VERSION "dbc-export 1 2026.26.6.5"

NS_ :

BS_:

BU_: ADSP APB APP APS APSB BB BMS CC CMP CMPD CP DAS DI DIF DIR DPB EPAS3P EPAS3S EPASTP EPASTS EPBL EPBR ESP EVSE FC GTW HCML HCMR HVP IBST ICR IDB LS OCS1P ODIN PARK PCS PCS2 PLG PM PMF PMR PNCD PTC RADC RCM RCM2 RCM3 RCU SCCM SCM SCS SDCR TAS TCU TCU2 TPMS TRCM UDS UI UIS UMC USM V2G VC VCBATT VCBATT0 VCBATT1 VCBATT2 VCCC VCFRONT VCFRONT1 VCFRONT2 VCLEFT VCRIGHT VCSEAT2L VCSEAT2R VCSEC VEH

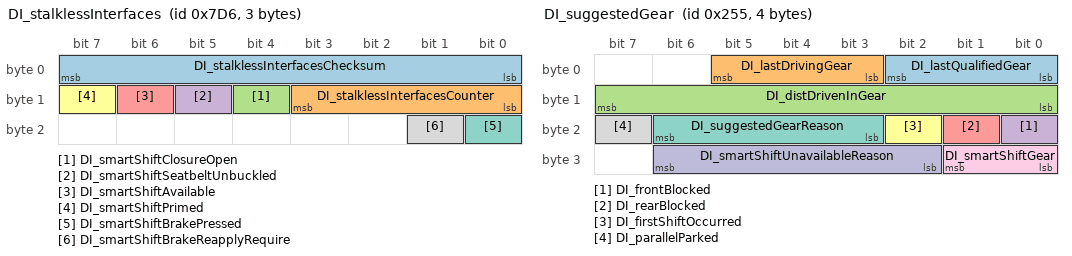
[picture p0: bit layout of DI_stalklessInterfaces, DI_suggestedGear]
BO_ 2006 DI_stalklessInterfaces: 3 DI
 SG_ DI_stalklessInterfacesChecksum : 0|8@1+ (1,0) [0|255] "" Vector__XXX
 SG_ DI_stalklessInterfacesCounter : 8|4@1+ (1,0) [0|15] "" Vector__XXX
 SG_ DI_smartShiftClosureOpen : 12|1@1+ (1,0) [0|1] "" Vector__XXX
 SG_ DI_smartShiftSeatbeltUnbuckled : 13|1@1+ (1,0) [0|1] "" Vector__XXX
 SG_ DI_smartShiftAvailable : 14|1@1+ (1,0) [0|1] "" Vector__XXX
 SG_ DI_smartShiftPrimed : 15|1@1+ (1,0) [0|1] "" Vector__XXX
 SG_ DI_smartShiftBrakePressed : 16|1@1+ (1,0) [0|1] "" Vector__XXX
 SG_ DI_smartShiftBrakeReapplyRequire : 17|1@1+ (1,0) [0|1] "" Vector__XXX

BO_ 597 DI_suggestedGear: 4 DI
 SG_ DI_lastQualifiedGear : 0|3@1+ (1,0) [0|6] "" Vector__XXX
 SG_ DI_lastDrivingGear : 3|3@1+ (1,0) [0|6] "" Vector__XXX
 SG_ DI_distDrivenInGear : 8|8@1+ (0.0235294122249,0) [0|6] "m" Vector__XXX
 SG_ DI_frontBlocked : 16|1@1+ (1,0) [0|1] "" Vector__XXX
 SG_ DI_rearBlocked : 17|1@1+ (1,0) [0|1] "" Vector__XXX
 SG_ DI_firstShiftOccurred : 18|1@1+ (1,0) [0|1] "" Vector__XXX
 SG_ DI_suggestedGearReason : 19|4@1+ (1,0) [0|15] "" Vector__XXX
 SG_ DI_parallelParked : 23|1@1+ (1,0) [0|1] "" Vector__XXX
 SG_ DI_smartShiftGear : 24|2@1+ (1,0) [0|3] "" Vector__XXX
 SG_ DI_smartShiftUnavailableReason : 26|5@1+ (1,0) [1|31] "" Vector__XXX

BO_ 296 DI_systemLimits: 6 DI
 SG_ DI_limitRegenPower : 0|1@1+ (1,0) [0|1] "" Vector__XXX
 SG_ DI_limitIBat : 1|1@1+ (1,0) [0|1] "" Vector__XXX
 SG_ DI_limitVBatLow : 2|1@1+ (1,0) [0|1] "" Vector__XXX
 SG_ DI_limitVBatHigh : 3|1@1+ (1,0) [0|1] "" Vector__XXX
 SG_ DI_limitObstacleDetection : 4|1@1+ (1,0) [0|1] "" Vector__XXX
 SG_ DI_limitSystemLimp : 5|1@1+ (1,0) [0|1] "" Vector__XXX
 SG_ DI_limitSystemGPO : 6|1@1+ (1,0) [0|1] "" Vector__XXX
 SG_ DI_limitShift : 7|1@1+ (1,0) [0|1] "" Vector__XXX
 SG_ DI_limitDriveTorque : 8|1@1+ (1,0) [0|1] "" Vector__XXX
 SG_ DI_limitRegenTorque : 9|1@1+ (1,0) [0|1] "" Vector__XXX
 SG_ DI_limitVehicleSpeed : 10|1@1+ (1,0) [0|1] "" Vector__XXX
 SG_ DI_limitBmsMiaFreeze : 11|1@1+ (1,0) [0|1] "" Vector__XXX
 SG_ DI_limitSystemSpinDownLearning : 12|1@1+ (1,0) [0|1] "" Vector__XXX
 SG_ DI_limitCdp : 13|1@1+ (1,0) [0|1] "" Vector__XXX
 SG_ DI_vehicleSpeedLimitType : 14|2@1+ (1,0) [0|3] "" Vector__XXX
 SG_ DI_vehicleSpeedLimit : 16|9@1+ (1,0) [0|510] "kph" Vector__XXX
 SG_ DI_vehicleSpeedLimitReason : 25|5@1+ (1,0) [0|31] "" Vector__XXX
 SG_ DI_proximity : 30|1@1+ (1,0) [0|1] "" Vector__XXX
 SG_ DI_limitClosureNotClosed : 31|1@1+ (1,0) [0|1] "" Vector__XXX
 SG_ DI_undersideAbuse : 32|1@1+ (1,0) [0|1] "" Vector__XXX
 SG_ DI_immobilizerAuthLevel : 33|2@1+ (1,0) [0|3] "" Vector__XXX
 SG_ DI_manualRecoveryDistanceRemaini : 40|7@1+ (5,0) [0|500] "m" Vector__XXX
 SG_ DI_restrictedDrivingMode : 47|1@1+ (1,0) [0|1] "" Vector__XXX

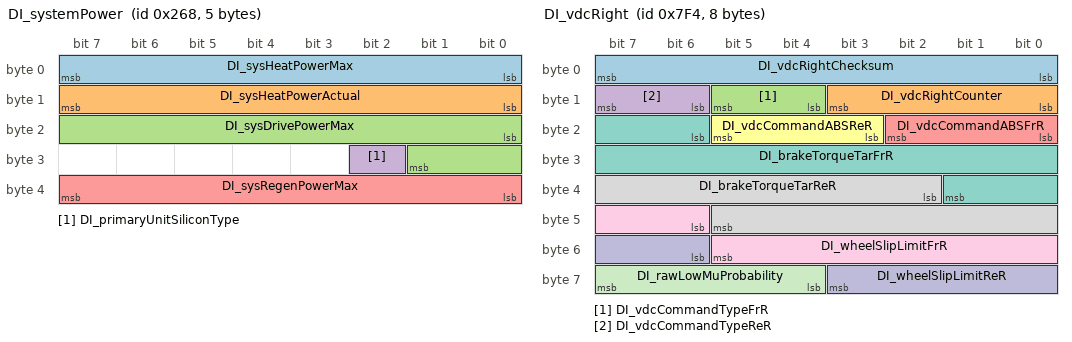
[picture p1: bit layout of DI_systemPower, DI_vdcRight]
BO_ 616 DI_systemPower: 5 DI
 SG_ DI_sysHeatPowerMax : 0|8@1+ (0.08,0) [0|20] "kW" Vector__XXX
 SG_ DI_sysHeatPowerActual : 8|8@1+ (0.08,0) [0|20] "kW" Vector__XXX
 SG_ DI_sysDrivePowerMax : 16|10@1+ (1,0) [0|1023] "kW" Vector__XXX
 SG_ DI_primaryUnitSiliconType : 26|1@1+ (1,0) [0|1] "" Vector__XXX
 SG_ DI_sysRegenPowerMax : 32|8@1+ (1,-100) [-100|0] "kW" Vector__XXX

BO_ 280 DI_systemStatus: 8 DI
 SG_ DI_systemStatusChecksum : 0|8@1+ (1,0) [0|255] "" Vector__XXX
 SG_ DI_systemStatusCounter : 8|4@1+ (1,0) [0|15] "" Vector__XXX
 SG_ DI_secondaryGearControlStatus : 12|1@1+ (1,0) [0|1] "" Vector__XXX
 SG_ DI_immobilizerState : 13|3@1+ (1,0) [1|7] "" Vector__XXX
 SG_ DI_systemState : 16|3@1+ (1,0) [0|7] "" Vector__XXX
 SG_ DI_brakePedalState : 19|2@1+ (1,0) [0|3] "" Vector__XXX
 SG_ DI_gear : 21|3@1+ (1,0) [0|6] "" Vector__XXX
 SG_ DI_driveBlocked : 24|3@1+ (1,0) [0|7] "" Vector__XXX
 SG_ DI_hvilSystemStatus : 27|2@1+ (1,0) [0|2] "" Vector__XXX
 SG_ DI_driveModeState : 29|1@1+ (1,0) [0|1] "" Vector__XXX
 SG_ DI_shiftRequestType : 30|2@1+ (1,0) [0|3] "" Vector__XXX
 SG_ DI_accelPedalPos : 32|8@1+ (0.4,0) [0|100] "%" Vector__XXX
 SG_ DI_tractionControlMode : 40|3@1+ (1,0) [0|7] "" Vector__XXX
 SG_ DI_dynoModeAvailable : 43|1@1+ (1,0) [0|1] "" Vector__XXX
 SG_ DI_epbRequest : 44|2@1+ (1,0) [0|3] "" Vector__XXX
 SG_ DI_brakeSource : 46|1@1+ (1,0) [0|1] "" Vector__XXX
 SG_ DI_keepDrivePowerStateRequest : 47|1@1+ (1,0) [0|1] "" Vector__XXX
 SG_ DI_trackModeState : 48|2@1+ (1,0) [0|3] "" Vector__XXX
 SG_ DI_autonomyControlActive : 50|1@1+ (1,0) [0|1] "" Vector__XXX
 SG_ DI_regenLight : 51|1@1+ (1,0) [0|1] "" Vector__XXX
 SG_ DI_vehicleAcceleration : 52|12@1- (0.01,0) [-20.47|20.47] "m/s^2" Vector__XXX

BO_ 2036 DI_vdcRight: 8 DI
 SG_ DI_vdcRightChecksum : 0|8@1+ (1,0) [0|255] "" Vector__XXX
 SG_ DI_vdcRightCounter : 8|4@1+ (1,0) [0|15] "" Vector__XXX
 SG_ DI_vdcCommandTypeFrR : 12|2@1+ (1,0) [0|3] "" Vector__XXX
 SG_ DI_vdcCommandTypeReR : 14|2@1+ (1,0) [0|3] "" Vector__XXX
 SG_ DI_vdcCommandABSFrR : 16|3@1+ (1,0) [0|7] "" Vector__XXX
 SG_ DI_vdcCommandABSReR : 19|3@1+ (1,0) [0|7] "" Vector__XXX
 SG_ DI_brakeTorqueTarFrR : 22|12@1+ (3,-3) [-3|12282] "Nm" Vector__XXX
 SG_ DI_brakeTorqueTarReR : 34|12@1+ (3,-3) [-3|12282] "Nm" Vector__XXX
 SG_ DI_wheelSlipLimitFrR : 46|8@1+ (0.004,-0.004) [-0.004|1] "1" Vector__XXX
 SG_ DI_wheelSlipLimitReR : 54|6@1+ (0.004,-0.004) [-0.004|0.248] "1" Vector__XXX
 SG_ DI_rawLowMuProbability : 60|4@1+ (0.06666667,0) [0|1] "-" Vector__XXX

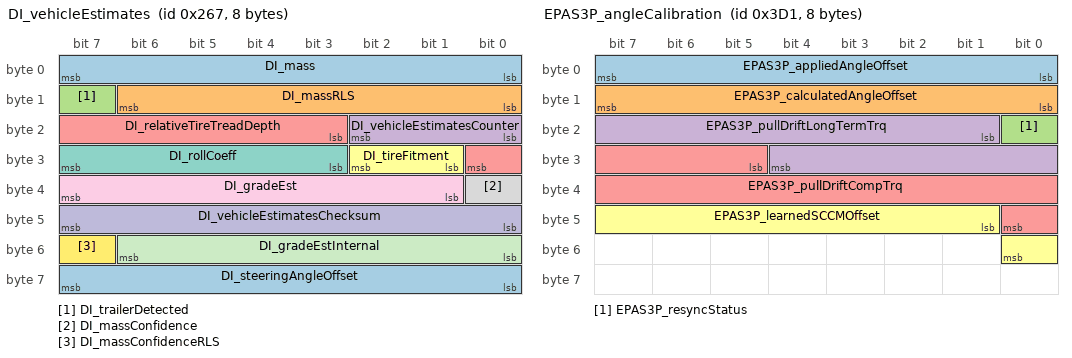
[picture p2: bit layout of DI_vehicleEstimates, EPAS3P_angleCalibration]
BO_ 615 DI_vehicleEstimates: 8 DI
 SG_ DI_mass : 0|8@1+ (25,1500) [1500|7850] "kg" Vector__XXX
 SG_ DI_massRLS : 8|7@1+ (45,1500) [1500|7170] "kg" Vector__XXX
 SG_ DI_trailerDetected : 15|1@1+ (1,0) [0|1] "" Vector__XXX
 SG_ DI_vehicleEstimatesCounter : 16|3@1+ (1,0) [0|7] "" Vector__XXX
 SG_ DI_relativeTireTreadDepth : 19|6@1- (0.4,0) [-12.4|12.4] "mm" Vector__XXX
 SG_ DI_tireFitment : 25|2@1+ (1,0) [0|2] "" Vector__XXX
 SG_ DI_rollCoeff : 27|5@1+ (0.001,0) [0|0.03] "g" Vector__XXX
 SG_ DI_massConfidence : 32|1@1+ (1,0) [0|1] "" Vector__XXX
 SG_ DI_gradeEst : 33|7@1- (1,0) [-40|40] "%" Vector__XXX
 SG_ DI_vehicleEstimatesChecksum : 40|8@1+ (1,0) [0|255] "" Vector__XXX
 SG_ DI_gradeEstInternal : 48|7@1- (1,0) [-40|40] "%" Vector__XXX
 SG_ DI_massConfidenceRLS : 55|1@1+ (1,0) [0|1] "" Vector__XXX
 SG_ DI_steeringAngleOffset : 56|8@1- (0.2,0) [-25.6|25.4] "Deg" Vector__XXX

BO_ 1237 DPB_alertLog: 8 DPB
 SG_ DPB_alertID : 0|9@1+ (1,0) [0|511] "" Vector__XXX
 SG_ DPB_alertState : 15|1@1+ (1,0) [0|1] "" Vector__XXX

BO_ 999 DPB_alertMatrix: 8 DPB
 SG_ DPB_matrixIndex M : 0|4@1+ (1,0) [0|15] "" Vector__XXX
 SG_ DPB_a001_pPlungerSensorOffsetHig m0 : 4|1@1+ (1,0) [0|1] "" Vector__XXX
 SG_ DPB_a002_pMC2SensorOffsetHigh m0 : 5|1@1+ (1,0) [0|1] "" Vector__XXX
 SG_ DPB_a003_AswEEPROMReadFailure m0 : 6|1@1+ (1,0) [0|1] "" Vector__XXX
 SG_ DPB_a004_assertionFault m0 : 7|1@1+ (1,0) [0|1] "" Vector__XXX
 SG_ DPB_a005_hardPedalChar m0 : 8|1@1+ (1,0) [0|1] "" Vector__XXX
 SG_ DPB_a006_hardPedalCharGoodCheck m0 : 9|1@1+ (1,0) [0|1] "" Vector__XXX
 SG_ DPB_a007_PMCLeakageDetected m0 : 10|1@1+ (1,0) [0|1] "" Vector__XXX
 SG_ DPB_a008_LiPSPts1Offset m0 : 11|1@1+ (1,0) [0|1] "" Vector__XXX
 SG_ DPB_a009_LiPSPts2Offset m0 : 12|1@1+ (1,0) [0|1] "" Vector__XXX
 SG_ DPB_a010_LiPSPtsConsistency m0 : 13|1@1+ (1,0) [0|1] "" Vector__XXX
 SG_ DPB_a011_PtsNonZeroStage1 m0 : 14|1@1+ (1,0) [0|1] "" Vector__XXX
 SG_ DPB_a012_PtsNonZeroStage2 m0 : 15|1@1+ (1,0) [0|1] "" Vector__XXX
 SG_ DPB_a013_softPedalChar m0 : 16|1@1+ (1,0) [0|1] "" Vector__XXX
 SG_ DPB_a014_CANControllerHWFault m0 : 17|1@1+ (1,0) [0|1] "" Vector__XXX
 SG_ DPB_a015_CAN1BusOff m0 : 18|1@1+ (1,0) [0|1] "" Vector__XXX
 SG_ DPB_a016_CAN2BusOff m0 : 19|1@1+ (1,0) [0|1] "" Vector__XXX
 SG_ DPB_a017_largeLeakageDetected m0 : 20|1@1+ (1,0) [0|1] "" Vector__XXX
 SG_ DPB_a018_largeLeakageDetectedGoo m0 : 21|1@1+ (1,0) [0|1] "" Vector__XXX
 SG_ DPB_a019_DETReportError m0 : 22|1@1+ (1,0) [0|1] "" Vector__XXX
 SG_ DPB_a020_ecuHuMismatch m0 : 23|1@1+ (1,0) [0|1] "" Vector__XXX
 SG_ DPB_a021_brakeSystemOverheatLvl1 m0 : 24|1@1+ (1,0) [0|1] "" Vector__XXX
 SG_ DPB_a022_brakeSystemOverheatLvl2 m0 : 25|1@1+ (1,0) [0|1] "" Vector__XXX
 SG_ DPB_a023_initialPlungerCheckFail m0 : 26|1@1+ (1,0) [0|1] "" Vector__XXX
 SG_ DPB_a024_ESPLDMFailure m0 : 27|1@1+ (1,0) [0|1] "" Vector__XXX
 SG_ DPB_a025_backupCircuitLeakage m0 : 28|1@1+ (1,0) [0|1] "" Vector__XXX
 SG_ DPB_a026_LiPSIDTimeout m0 : 29|1@1+ (1,0) [0|1] "" Vector__XXX
 SG_ DPB_a027_motorTempHighLevel1 m0 : 30|1@1+ (1,0) [0|1] "" Vector__XXX
 SG_ DPB_a028_motorTempHighLevel2 m0 : 31|1@1+ (1,0) [0|1] "" Vector__XXX
 SG_ DPB_a029_motorTestFault m0 : 32|1@1+ (1,0) [0|1] "" Vector__XXX
 SG_ DPB_a030_notShutDownRight m0 : 33|1@1+ (1,0) [0|1] "" Vector__XXX
 SG_ DPB_a031_HWParamReadFailed m0 : 34|1@1+ (1,0) [0|1] "" Vector__XXX
 SG_ DPB_a032_HWParamWriteFailed m0 : 35|1@1+ (1,0) [0|1] "" Vector__XXX
 SG_ DPB_a033_motorDynamicLimited m0 : 36|1@1+ (1,0) [0|1] "" Vector__XXX
 SG_ DPB_a034_lipsMemoryEmpty m0 : 37|1@1+ (1,0) [0|1] "" Vector__XXX
 SG_ DPB_a035_PDURouterinitialization m0 : 38|1@1+ (1,0) [0|1] "" Vector__XXX
 SG_ DPB_a036_lossOfPDUInstanceDetect m0 : 39|1@1+ (1,0) [0|1] "" Vector__XXX
 SG_ DPB_a037_plungerCircuitPressHigh m0 : 40|1@1+ (1,0) [0|1] "" Vector__XXX
 SG_ DPB_a038_plungerCircuitPressHigh m0 : 41|1@1+ (1,0) [0|1] "" Vector__XXX
 SG_ DPB_a039_plungerCircuitPressLow m0 : 42|1@1+ (1,0) [0|1] "" Vector__XXX
 SG_ DPB_a040_plungerCircuitPressLowG m0 : 43|1@1+ (1,0) [0|1] "" Vector__XXX
 SG_ DPB_a041_PSCGearRatioReadFault m0 : 44|1@1+ (1,0) [0|1] "" Vector__XXX
 SG_ DPB_a042_motorLoadPressImplausib m0 : 45|1@1+ (1,0) [0|1] "" Vector__XXX
 SG_ DPB_a043_PSCMotorSizeReadFault m0 : 46|1@1+ (1,0) [0|1] "" Vector__XXX
 SG_ DPB_a044_supplyOvervoltageLvl1 m0 : 47|1@1+ (1,0) [0|1] "" Vector__XXX
 SG_ DPB_a045_supplyOvervoltageLvl2 m0 : 48|1@1+ (1,0) [0|1] "" Vector__XXX
 SG_ DPB_a046_supplyOvervoltageLvl3 m0 : 49|1@1+ (1,0) [0|1] "" Vector__XXX
 SG_ DPB_a047_pPlungerPlausCheckFailu m0 : 50|1@1+ (1,0) [0|1] "" Vector__XXX
 SG_ DPB_a048_supplyUndervoltageLvl1 m0 : 51|1@1+ (1,0) [0|1] "" Vector__XXX
 SG_ DPB_a049_supplyUndervoltageLvl2 m0 : 52|1@1+ (1,0) [0|1] "" Vector__XXX
 SG_ DPB_a050_supplyUndervoltageLvl3 m0 : 53|1@1+ (1,0) [0|1] "" Vector__XXX
 SG_ DPB_a051_PSCVoltageImplausible m0 : 54|1@1+ (1,0) [0|1] "" Vector__XXX
 SG_ DPB_a052_PSIDTimeOut m0 : 55|1@1+ (1,0) [0|1] "" Vector__XXX
 SG_ DPB_a053_hydraulicAssemblyModeAc m0 : 56|1@1+ (1,0) [0|1] "" Vector__XXX
 SG_ DPB_a054_unsupportedHW m0 : 57|1@1+ (1,0) [0|1] "" Vector__XXX
 SG_ DPB_a055_unsupportedSeriesHWDete m0 : 58|1@1+ (1,0) [0|1] "" Vector__XXX
 SG_ DPB_a056_AdcPeripheralFault m0 : 59|1@1+ (1,0) [0|1] "" Vector__XXX
 SG_ DPB_a057_AdcPinTest m0 : 60|1@1+ (1,0) [0|1] "" Vector__XXX
 SG_ DPB_a058_AdcSelftestC5P m0 : 61|1@1+ (1,0) [0|1] "" Vector__XXX
 SG_ DPB_a059_factoryModeActive m0 : 62|1@1+ (1,0) [0|1] "" Vector__XXX
 SG_ DPB_a060_motorBridgeDriverFault m0 : 63|1@1+ (1,0) [0|1] "" Vector__XXX
 SG_ DPB_a061_bridgeSwitchInitError m1 : 4|1@1+ (1,0) [0|1] "" Vector__XXX
 SG_ DPB_a062_loadDumpOnFSLTest m1 : 5|1@1+ (1,0) [0|1] "" Vector__XXX
 SG_ DPB_a063_motorConfigMismatch m1 : 6|1@1+ (1,0) [0|1] "" Vector__XXX
 SG_ DPB_a064_current1OffsetHigh m1 : 7|1@1+ (1,0) [0|1] "" Vector__XXX
 SG_ DPB_a065_current1OffsetLow m1 : 8|1@1+ (1,0) [0|1] "" Vector__XXX
 SG_ DPB_a066_current2OffsetHigh m1 : 9|1@1+ (1,0) [0|1] "" Vector__XXX
 SG_ DPB_a067_current2OffsetLow m1 : 10|1@1+ (1,0) [0|1] "" Vector__XXX
 SG_ DPB_a068_BLMMuxerTimeoutError m1 : 11|1@1+ (1,0) [0|1] "" Vector__XXX
 SG_ DPB_a069_OBDCurrent1OORHigh m1 : 12|1@1+ (1,0) [0|1] "" Vector__XXX
 SG_ DPB_a070_OBDCurrent1OORLow m1 : 13|1@1+ (1,0) [0|1] "" Vector__XXX
 SG_ DPB_a071_OBDCurrent2OORHigh m1 : 14|1@1+ (1,0) [0|1] "" Vector__XXX
 SG_ DPB_a072_OBDCurrent2OORLow m1 : 15|1@1+ (1,0) [0|1] "" Vector__XXX
 SG_ DPB_a073_rotorCosOutOfRangeHigh m1 : 16|1@1+ (1,0) [0|1] "" Vector__XXX
 SG_ DPB_a074_rotorCosOutOfRangeLow m1 : 17|1@1+ (1,0) [0|1] "" Vector__XXX
 SG_ DPB_a075_rotorSinOutOfRangeHigh m1 : 18|1@1+ (1,0) [0|1] "" Vector__XXX
 SG_ DPB_a076_rotorSinOutOfRangeLow m1 : 19|1@1+ (1,0) [0|1] "" Vector__XXX
 SG_ DPB_a077_tempSens1ShortToSupply m1 : 20|1@1+ (1,0) [0|1] "" Vector__XXX
 SG_ DPB_a078_tempSens1ShortToGround m1 : 21|1@1+ (1,0) [0|1] "" Vector__XXX
 SG_ DPB_a079_tempSens2ShortToSupply m1 : 22|1@1+ (1,0) [0|1] "" Vector__XXX
 SG_ DPB_a080_tempSens2ShortToGround m1 : 23|1@1+ (1,0) [0|1] "" Vector__XXX
 SG_ DPB_a081_tempSensImplausVoltage m1 : 24|1@1+ (1,0) [0|1] "" Vector__XXX
 SG_ DPB_a082_chargePumpFault m1 : 25|1@1+ (1,0) [0|1] "" Vector__XXX
 SG_ DPB_a083_chargePumpUndervoltage m1 : 26|1@1+ (1,0) [0|1] "" Vector__XXX
 SG_ DPB_a084_RBCPUException m1 : 27|1@1+ (1,0) [0|1] "" Vector__XXX
 SG_ DPB_a085_infoFailureWrongCUBASHa m1 : 28|1@1+ (1,0) [0|1] "" Vector__XXX
 SG_ DPB_a086_diagHydProtectionPressF m1 : 29|1@1+ (1,0) [0|1] "" Vector__XXX
 SG_ DPB_a087_diagHydProtectionVlvFau m1 : 30|1@1+ (1,0) [0|1] "" Vector__XXX
 SG_ DPB_a088_DMATransferError m1 : 31|1@1+ (1,0) [0|1] "" Vector__XXX
 SG_ DPB_a089_ecuBandgap m1 : 32|1@1+ (1,0) [0|1] "" Vector__XXX
 SG_ DPB_a090_flashFault m1 : 33|1@1+ (1,0) [0|1] "" Vector__XXX
 SG_ DPB_a091_MRGPathTestFault m1 : 34|1@1+ (1,0) [0|1] "" Vector__XXX
 SG_ DPB_a092_decoupleBitTestFault m1 : 35|1@1+ (1,0) [0|1] "" Vector__XXX
 SG_ DPB_a093_ecuBistFaultCtrFault m1 : 36|1@1+ (1,0) [0|1] "" Vector__XXX
 SG_ DPB_a094_ecuClockTestFault m1 : 37|1@1+ (1,0) [0|1] "" Vector__XXX
 SG_ DPB_a095_ecuEnableElHighFault m1 : 38|1@1+ (1,0) [0|1] "" Vector__XXX
 SG_ DPB_a096_ecuEnableElLowFault m1 : 39|1@1+ (1,0) [0|1] "" Vector__XXX
 SG_ DPB_a097_ecuEnableHyHighFault m1 : 40|1@1+ (1,0) [0|1] "" Vector__XXX
 SG_ DPB_a098_ecuEnableHyLowFault m1 : 41|1@1+ (1,0) [0|1] "" Vector__XXX
 SG_ DPB_a099_ecuEnContinuousError m1 : 42|1@1+ (1,0) [0|1] "" Vector__XXX
 SG_ DPB_a100_ecuErrpinCounterFault m1 : 43|1@1+ (1,0) [0|1] "" Vector__XXX
 SG_ DPB_a101_ecuFastWdTestFault m1 : 44|1@1+ (1,0) [0|1] "" Vector__XXX
 SG_ DPB_a102_ecuVrOnWhileWdTimeout m1 : 45|1@1+ (1,0) [0|1] "" Vector__XXX
 SG_ DPB_a103_ecuVrViaSpiFails m1 : 46|1@1+ (1,0) [0|1] "" Vector__XXX
 SG_ DPB_a104_ecuWdStartuptestFault m1 : 47|1@1+ (1,0) [0|1] "" Vector__XXX
 SG_ DPB_a105_ecuWdSContinuousError m1 : 48|1@1+ (1,0) [0|1] "" Vector__XXX
 SG_ DPB_a106_ecuBistCmdTestFault m1 : 49|1@1+ (1,0) [0|1] "" Vector__XXX
 SG_ DPB_a107_vrOnFails m1 : 50|1@1+ (1,0) [0|1] "" Vector__XXX
 SG_ DPB_a108_GTMRefFrequencyError m1 : 51|1@1+ (1,0) [0|1] "" Vector__XXX
 SG_ DPB_a109_GTMTbuMonError m1 : 52|1@1+ (1,0) [0|1] "" Vector__XXX
 SG_ DPB_a110_HWBISTError m1 : 53|1@1+ (1,0) [0|1] "" Vector__XXX
 SG_ DPB_a111_hydraulicHardUndervolta m1 : 54|1@1+ (1,0) [0|1] "" Vector__XXX
 SG_ DPB_a112_hydraulicUndervoltage m1 : 55|1@1+ (1,0) [0|1] "" Vector__XXX
 SG_ DPB_a113_LiPS1SentLineHigh m1 : 56|1@1+ (1,0) [0|1] "" Vector__XXX
 SG_ DPB_a114_LiPS1SentLineLow m1 : 57|1@1+ (1,0) [0|1] "" Vector__XXX
 SG_ DPB_a115_LiPS1SentSensor m1 : 58|1@1+ (1,0) [0|1] "" Vector__XXX
 SG_ DPB_a116_LiPS1SentTransmission m1 : 59|1@1+ (1,0) [0|1] "" Vector__XXX
 SG_ DPB_a117_LiPS2PwmLineHigh m1 : 60|1@1+ (1,0) [0|1] "" Vector__XXX
 SG_ DPB_a118_LiPS2PwmLineLow m1 : 61|1@1+ (1,0) [0|1] "" Vector__XXX
 SG_ DPB_a119_LiPS2PwmTransmission m1 : 62|1@1+ (1,0) [0|1] "" Vector__XXX
 SG_ DPB_a120_LiPSOutOfRangeHigh m1 : 63|1@1+ (1,0) [0|1] "" Vector__XXX
 SG_ DPB_a121_LiPSOutOfRangeLow m2 : 4|1@1+ (1,0) [0|1] "" Vector__XXX
 SG_ DPB_a122_micAsicClkInError m2 : 5|1@1+ (1,0) [0|1] "" Vector__XXX
 SG_ DPB_a123_micAsicInitTestError m2 : 6|1@1+ (1,0) [0|1] "" Vector__XXX
 SG_ DPB_a124_asicOscillatorError m2 : 7|1@1+ (1,0) [0|1] "" Vector__XXX
 SG_ DPB_a125_B6AsicFault m2 : 8|1@1+ (1,0) [0|1] "" Vector__XXX
 SG_ DPB_a126_MICB6TransferError m2 : 9|1@1+ (1,0) [0|1] "" Vector__XXX
 SG_ DPB_a127_hydraulicAsicShortCircu m2 : 10|1@1+ (1,0) [0|1] "" Vector__XXX
 SG_ DPB_a128_micSpiTransferError m2 : 11|1@1+ (1,0) [0|1] "" Vector__XXX
 SG_ DPB_a129_AsicTrimmingNotComplete m2 : 12|1@1+ (1,0) [0|1] "" Vector__XXX
 SG_ DPB_a130_AsicMalfunctionDetected m2 : 13|1@1+ (1,0) [0|1] "" Vector__XXX
 SG_ DPB_a131_ASICOvercurrentOnGPIO25 m2 : 14|1@1+ (1,0) [0|1] "" Vector__XXX
 SG_ DPB_a132_ASICOvercurrentOnGPIO25 m2 : 15|1@1+ (1,0) [0|1] "" Vector__XXX
 SG_ DPB_a133_ASICOvercurrentOnGPIO50 m2 : 16|1@1+ (1,0) [0|1] "" Vector__XXX
 SG_ DPB_a134_ASICOvercurrentOnGPIO50 m2 : 17|1@1+ (1,0) [0|1] "" Vector__XXX
 SG_ DPB_a135_ASICOvercurrentOnGPIO50 m2 : 18|1@1+ (1,0) [0|1] "" Vector__XXX
 SG_ DPB_a136_ASICOvercurrentOnGPIO50 m2 : 19|1@1+ (1,0) [0|1] "" Vector__XXX
 SG_ DPB_a137_ASICOvercurrentOnWRHS m2 : 20|1@1+ (1,0) [0|1] "" Vector__XXX
 SG_ DPB_a138_DIchassisControlCounter m2 : 21|1@1+ (1,0) [0|1] "" Vector__XXX
 SG_ DPB_a139_DIchassisControlChecksu m2 : 22|1@1+ (1,0) [0|1] "" Vector__XXX
 SG_ DPB_a140_DIchassisControlDLC m2 : 23|1@1+ (1,0) [0|1] "" Vector__XXX
 SG_ DPB_a141_DIchassisControlTimeout m2 : 24|1@1+ (1,0) [0|1] "" Vector__XXX
 SG_ DPB_a142_DIsystemStatusCounter m2 : 25|1@1+ (1,0) [0|1] "" Vector__XXX
 SG_ DPB_a143_DIsystemStatusChecksum m2 : 26|1@1+ (1,0) [0|1] "" Vector__XXX
 SG_ DPB_a144_DIsystemStatusDLC m2 : 27|1@1+ (1,0) [0|1] "" Vector__XXX
 SG_ DPB_a145_DIsystemStatusTimeout m2 : 28|1@1+ (1,0) [0|1] "" Vector__XXX
 SG_ DPB_a146_DIFtorqueCounter m2 : 29|1@1+ (1,0) [0|1] "" Vector__XXX
 SG_ DPB_a147_DIFtorqueChecksum m2 : 30|1@1+ (1,0) [0|1] "" Vector__XXX
 SG_ DPB_a148_DIFtorqueDLC m2 : 31|1@1+ (1,0) [0|1] "" Vector__XXX
 SG_ DPB_a149_DIFtorqueTimeout m2 : 32|1@1+ (1,0) [0|1] "" Vector__XXX
 SG_ DPB_a150_DIRtorqueCounter m2 : 33|1@1+ (1,0) [0|1] "" Vector__XXX
 SG_ DPB_a151_DIRtorqueChecksum m2 : 34|1@1+ (1,0) [0|1] "" Vector__XXX
 SG_ DPB_a152_DIRtorqueDLC m2 : 35|1@1+ (1,0) [0|1] "" Vector__XXX
 SG_ DPB_a153_DIRtorqueTimeout m2 : 36|1@1+ (1,0) [0|1] "" Vector__XXX
 SG_ DPB_a154_EPBLstatusCounter m2 : 37|1@1+ (1,0) [0|1] "" Vector__XXX
 SG_ DPB_a155_EPBLstatusChecksum m2 : 38|1@1+ (1,0) [0|1] "" Vector__XXX
 SG_ DPB_a156_EPBLstatusDLC m2 : 39|1@1+ (1,0) [0|1] "" Vector__XXX
 SG_ DPB_a157_EPBLstatusTimeout m2 : 40|1@1+ (1,0) [0|1] "" Vector__XXX
 SG_ DPB_a158_EPBRstatusCounter m2 : 41|1@1+ (1,0) [0|1] "" Vector__XXX
 SG_ DPB_a159_EPBRstatusChecksum m2 : 42|1@1+ (1,0) [0|1] "" Vector__XXX
 SG_ DPB_a160_EPBRstatusDLC m2 : 43|1@1+ (1,0) [0|1] "" Vector__XXX
 SG_ DPB_a161_EPBRstatusTimeout m2 : 44|1@1+ (1,0) [0|1] "" Vector__XXX
 SG_ DPB_a162_ESP_modulator1Counter m2 : 45|1@1+ (1,0) [0|1] "" Vector__XXX
 SG_ DPB_a163_ESP_modulator1Checksum m2 : 46|1@1+ (1,0) [0|1] "" Vector__XXX
 SG_ DPB_a164_ESP_modulator1DLC m2 : 47|1@1+ (1,0) [0|1] "" Vector__XXX
 SG_ DPB_a165_ESP_modulator1Timeout m2 : 48|1@1+ (1,0) [0|1] "" Vector__XXX
 SG_ DPB_a166_ESP_chassis3Counter m2 : 49|1@1+ (1,0) [0|1] "" Vector__XXX
 SG_ DPB_a167_ESP_chassis3Checksum m2 : 50|1@1+ (1,0) [0|1] "" Vector__XXX
 SG_ DPB_a168_ESP_chassis3DLC m2 : 51|1@1+ (1,0) [0|1] "" Vector__XXX
 SG_ DPB_a169_ESP_chassis3Timeout m2 : 52|1@1+ (1,0) [0|1] "" Vector__XXX
 SG_ DPB_a170_ESP_modulator2Counter m2 : 53|1@1+ (1,0) [0|1] "" Vector__XXX
 SG_ DPB_a171_ESP_modulator2Checksum m2 : 54|1@1+ (1,0) [0|1] "" Vector__XXX
 SG_ DPB_a172_ESP_modulator2DLC m2 : 55|1@1+ (1,0) [0|1] "" Vector__XXX
 SG_ DPB_a173_ESP_modulator2Timeout m2 : 56|1@1+ (1,0) [0|1] "" Vector__XXX
 SG_ DPB_a174_ESP_modulator3Counter m2 : 57|1@1+ (1,0) [0|1] "" Vector__XXX
 SG_ DPB_a175_ESP_modulator3Checksum m2 : 58|1@1+ (1,0) [0|1] "" Vector__XXX
 SG_ DPB_a176_ESP_modulator3DLC m2 : 59|1@1+ (1,0) [0|1] "" Vector__XXX
 SG_ DPB_a177_ESP_modulator3Timeout m2 : 60|1@1+ (1,0) [0|1] "" Vector__XXX
 SG_ DPB_a178_PMstate2Counter m2 : 61|1@1+ (1,0) [0|1] "" Vector__XXX
 SG_ DPB_a179_PMstate2Checksum m2 : 62|1@1+ (1,0) [0|1] "" Vector__XXX
 SG_ DPB_a180_PMstate2DLC m2 : 63|1@1+ (1,0) [0|1] "" Vector__XXX
 SG_ DPB_a181_PMstate2Timeout m3 : 4|1@1+ (1,0) [0|1] "" Vector__XXX
 SG_ DPB_a182_RCMInertial2Counter m3 : 5|1@1+ (1,0) [0|1] "" Vector__XXX
 SG_ DPB_a183_RCMInertial2Checksum m3 : 6|1@1+ (1,0) [0|1] "" Vector__XXX
 SG_ DPB_a184_RCMInertial2DLC m3 : 7|1@1+ (1,0) [0|1] "" Vector__XXX
 SG_ DPB_a185_RCMInertial2Timeout m3 : 8|1@1+ (1,0) [0|1] "" Vector__XXX
 SG_ DPB_a186_LVPowerStateTimeout m3 : 9|1@1+ (1,0) [0|1] "" Vector__XXX
 SG_ DPB_a187_LVPowerStateChecksum m3 : 10|1@1+ (1,0) [0|1] "" Vector__XXX
 SG_ DPB_a188_LVPowerStateDLC m3 : 11|1@1+ (1,0) [0|1] "" Vector__XXX
 SG_ DPB_a189_LVPowerStateCounter m3 : 12|1@1+ (1,0) [0|1] "" Vector__XXX
 SG_ DPB_a190_VCLEFTepbmStatusCounter m3 : 13|1@1+ (1,0) [0|1] "" Vector__XXX
 SG_ DPB_a191_VCLEFTepbmStatusChecksu m3 : 14|1@1+ (1,0) [0|1] "" Vector__XXX
 SG_ DPB_a192_VCLEFTepbmStatusDLC m3 : 15|1@1+ (1,0) [0|1] "" Vector__XXX
 SG_ DPB_a193_VCLEFTepbmStatusTimeout m3 : 16|1@1+ (1,0) [0|1] "" Vector__XXX
 SG_ DPB_a194_VCRIGHTepbmStatusCounte m3 : 17|1@1+ (1,0) [0|1] "" Vector__XXX
 SG_ DPB_a195_VCRIGHTepbmStatusChecks m3 : 18|1@1+ (1,0) [0|1] "" Vector__XXX
 SG_ DPB_a196_VCRIGHTepbmStatusDLC m3 : 19|1@1+ (1,0) [0|1] "" Vector__XXX
 SG_ DPB_a197_VCRIGHTepbmStatusTimeou m3 : 20|1@1+ (1,0) [0|1] "" Vector__XXX
 SG_ DPB_a198_CANOvervoltage m3 : 21|1@1+ (1,0) [0|1] "" Vector__XXX
 SG_ DPB_a199_pMC1QFaulty m3 : 22|1@1+ (1,0) [0|1] "" Vector__XXX
 SG_ DPB_a200_ESPRunoutSupportNotAvai m3 : 23|1@1+ (1,0) [0|1] "" Vector__XXX
 SG_ DPB_a201_vehicleSpeedQFaulty m3 : 24|1@1+ (1,0) [0|1] "" Vector__XXX
 SG_ DPB_a202_vehicleStandstillQFault m3 : 25|1@1+ (1,0) [0|1] "" Vector__XXX
 SG_ DPB_a203_ABSNotAvailable m3 : 26|1@1+ (1,0) [0|1] "" Vector__XXX
 SG_ DPB_a204_CANUndervoltage m3 : 27|1@1+ (1,0) [0|1] "" Vector__XXX
 SG_ DPB_a205_NvMWriteCycleExceed m3 : 28|1@1+ (1,0) [0|1] "" Vector__XXX
 SG_ DPB_a206_OSTaskSchemeError m3 : 29|1@1+ (1,0) [0|1] "" Vector__XXX
 SG_ DPB_a207_hydraulicOvervoltage m3 : 30|1@1+ (1,0) [0|1] "" Vector__XXX
 SG_ DPB_a208_pressureSensor1Short m3 : 31|1@1+ (1,0) [0|1] "" Vector__XXX
 SG_ DPB_a209_pressureSensor1High m3 : 32|1@1+ (1,0) [0|1] "" Vector__XXX
 SG_ DPB_a210_pressureSensor1Low m3 : 33|1@1+ (1,0) [0|1] "" Vector__XXX
 SG_ DPB_a211_pressureSensor1Fault m3 : 34|1@1+ (1,0) [0|1] "" Vector__XXX
 SG_ DPB_a212_pressureSensor1Temp m3 : 35|1@1+ (1,0) [0|1] "" Vector__XXX
 SG_ DPB_a213_pressureSensor1Fault m3 : 36|1@1+ (1,0) [0|1] "" Vector__XXX
 SG_ DPB_a214_pressureSensor2Short m3 : 37|1@1+ (1,0) [0|1] "" Vector__XXX
 SG_ DPB_a215_pressureSensor2High m3 : 38|1@1+ (1,0) [0|1] "" Vector__XXX
 SG_ DPB_a216_pressureSensor2Low m3 : 39|1@1+ (1,0) [0|1] "" Vector__XXX
 SG_ DPB_a217_pressureSensor2Fault m3 : 40|1@1+ (1,0) [0|1] "" Vector__XXX
 SG_ DPB_a218_pressureSensor2Temp m3 : 41|1@1+ (1,0) [0|1] "" Vector__XXX
 SG_ DPB_a219_pressureSensor2Fault m3 : 42|1@1+ (1,0) [0|1] "" Vector__XXX
 SG_ DPB_a220_excessiveBoostWakeupsDe m3 : 43|1@1+ (1,0) [0|1] "" Vector__XXX
 SG_ DPB_a221_notShutdownRight m3 : 44|1@1+ (1,0) [0|1] "" Vector__XXX
 SG_ DPB_a222_excessiveEcuResetsDetec m3 : 45|1@1+ (1,0) [0|1] "" Vector__XXX
 SG_ DPB_a223_RAMFault m3 : 46|1@1+ (1,0) [0|1] "" Vector__XXX
 SG_ DPB_a224_brakeBoostLost m3 : 47|1@1+ (1,0) [0|1] "" Vector__XXX
 SG_ DPB_a225_U5VOutOfRange m3 : 48|1@1+ (1,0) [0|1] "" Vector__XXX
 SG_ DPB_a226_U5VTestFault m3 : 49|1@1+ (1,0) [0|1] "" Vector__XXX
 SG_ DPB_a227_brakeFluidLoss m3 : 50|1@1+ (1,0) [0|1] "" Vector__XXX
 SG_ DPB_a228_supplyASICInitFault m3 : 51|1@1+ (1,0) [0|1] "" Vector__XXX
 SG_ DPB_a229_IREFOutOfRange m3 : 52|1@1+ (1,0) [0|1] "" Vector__XXX
 SG_ DPB_a230_OSErrorHook m3 : 53|1@1+ (1,0) [0|1] "" Vector__XXX
 SG_ DPB_a231_stackOverUnderFlow m3 : 54|1@1+ (1,0) [0|1] "" Vector__XXX
 SG_ DPB_a232_systemErrorHook m3 : 55|1@1+ (1,0) [0|1] "" Vector__XXX
 SG_ DPB_a233_systemTaskJitter m3 : 56|1@1+ (1,0) [0|1] "" Vector__XXX
 SG_ DPB_a234_systemTaskOverRun m3 : 57|1@1+ (1,0) [0|1] "" Vector__XXX
 SG_ DPB_a235_UB6PlausiMonFault m3 : 58|1@1+ (1,0) [0|1] "" Vector__XXX
 SG_ DPB_a236_UB6SupplyPathFault m3 : 59|1@1+ (1,0) [0|1] "" Vector__XXX
 SG_ DPB_a237_uCVoltageDividerDrift m3 : 60|1@1+ (1,0) [0|1] "" Vector__XXX
 SG_ DPB_a238_microRegisterFault m3 : 61|1@1+ (1,0) [0|1] "" Vector__XXX
 SG_ DPB_a239_microSafetyFault m3 : 62|1@1+ (1,0) [0|1] "" Vector__XXX
 SG_ DPB_a240_microSafetyLogicFault m3 : 63|1@1+ (1,0) [0|1] "" Vector__XXX
 SG_ DPB_a241_uCSafetyNotification m4 : 4|1@1+ (1,0) [0|1] "" Vector__XXX
 SG_ DPB_a242_uCSafetyNotificationGRA m4 : 5|1@1+ (1,0) [0|1] "" Vector__XXX
 SG_ DPB_a243_microSupplyError m4 : 6|1@1+ (1,0) [0|1] "" Vector__XXX
 SG_ DPB_a244_valvesGenericFault m4 : 7|1@1+ (1,0) [0|1] "" Vector__XXX
 SG_ DPB_a245_valveMV0Fault m4 : 8|1@1+ (1,0) [0|1] "" Vector__XXX
 SG_ DPB_a246_valveMV5Fault m4 : 9|1@1+ (1,0) [0|1] "" Vector__XXX
 SG_ DPB_a247_valveMV6Fault m4 : 10|1@1+ (1,0) [0|1] "" Vector__XXX
 SG_ DPB_a248_valveMV61Fault m4 : 11|1@1+ (1,0) [0|1] "" Vector__XXX
 SG_ DPB_a249_valveMV62Fault m4 : 12|1@1+ (1,0) [0|1] "" Vector__XXX
 SG_ DPB_a250_valveMV7Fault m4 : 13|1@1+ (1,0) [0|1] "" Vector__XXX
 SG_ DPB_a251_valveMV8Fault m4 : 14|1@1+ (1,0) [0|1] "" Vector__XXX
 SG_ DPB_a252_valveMV81Fault m4 : 15|1@1+ (1,0) [0|1] "" Vector__XXX
 SG_ DPB_a253_valveMV82Fault m4 : 16|1@1+ (1,0) [0|1] "" Vector__XXX
 SG_ DPB_a254_valveMV9Fault m4 : 17|1@1+ (1,0) [0|1] "" Vector__XXX
 SG_ DPB_a255_valveRelayShort m4 : 18|1@1+ (1,0) [0|1] "" Vector__XXX
 SG_ DPB_a256_valveRelayActuationFaul m4 : 19|1@1+ (1,0) [0|1] "" Vector__XXX
 SG_ DPB_a257_valveRelayOnContinuous m4 : 20|1@1+ (1,0) [0|1] "" Vector__XXX
 SG_ DPB_a258_valveRelayOffContinuous m4 : 21|1@1+ (1,0) [0|1] "" Vector__XXX
 SG_ DPB_a259_valveRelayTestUndervolt m4 : 22|1@1+ (1,0) [0|1] "" Vector__XXX
 SG_ DPB_a260_valveRelaySafetySwitchF m4 : 23|1@1+ (1,0) [0|1] "" Vector__XXX
 SG_ DPB_a261_WdhAsicWdCmdMissing m4 : 24|1@1+ (1,0) [0|1] "" Vector__XXX
 SG_ DPB_a262_WdhAsicWdErrorCntLimit m4 : 25|1@1+ (1,0) [0|1] "" Vector__XXX
 SG_ DPB_a263_WdhAsicWdErrorCntStuck m4 : 26|1@1+ (1,0) [0|1] "" Vector__XXX
 SG_ DPB_a264_WdhSwBistConCnt m4 : 27|1@1+ (1,0) [0|1] "" Vector__XXX
 SG_ DPB_a265_WdhTaskMonConCnt m4 : 28|1@1+ (1,0) [0|1] "" Vector__XXX
 SG_ DPB_a266_RPSNvMReadFault m4 : 29|1@1+ (1,0) [0|1] "" Vector__XXX
 SG_ DPB_a267_RpsAngleImplausible m4 : 30|1@1+ (1,0) [0|1] "" Vector__XXX
 SG_ DPB_a268_RPSVectorOscillating m4 : 31|1@1+ (1,0) [0|1] "" Vector__XXX
 SG_ DPB_a269_RPSVectorRangeHigh m4 : 32|1@1+ (1,0) [0|1] "" Vector__XXX
 SG_ DPB_a270_RPSVectorRangeLow m4 : 33|1@1+ (1,0) [0|1] "" Vector__XXX
 SG_ DPB_a271_RPSWrongCalibData m4 : 34|1@1+ (1,0) [0|1] "" Vector__XXX
 SG_ DPB_a272_runtimeAssertionFault m4 : 35|1@1+ (1,0) [0|1] "" Vector__XXX
 SG_ DPB_a273_SMMOneRequestsInit m4 : 36|1@1+ (1,0) [0|1] "" Vector__XXX
 SG_ DPB_a274_AswSystemTimeOut m4 : 37|1@1+ (1,0) [0|1] "" Vector__XXX
 SG_ DPB_a275_Ps1Ps2PlausibilityFault m4 : 38|1@1+ (1,0) [0|1] "" Vector__XXX
 SG_ DPB_a276_VCFRONTsensorsCounter m4 : 39|1@1+ (1,0) [0|1] "" Vector__XXX
 SG_ DPB_a277_VCFRONTsensorsChecksum m4 : 40|1@1+ (1,0) [0|1] "" Vector__XXX
 SG_ DPB_a278_VCFRONTsensorsDLC m4 : 41|1@1+ (1,0) [0|1] "" Vector__XXX
 SG_ DPB_a279_VCFRONTsensorsTimeout m4 : 42|1@1+ (1,0) [0|1] "" Vector__XXX
 SG_ DPB_a280_LowBrakeFluid m4 : 43|1@1+ (1,0) [0|1] "" Vector__XXX
 SG_ DPB_a281_brakeFluidOORHigh m4 : 44|1@1+ (1,0) [0|1] "" Vector__XXX
 SG_ DPB_a282_DIbrakeCommandCounter m4 : 45|1@1+ (1,0) [0|1] "" Vector__XXX
 SG_ DPB_a283_DIbrakeCommandChecksum m4 : 46|1@1+ (1,0) [0|1] "" Vector__XXX
 SG_ DPB_a284_DIbrakeCommandDLC m4 : 47|1@1+ (1,0) [0|1] "" Vector__XXX
 SG_ DPB_a285_DIbrakeCommandTimeout m4 : 48|1@1+ (1,0) [0|1] "" Vector__XXX
 SG_ DPB_a286_ebrCmdStateInvalid m4 : 49|1@1+ (1,0) [0|1] "" Vector__XXX
 SG_ DPB_a287_brakeCmdStateInvalid m4 : 50|1@1+ (1,0) [0|1] "" Vector__XXX
 SG_ DPB_a288_PlantDegradedSW m4 : 51|1@1+ (1,0) [0|1] "" Vector__XXX
 SG_ DPB_a289_evacFillNotComplete m4 : 52|1@1+ (1,0) [0|1] "" Vector__XXX
 SG_ DPB_a290_securityInfo m4 : 53|1@1+ (1,0) [0|1] "" Vector__XXX
 SG_ DPB_a291_extDBRRequestTooLow m4 : 54|1@1+ (1,0) [0|1] "" Vector__XXX
 SG_ DPB_a292_CBDS_fillBufferThreshol m4 : 55|1@1+ (1,0) [0|1] "" Vector__XXX
 SG_ DPB_a293_CBDS_fmeInternalEvent m4 : 56|1@1+ (1,0) [0|1] "" Vector__XXX
 SG_ DPB_a294_hbaNormalModeActive m4 : 57|1@1+ (1,0) [0|1] "" Vector__XXX
 SG_ DPB_a295_hbaTrackModeActive m4 : 58|1@1+ (1,0) [0|1] "" Vector__XXX
 SG_ DPB_a296_StatInvalid_DI_FullSNA m4 : 59|1@1+ (1,0) [0|1] "" Vector__XXX
 SG_ DPB_a297_undefinedAlertDetected m4 : 60|1@1+ (1,0) [0|1] "" Vector__XXX
 SG_ DPB_a298_runningPlungerCircuitTe m4 : 61|1@1+ (1,0) [0|1] "" Vector__XXX
 SG_ DPB_a299_PM_locStateCounter m4 : 62|1@1+ (1,0) [0|1] "" Vector__XXX
 SG_ DPB_a300_PM_locStateChecksum m4 : 63|1@1+ (1,0) [0|1] "" Vector__XXX
 SG_ DPB_a301_PM_locStateDLC m5 : 4|1@1+ (1,0) [0|1] "" Vector__XXX
 SG_ DPB_a302_PM_locStateTimeout m5 : 5|1@1+ (1,0) [0|1] "" Vector__XXX
 SG_ DPB_a303_actuatingDIFullTorqueCm m5 : 6|1@1+ (1,0) [0|1] "" Vector__XXX
 SG_ DPB_a304_actuatingDITorqueCmd m5 : 7|1@1+ (1,0) [0|1] "" Vector__XXX
 SG_ DPB_a305_DIbrakeTorqueCommandAnd m5 : 8|1@1+ (1,0) [0|1] "" Vector__XXX
 SG_ DPB_a306_actuatorFallbackBasicMa m5 : 9|1@1+ (1,0) [0|1] "" Vector__XXX
 SG_ DPB_a307_actuatorDegradedMap m5 : 10|1@1+ (1,0) [0|1] "" Vector__XXX
 SG_ DPB_a308_backupMode m5 : 11|1@1+ (1,0) [0|1] "" Vector__XXX
 SG_ DPB_a309_DIFAxleTorqueInvalid m5 : 12|1@1+ (1,0) [0|1] "" Vector__XXX
 SG_ DPB_a310_DIRAxleTorqueInvalid m5 : 13|1@1+ (1,0) [0|1] "" Vector__XXX
 SG_ DPB_a311_postrunDurationTooLong m5 : 14|1@1+ (1,0) [0|1] "" Vector__XXX
 SG_ DPB_a312_continuouslyActivatedVa m5 : 15|1@1+ (1,0) [0|1] "" Vector__XXX
 SG_ DPB_a313_qualifiedBrakeEventDete m5 : 16|1@1+ (1,0) [0|1] "" Vector__XXX
 SG_ DPB_a314_runningCyclicVolumeChec m5 : 17|1@1+ (1,0) [0|1] "" Vector__XXX
 SG_ DPB_a315_runningLeakageAndAirMon m5 : 18|1@1+ (1,0) [0|1] "" Vector__XXX
 SG_ DPB_a316_lowBrakeFluidDetectedOn m5 : 19|1@1+ (1,0) [0|1] "" Vector__XXX
 SG_ DPB_a317_DASredundantBrakingCont m5 : 20|1@1+ (1,0) [0|1] "" Vector__XXX
 SG_ DPB_a318_DASredundantBrakingCont m5 : 21|1@1+ (1,0) [0|1] "" Vector__XXX
 SG_ DPB_a319_DASredundantBrakingCont m5 : 22|1@1+ (1,0) [0|1] "" Vector__XXX
 SG_ DPB_a320_DASredundantBrakingCont m5 : 23|1@1+ (1,0) [0|1] "" Vector__XXX
 SG_ DPB_a321_DASredundantBrakingCont m5 : 24|1@1+ (1,0) [0|1] "" Vector__XXX
 SG_ DPB_a322_DASredundantBrakingCont m5 : 25|1@1+ (1,0) [0|1] "" Vector__XXX
 SG_ DPB_a323_DASredundantBrakingCont m5 : 26|1@1+ (1,0) [0|1] "" Vector__XXX
 SG_ DPB_a324_DASredundantBrakingCont m5 : 27|1@1+ (1,0) [0|1] "" Vector__XXX
 SG_ DPB_a325_DIlocStatus2Checksum m5 : 28|1@1+ (1,0) [0|1] "" Vector__XXX
 SG_ DPB_a326_DIlocStatus2Counter m5 : 29|1@1+ (1,0) [0|1] "" Vector__XXX
 SG_ DPB_a327_DIlocStatus2DLC m5 : 30|1@1+ (1,0) [0|1] "" Vector__XXX
 SG_ DPB_a328_DIlocStatus2Timeout m5 : 31|1@1+ (1,0) [0|1] "" Vector__XXX
 SG_ DPB_a329_standaloneEBRActive m5 : 32|1@1+ (1,0) [0|1] "" Vector__XXX
 SG_ DPB_a330_EMCMain11Checksum m5 : 33|1@1+ (1,0) [0|1] "" Vector__XXX
 SG_ DPB_a331_EMCMain11Counter m5 : 34|1@1+ (1,0) [0|1] "" Vector__XXX
 SG_ DPB_a332_EMCMain11DLC m5 : 35|1@1+ (1,0) [0|1] "" Vector__XXX
 SG_ DPB_a333_EMCMain11Timeout m5 : 36|1@1+ (1,0) [0|1] "" Vector__XXX
 SG_ DPB_a334_EMCMain21Checksum m5 : 37|1@1+ (1,0) [0|1] "" Vector__XXX
 SG_ DPB_a335_EMCMain21Counter m5 : 38|1@1+ (1,0) [0|1] "" Vector__XXX
 SG_ DPB_a336_EMCMain21DLC m5 : 39|1@1+ (1,0) [0|1] "" Vector__XXX
 SG_ DPB_a337_EMCMain21Timeout m5 : 40|1@1+ (1,0) [0|1] "" Vector__XXX

BO_ 1426 EPAS3P_alertLog: 8 EPAS3P
 SG_ EPAS3P_alertID M : 0|8@1+ (1,0) [0|255] "" Vector__XXX
 SG_ EPAS3P_alertState : 15|1@1+ (1,0) [0|1] "" Vector__XXX
 SG_ EPAS3P_a147_transitionReason m147 : 16|2@1+ (1,0) [0|3] "" Vector__XXX
 SG_ EPAS3P_a149_pcbTemp m149 : 16|8@1- (1,60) [-68|187] "degC" Vector__XXX
 SG_ EPAS3P_a150_pcbTemp m150 : 16|8@1- (1,60) [-68|187] "degC" Vector__XXX
 SG_ EPAS3P_a150_phaUMainPathCalcDiff m150 : 24|15@1+ (1,0) [0|32767] "Counts" Vector__XXX
 SG_ EPAS3P_a150_phaVMainPathCalcDiff m150 : 39|15@1+ (1,0) [0|32767] "Counts" Vector__XXX
 SG_ EPAS3P_a150_otherECUAssistStatus m150 : 54|1@1+ (1,0) [0|1] "" Vector__XXX
 SG_ EPAS3P_a155_vehicleSpeed m155 : 16|10@1+ (0.5,0) [0|511.5] "kph" Vector__XXX
 SG_ EPAS3P_a156_vehicleSpeed m156 : 16|10@1+ (0.5,0) [0|511.5] "kph" Vector__XXX
 SG_ EPAS3P_a160_currentSensorStatus m160 : 16|2@1+ (1,0) [0|3] "" Vector__XXX
 SG_ EPAS3P_a160_gateDriverStatus m160 : 18|2@1+ (1,0) [0|3] "" Vector__XXX
 SG_ EPAS3P_a160_highSideDisconnectFe m160 : 20|2@1+ (1,0) [0|3] "" Vector__XXX
 SG_ EPAS3P_a160_phaseDisconnectFetSt m160 : 22|2@1+ (1,0) [0|3] "" Vector__XXX
 SG_ EPAS3P_a160_inverterFetStatus m160 : 24|2@1+ (1,0) [0|3] "" Vector__XXX
 SG_ EPAS3P_a160_hsdFetFailShortTest m160 : 26|2@1+ (1,0) [0|3] "" Vector__XXX
 SG_ EPAS3P_a160_phaDisconnFailOpenTe m160 : 28|2@1+ (1,0) [0|3] "" Vector__XXX
 SG_ EPAS3P_a160_phaDisconnFailShortT m160 : 30|2@1+ (1,0) [0|3] "" Vector__XXX
 SG_ EPAS3P_a160_invFetInitTest m160 : 32|2@1+ (1,0) [0|3] "" Vector__XXX
 SG_ EPAS3P_a160_gateDrvrInitTest m160 : 34|2@1+ (1,0) [0|3] "" Vector__XXX
 SG_ EPAS3P_a160_latentFaultTestTimeo m160 : 36|1@1+ (1,0) [0|1] "" Vector__XXX
 SG_ EPAS3P_a161_pcoMinPhaseBCurrent m161 : 16|12@1- (0.1025,0) [-209.92|209.8175] "Amps" Vector__XXX
 SG_ EPAS3P_a161_pcoMaxPhaseBCurrent m161 : 28|12@1- (0.1025,0) [-209.92|209.8175] "Amps" Vector__XXX
 SG_ EPAS3P_a161_pcoMinPhaseACurrent m161 : 40|12@1- (0.1025,0) [-209.92|209.8175] "Amps" Vector__XXX
 SG_ EPAS3P_a161_pcoMaxPhaseACurrent m161 : 52|12@1- (0.1025,0) [-209.92|209.8175] "Amps" Vector__XXX
 SG_ EPAS3P_a162_vBridgeClosed m162 : 16|16@1+ (0.00537,0) [0|351.92295] "Volts" Vector__XXX
 SG_ EPAS3P_a162_vBridgeOpen m162 : 32|16@1+ (0.00537,0) [0|351.92295] "Volts" Vector__XXX
 SG_ EPAS3P_a163_gateDrvrStatusReg m163 : 16|11@1+ (1,0) [0|2047] "Counts" Vector__XXX
 SG_ EPAS3P_a163_gateDrvrDiag2Reg m163 : 27|9@1+ (1,0) [0|511] "Counts" Vector__XXX
 SG_ EPAS3P_a163_gateDrvrDiag1Reg m163 : 36|9@1+ (1,0) [0|511] "Counts" Vector__XXX
 SG_ EPAS3P_a163_gateDrvrDiag0Reg m163 : 45|9@1+ (1,0) [0|511] "Counts" Vector__XXX
 SG_ EPAS3P_a163_diagStatus m163 : 54|1@1+ (1,0) [0|1] "" Vector__XXX
 SG_ EPAS3P_a163_powerStatus m163 : 55|1@1+ (1,0) [0|1] "" Vector__XXX
 SG_ EPAS3P_a164_dcsRegister0x19 m164 : 16|16@1+ (1,0) [0|65535] "Counts" Vector__XXX
 SG_ EPAS3P_a164_currentSensorRailed m164 : 32|1@1+ (1,0) [0|1] "" Vector__XXX

BO_ 2035 EPAS3P_alertMatrix: 8 EPAS3P
 SG_ EPAS3P_matrixIndex M : 0|4@1+ (1,0) [0|15] "" Vector__XXX
 SG_ EPAS3P_a001_sent1Mia m0 : 4|1@1+ (1,0) [0|1] "" Vector__XXX
 SG_ EPAS3P_a002_sent1Error m0 : 5|1@1+ (1,0) [0|1] "" Vector__XXX
 SG_ EPAS3P_a003_trqSens1Supply m0 : 6|1@1+ (1,0) [0|1] "" Vector__XXX
 SG_ EPAS3P_a004_trqSens1Eeprom m0 : 7|1@1+ (1,0) [0|1] "" Vector__XXX
 SG_ EPAS3P_a005_sent2Mia m0 : 8|1@1+ (1,0) [0|1] "" Vector__XXX
 SG_ EPAS3P_a006_sent2Error m0 : 9|1@1+ (1,0) [0|1] "" Vector__XXX
 SG_ EPAS3P_a007_trqSens2Supply m0 : 10|1@1+ (1,0) [0|1] "" Vector__XXX
 SG_ EPAS3P_a008_trqSens2Eeprom m0 : 11|1@1+ (1,0) [0|1] "" Vector__XXX
 SG_ EPAS3P_a009_sentDiff m0 : 12|1@1+ (1,0) [0|1] "" Vector__XXX
 SG_ EPAS3P_a010_trqSensCalError m0 : 13|1@1+ (1,0) [0|1] "" Vector__XXX
 SG_ EPAS3P_a011_currentSensError m0 : 14|1@1+ (1,0) [0|1] "" Vector__XXX
 SG_ EPAS3P_a012_currentSensCalError m0 : 15|1@1+ (1,0) [0|1] "" Vector__XXX
 SG_ EPAS3P_a013_gateDriveError m0 : 16|1@1+ (1,0) [0|1] "" Vector__XXX
 SG_ EPAS3P_a014_gateDriveTxError m0 : 17|1@1+ (1,0) [0|1] "" Vector__XXX
 SG_ EPAS3P_a015_gateDriveEeprom m0 : 18|1@1+ (1,0) [0|1] "" Vector__XXX
 SG_ EPAS3P_a016_phaseUhighUv m0 : 19|1@1+ (1,0) [0|1] "" Vector__XXX
 SG_ EPAS3P_a017_phaseUlowUv m0 : 20|1@1+ (1,0) [0|1] "" Vector__XXX
 SG_ EPAS3P_a018_phaseVhighUv m0 : 21|1@1+ (1,0) [0|1] "" Vector__XXX
 SG_ EPAS3P_a019_phaseVlowUv m0 : 22|1@1+ (1,0) [0|1] "" Vector__XXX
 SG_ EPAS3P_a020_phaseWhighUv m0 : 23|1@1+ (1,0) [0|1] "" Vector__XXX
 SG_ EPAS3P_a021_phaseWlowUv m0 : 24|1@1+ (1,0) [0|1] "" Vector__XXX
 SG_ EPAS3P_a022_phaseUhighOv m0 : 25|1@1+ (1,0) [0|1] "" Vector__XXX
 SG_ EPAS3P_a023_phaseUlowOv m0 : 26|1@1+ (1,0) [0|1] "" Vector__XXX
 SG_ EPAS3P_a024_phaseVhighOv m0 : 27|1@1+ (1,0) [0|1] "" Vector__XXX
 SG_ EPAS3P_a025_phaseVlowOv m0 : 28|1@1+ (1,0) [0|1] "" Vector__XXX
 SG_ EPAS3P_a026_phaseWhighOv m0 : 29|1@1+ (1,0) [0|1] "" Vector__XXX
 SG_ EPAS3P_a027_phaseWlowOv m0 : 30|1@1+ (1,0) [0|1] "" Vector__XXX
 SG_ EPAS3P_a028_phaseUbootUv m0 : 31|1@1+ (1,0) [0|1] "" Vector__XXX
 SG_ EPAS3P_a029_phaseVbootUv m0 : 32|1@1+ (1,0) [0|1] "" Vector__XXX
 SG_ EPAS3P_a030_phaseWbootUv m0 : 33|1@1+ (1,0) [0|1] "" Vector__XXX
 SG_ EPAS3P_a031_abnormalShutdown m0 : 34|1@1+ (1,0) [0|1] "" Vector__XXX
 SG_ EPAS3P_a032_vRegOutputUv m0 : 35|1@1+ (1,0) [0|1] "" Vector__XXX
 SG_ EPAS3P_a033_vRegOutputOv m0 : 36|1@1+ (1,0) [0|1] "" Vector__XXX
 SG_ EPAS3P_a034_vRegError m0 : 37|1@1+ (1,0) [0|1] "" Vector__XXX
 SG_ EPAS3P_a035_vbbSupplyUv m0 : 38|1@1+ (1,0) [0|1] "" Vector__XXX
 SG_ EPAS3P_a036_vbbSupplyOv m0 : 39|1@1+ (1,0) [0|1] "" Vector__XXX
 SG_ EPAS3P_a037_motPos1ParityError m0 : 40|1@1+ (1,0) [0|1] "" Vector__XXX
 SG_ EPAS3P_a038_motPos1Uv m0 : 41|1@1+ (1,0) [0|1] "" Vector__XXX
 SG_ EPAS3P_a039_motPos1MagnetMia m0 : 42|1@1+ (1,0) [0|1] "" Vector__XXX
 SG_ EPAS3P_a040_motPos1LogicError m0 : 43|1@1+ (1,0) [0|1] "" Vector__XXX
 SG_ EPAS3P_a041_motPos1tempError m0 : 44|1@1+ (1,0) [0|1] "" Vector__XXX
 SG_ EPAS3P_a042_motPos2ParityError m0 : 45|1@1+ (1,0) [0|1] "" Vector__XXX
 SG_ EPAS3P_a043_motPos2Uv m0 : 46|1@1+ (1,0) [0|1] "" Vector__XXX
 SG_ EPAS3P_a044_motPos2MagnetMia m0 : 47|1@1+ (1,0) [0|1] "" Vector__XXX
 SG_ EPAS3P_a045_motPos2LogicError m0 : 48|1@1+ (1,0) [0|1] "" Vector__XXX
 SG_ EPAS3P_a046_motPos2tempError m0 : 49|1@1+ (1,0) [0|1] "" Vector__XXX
 SG_ EPAS3P_a047_motPosCorrError m0 : 50|1@1+ (1,0) [0|1] "" Vector__XXX
 SG_ EPAS3P_a048_motPosCalError m0 : 51|1@1+ (1,0) [0|1] "" Vector__XXX
 SG_ EPAS3P_a049_piCtrlError m0 : 52|1@1+ (1,0) [0|1] "" Vector__XXX
 SG_ EPAS3P_a050_mcuSmuError m0 : 53|1@1+ (1,0) [0|1] "" Vector__XXX
 SG_ EPAS3P_a051_mcuSupError m0 : 54|1@1+ (1,0) [0|1] "" Vector__XXX
 SG_ EPAS3P_a052_intWatchdogError m0 : 55|1@1+ (1,0) [0|1] "" Vector__XXX
 SG_ EPAS3P_a053_extWatchdogError m0 : 56|1@1+ (1,0) [0|1] "" Vector__XXX
 SG_ EPAS3P_a054_memoryProtectError m0 : 57|1@1+ (1,0) [0|1] "" Vector__XXX
 SG_ EPAS3P_a055_floatPointError m0 : 58|1@1+ (1,0) [0|1] "" Vector__XXX
 SG_ EPAS3P_a056_battUv m0 : 59|1@1+ (1,0) [0|1] "" Vector__XXX
 SG_ EPAS3P_a057_battUvReduced m0 : 60|1@1+ (1,0) [0|1] "" Vector__XXX
 SG_ EPAS3P_a058_battOv m0 : 61|1@1+ (1,0) [0|1] "" Vector__XXX
 SG_ EPAS3P_a059_battOvReduced m0 : 62|1@1+ (1,0) [0|1] "" Vector__XXX
 SG_ EPAS3P_a060_battBridgeDiff m0 : 63|1@1+ (1,0) [0|1] "" Vector__XXX
 SG_ EPAS3P_a061_bridgeUv m1 : 4|1@1+ (1,0) [0|1] "" Vector__XXX
 SG_ EPAS3P_a062_assistCorrError m1 : 5|1@1+ (1,0) [0|1] "" Vector__XXX
 SG_ EPAS3P_a063_dampCorrError m1 : 6|1@1+ (1,0) [0|1] "" Vector__XXX
 SG_ EPAS3P_a064_phaseCompCorrError m1 : 7|1@1+ (1,0) [0|1] "" Vector__XXX
 SG_ EPAS3P_a065_trqTarCorrError m1 : 8|1@1+ (1,0) [0|1] "" Vector__XXX
 SG_ EPAS3P_a066_returnCorrError m1 : 9|1@1+ (1,0) [0|1] "" Vector__XXX
 SG_ EPAS3P_a067_yawDampCorrError m1 : 10|1@1+ (1,0) [0|1] "" Vector__XXX
 SG_ EPAS3P_a068_hystCorrError m1 : 11|1@1+ (1,0) [0|1] "" Vector__XXX
 SG_ EPAS3P_a069_eacCorrError m1 : 12|1@1+ (1,0) [0|1] "" Vector__XXX
 SG_ EPAS3P_a070_hodCorrError m1 : 13|1@1+ (1,0) [0|1] "" Vector__XXX
 SG_ EPAS3P_a071_vehSpdCorrError m1 : 14|1@1+ (1,0) [0|1] "" Vector__XXX
 SG_ EPAS3P_a072_motFeedFwdError m1 : 15|1@1+ (1,0) [0|1] "" Vector__XXX
 SG_ EPAS3P_a073_motParEstError m1 : 16|1@1+ (1,0) [0|1] "" Vector__XXX
 SG_ EPAS3P_a074_overHeatProtect m1 : 17|1@1+ (1,0) [0|1] "" Vector__XXX
 SG_ EPAS3P_a075_fspPwrCut m1 : 18|1@1+ (1,0) [0|1] "" Vector__XXX
 SG_ EPAS3P_a076_tempSensOutofRange m1 : 19|1@1+ (1,0) [0|1] "" Vector__XXX
 SG_ EPAS3P_a077_highSideFetError m1 : 20|1@1+ (1,0) [0|1] "" Vector__XXX
 SG_ EPAS3P_a078_phaseDisconnectError m1 : 21|1@1+ (1,0) [0|1] "" Vector__XXX
 SG_ EPAS3P_a079_backupCurrentPlaus m1 : 22|1@1+ (1,0) [0|1] "" Vector__XXX
 SG_ EPAS3P_a080_ecuInitArbError m1 : 23|1@1+ (1,0) [0|1] "" Vector__XXX
 SG_ EPAS3P_a081_coggCompError m1 : 24|1@1+ (1,0) [0|1] "" Vector__XXX
 SG_ EPAS3P_a082_polarityCalError m1 : 25|1@1+ (1,0) [0|1] "" Vector__XXX
 SG_ EPAS3P_a083_crcMismatch m1 : 26|1@1+ (1,0) [0|1] "" Vector__XXX
 SG_ EPAS3P_a084_eacCancelled m1 : 27|1@1+ (1,0) [0|1] "" Vector__XXX
 SG_ EPAS3P_a085_canBusOff m1 : 28|1@1+ (1,0) [0|1] "" Vector__XXX
 SG_ EPAS3P_a086_dasMia m1 : 29|1@1+ (1,0) [0|1] "" Vector__XXX
 SG_ EPAS3P_a087_dasCntError m1 : 30|1@1+ (1,0) [0|1] "" Vector__XXX
 SG_ EPAS3P_a088_dasCsError m1 : 31|1@1+ (1,0) [0|1] "" Vector__XXX
 SG_ EPAS3P_a089_espWsMia m1 : 32|1@1+ (1,0) [0|1] "" Vector__XXX
 SG_ EPAS3P_a090_espWsCntError m1 : 33|1@1+ (1,0) [0|1] "" Vector__XXX
 SG_ EPAS3P_a091_espWsCsError m1 : 34|1@1+ (1,0) [0|1] "" Vector__XXX
 SG_ EPAS3P_a092_espWrMia m1 : 35|1@1+ (1,0) [0|1] "" Vector__XXX
 SG_ EPAS3P_a093_espWrCntError m1 : 36|1@1+ (1,0) [0|1] "" Vector__XXX
 SG_ EPAS3P_a094_espWrCsError m1 : 37|1@1+ (1,0) [0|1] "" Vector__XXX
 SG_ EPAS3P_a095_espWsStatus m1 : 38|1@1+ (1,0) [0|1] "" Vector__XXX
 SG_ EPAS3P_a096_rcmMia m1 : 39|1@1+ (1,0) [0|1] "" Vector__XXX
 SG_ EPAS3P_a097_rcmCntError m1 : 40|1@1+ (1,0) [0|1] "" Vector__XXX
 SG_ EPAS3P_a098_rcmCsError m1 : 41|1@1+ (1,0) [0|1] "" Vector__XXX
 SG_ EPAS3P_a099_yawRateStatus m1 : 42|1@1+ (1,0) [0|1] "" Vector__XXX
 SG_ EPAS3P_a100_diMia m1 : 43|1@1+ (1,0) [0|1] "" Vector__XXX
 SG_ EPAS3P_a101_diCntError m1 : 44|1@1+ (1,0) [0|1] "" Vector__XXX
 SG_ EPAS3P_a102_diCsError m1 : 45|1@1+ (1,0) [0|1] "" Vector__XXX
 SG_ EPAS3P_a103_vcFrontMia m1 : 46|1@1+ (1,0) [0|1] "" Vector__XXX
 SG_ EPAS3P_a104_vcFrontCntError m1 : 47|1@1+ (1,0) [0|1] "" Vector__XXX
 SG_ EPAS3P_a105_vcFrontCsError m1 : 48|1@1+ (1,0) [0|1] "" Vector__XXX
 SG_ EPAS3P_a106_vcFrontTempMia m1 : 49|1@1+ (1,0) [0|1] "" Vector__XXX
 SG_ EPAS3P_a107_uiTuneReqMia m1 : 50|1@1+ (1,0) [0|1] "" Vector__XXX
 SG_ EPAS3P_a108_uiTuneReqCntError m1 : 51|1@1+ (1,0) [0|1] "" Vector__XXX
 SG_ EPAS3P_a109_uiTuneReqCsError m1 : 52|1@1+ (1,0) [0|1] "" Vector__XXX
 SG_ EPAS3P_a110_sasMia m1 : 53|1@1+ (1,0) [0|1] "" Vector__XXX
 SG_ EPAS3P_a111_sasCntError m1 : 54|1@1+ (1,0) [0|1] "" Vector__XXX
 SG_ EPAS3P_a112_sasCsError m1 : 55|1@1+ (1,0) [0|1] "" Vector__XXX
 SG_ EPAS3P_a113_sasStatusError m1 : 56|1@1+ (1,0) [0|1] "" Vector__XXX
 SG_ EPAS3P_a114_gtwConfigMia m1 : 57|1@1+ (1,0) [0|1] "" Vector__XXX
 SG_ EPAS3P_a115_ecuStatMia m1 : 58|1@1+ (1,0) [0|1] "" Vector__XXX
 SG_ EPAS3P_a116_ecuStatCntError m1 : 59|1@1+ (1,0) [0|1] "" Vector__XXX
 SG_ EPAS3P_a117_ecuStatCrcError m1 : 60|1@1+ (1,0) [0|1] "" Vector__XXX
 SG_ EPAS3P_a118_privateBusOff m1 : 61|1@1+ (1,0) [0|1] "" Vector__XXX
 SG_ EPAS3P_a119_pvtEcuStatMia m1 : 62|1@1+ (1,0) [0|1] "" Vector__XXX
 SG_ EPAS3P_a120_pvtEcuStatCntError m1 : 63|1@1+ (1,0) [0|1] "" Vector__XXX
 SG_ EPAS3P_a121_pvtEcuStatCrcError m2 : 4|1@1+ (1,0) [0|1] "" Vector__XXX
 SG_ EPAS3P_a122_olpActive m2 : 5|1@1+ (1,0) [0|1] "" Vector__XXX
 SG_ EPAS3P_a123_combEcu2StatFail m2 : 6|1@1+ (1,0) [0|1] "" Vector__XXX
 SG_ EPAS3P_a124_tempSensStuckInRange m2 : 7|1@1+ (1,0) [0|1] "" Vector__XXX
 SG_ EPAS3P_a125_trqSensTrimOutRange m2 : 8|1@1+ (1,0) [0|1] "" Vector__XXX
 SG_ EPAS3P_a126_apsMia m2 : 9|1@1+ (1,0) [0|1] "" Vector__XXX
 SG_ EPAS3P_a127_apsCntError m2 : 10|1@1+ (1,0) [0|1] "" Vector__XXX
 SG_ EPAS3P_a128_apsCsError m2 : 11|1@1+ (1,0) [0|1] "" Vector__XXX
 SG_ EPAS3P_a129_combEcu1StatFail m2 : 12|1@1+ (1,0) [0|1] "" Vector__XXX
 SG_ EPAS3P_a130_sasOffsetNotCal m2 : 13|1@1+ (1,0) [0|1] "" Vector__XXX
 SG_ EPAS3P_a131_phaseFeedbackError m2 : 14|1@1+ (1,0) [0|1] "" Vector__XXX
 SG_ EPAS3P_a132_motFeedFwdCounter25 m2 : 15|1@1+ (1,0) [0|1] "" Vector__XXX
 SG_ EPAS3P_a133_motFeedFwdCounter50 m2 : 16|1@1+ (1,0) [0|1] "" Vector__XXX
 SG_ EPAS3P_a134_motFeedFwdCounter85 m2 : 17|1@1+ (1,0) [0|1] "" Vector__XXX
 SG_ EPAS3P_a135_piCtrlCounter25 m2 : 18|1@1+ (1,0) [0|1] "" Vector__XXX
 SG_ EPAS3P_a136_piCtrlCounter50 m2 : 19|1@1+ (1,0) [0|1] "" Vector__XXX
 SG_ EPAS3P_a137_piCtrlCounter85 m2 : 20|1@1+ (1,0) [0|1] "" Vector__XXX
 SG_ EPAS3P_a144_diSpdMia m2 : 21|1@1+ (1,0) [0|1] "" Vector__XXX
 SG_ EPAS3P_a145_diSpdCntError m2 : 22|1@1+ (1,0) [0|1] "" Vector__XXX
 SG_ EPAS3P_a146_diSpdCsError m2 : 23|1@1+ (1,0) [0|1] "" Vector__XXX
 SG_ EPAS3P_a147_backupVehSpeed m2 : 24|1@1+ (1,0) [0|1] "" Vector__XXX
 SG_ EPAS3P_a148_vMaxAssist m2 : 25|1@1+ (1,0) [0|1] "" Vector__XXX
 SG_ EPAS3P_a149_currentSensPathSwitc m2 : 26|1@1+ (1,0) [0|1] "" Vector__XXX
 SG_ EPAS3P_a150_currentSensOffsetDet m2 : 27|1@1+ (1,0) [0|1] "" Vector__XXX
 SG_ EPAS3P_a151_dcsCboot m2 : 28|1@1+ (1,0) [0|1] "" Vector__XXX
 SG_ EPAS3P_a152_dcsDiagReg m2 : 29|1@1+ (1,0) [0|1] "" Vector__XXX
 SG_ EPAS3P_a153_dcsInitOffset m2 : 30|1@1+ (1,0) [0|1] "" Vector__XXX
 SG_ EPAS3P_a154_assistTorqueDisabled m2 : 31|1@1+ (1,0) [0|1] "" Vector__XXX
 SG_ EPAS3P_a155_backupEacActive m2 : 32|1@1+ (1,0) [0|1] "" Vector__XXX
 SG_ EPAS3P_a156_angleSensorDivergenc m2 : 33|1@1+ (1,0) [0|1] "" Vector__XXX
 SG_ EPAS3P_a157_pmState2Mia m2 : 34|1@1+ (1,0) [0|1] "" Vector__XXX
 SG_ EPAS3P_a158_pmState2CntError m2 : 35|1@1+ (1,0) [0|1] "" Vector__XXX
 SG_ EPAS3P_a159_pmState2CsError m2 : 36|1@1+ (1,0) [0|1] "" Vector__XXX
 SG_ EPAS3P_a160_latentFaultTestResul m2 : 37|1@1+ (1,0) [0|1] "" Vector__XXX
 SG_ EPAS3P_a161_initTestPhaDisconnIn m2 : 38|1@1+ (1,0) [0|1] "" Vector__XXX
 SG_ EPAS3P_a162_initTestHSDFetInfo m2 : 39|1@1+ (1,0) [0|1] "" Vector__XXX
 SG_ EPAS3P_a163_initTestGateDrvrInfo m2 : 40|1@1+ (1,0) [0|1] "" Vector__XXX
 SG_ EPAS3P_a164_initTestDCSInfo m2 : 41|1@1+ (1,0) [0|1] "" Vector__XXX
 SG_ EPAS3P_a165_epbStatusMia m2 : 42|1@1+ (1,0) [0|1] "" Vector__XXX
 SG_ EPAS3P_a166_epbStatusCntError m2 : 43|1@1+ (1,0) [0|1] "" Vector__XXX
 SG_ EPAS3P_a167_epbStatusCsError m2 : 44|1@1+ (1,0) [0|1] "" Vector__XXX
 SG_ EPAS3P_a168_torsionBarTorqueQfDe m2 : 45|1@1+ (1,0) [0|1] "" Vector__XXX
 SG_ EPAS3P_a169_difMia m2 : 46|1@1+ (1,0) [0|1] "" Vector__XXX
 SG_ EPAS3P_a170_difCntError m2 : 47|1@1+ (1,0) [0|1] "" Vector__XXX
 SG_ EPAS3P_a171_difCsError m2 : 48|1@1+ (1,0) [0|1] "" Vector__XXX

BO_ 977 EPAS3P_angleCalibration: 8 EPAS3P
 SG_ EPAS3P_appliedAngleOffset : 0|8@1+ (0.1,-12.8) [-12.8|12.7] "deg" Vector__XXX
 SG_ EPAS3P_calculatedAngleOffset : 8|8@1+ (0.1,-12.8) [-12.8|12.7] "deg" Vector__XXX
 SG_ EPAS3P_resyncStatus : 16|1@1+ (1,0) [0|1] "" Vector__XXX
 SG_ EPAS3P_pullDriftLongTermTrq : 17|12@1+ (0.01,-10) [-10|10] "Nm" Vector__XXX
 SG_ EPAS3P_pullDriftCompTrq : 29|12@1+ (0.01,-10) [-10|10] "Nm" Vector__XXX
 SG_ EPAS3P_learnedSCCMOffset : 41|8@1+ (0.1,-12.8) [-12.8|12.7] "deg" Vector__XXX

BO_ 817 EPAS3P_info: 8 EPAS3P
 SG_ EPAS3P_infoIndex M : 0|8@1+ (1,0) [0|255] "" Vector__XXX
 SG_ EPAS3P_infoBuildType m10 : 8|8@1+ (1,0) [0|255] "" Vector__XXX
 SG_ EPAS3P_infoComponentID m10 : 48|16@1+ (1,0) [0|65535] "" Vector__XXX
 SG_ EPAS3P_infoPcbaID m11 : 16|8@1+ (1,0) [0|255] "" Vector__XXX
 SG_ EPAS3P_infoAssemblyID m11 : 24|8@1+ (1,0) [0|255] "" Vector__XXX
 SG_ EPAS3P_infoUsageID m11 : 32|16@1+ (1,0) [0|65535] "" Vector__XXX
 SG_ EPAS3P_infoApplicationCRC m13 : 32|32@1+ (1,0) [0|4294967295] "" Vector__XXX
 SG_ EPAS3P_infoBootUdsProtoVersion m20 : 8|8@1+ (1,0) [0|255] "" Vector__XXX
 SG_ EPAS3P_infoBootloaderCRC m20 : 32|32@1+ (1,0) [0|4294967295] "" Vector__XXX
 SG_ EPAS3P_infoSubcomponent2 m23 : 32|32@1+ (1,0) [0|4294967295] "" Vector__XXX

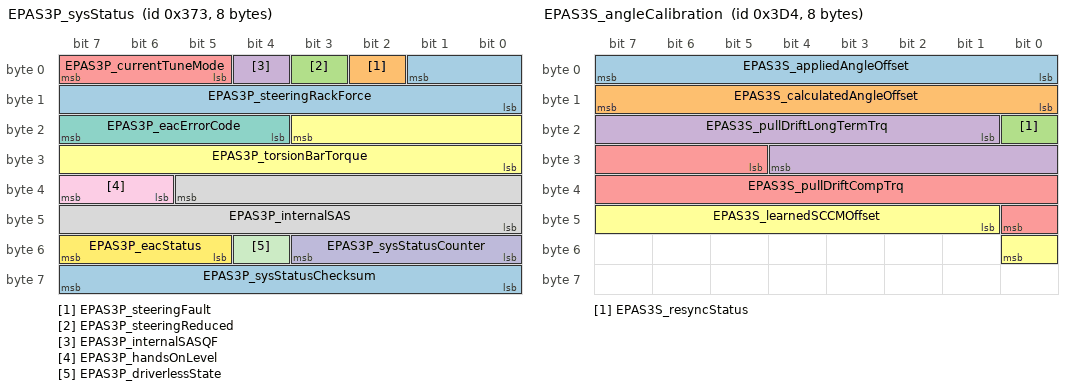
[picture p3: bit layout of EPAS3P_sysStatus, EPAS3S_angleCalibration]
BO_ 883 EPAS3P_sysStatus: 8 EPAS3P
 SG_ EPAS3P_steeringRackForce : 1|10@0+ (50,-25575) [-25575|25525] "N" Vector__XXX
 SG_ EPAS3P_steeringFault : 2|1@1+ (1,0) [0|1] "" Vector__XXX
 SG_ EPAS3P_steeringReduced : 3|1@1+ (1,0) [0|1] "" Vector__XXX
 SG_ EPAS3P_internalSASQF : 4|1@1+ (1,0) [0|1] "" Vector__XXX
 SG_ EPAS3P_currentTuneMode : 5|3@1+ (1,0) [0|7] "" Vector__XXX
 SG_ EPAS3P_torsionBarTorque : 19|12@0+ (0.01,-20.5) [-20.5|20.44] "Nm" Vector__XXX
 SG_ EPAS3P_eacErrorCode : 20|4@1+ (1,0) [0|14] "" Vector__XXX
 SG_ EPAS3P_internalSAS : 37|14@0+ (0.1,-819.2) [-819.2|819] "deg" Vector__XXX
 SG_ EPAS3P_handsOnLevel : 38|2@1+ (1,0) [0|3] "" Vector__XXX
 SG_ EPAS3P_sysStatusCounter : 48|4@1+ (1,0) [0|15] "" Vector__XXX
 SG_ EPAS3P_driverlessState : 52|1@1+ (1,0) [0|1] "" Vector__XXX
 SG_ EPAS3P_eacStatus : 53|3@1+ (1,0) [0|7] "" Vector__XXX
 SG_ EPAS3P_sysStatusChecksum : 56|8@1+ (1,0) [0|255] "" Vector__XXX

BO_ 1592 EPAS3P_udsResponseCH: 8 EPAS3P
 SG_ EPAS3P_udsResponseDataCH : 7|64@0+ (1,0) [0|1.84467440737e+19] "" Vector__XXX

BO_ 1425 EPAS3S_alertLog: 8 EPAS3S
 SG_ EPAS3S_alertID M : 0|8@1+ (1,0) [0|255] "" Vector__XXX
 SG_ EPAS3S_alertState : 15|1@1+ (1,0) [0|1] "" Vector__XXX
 SG_ EPAS3S_a147_transitionReason m147 : 16|2@1+ (1,0) [0|3] "" Vector__XXX
 SG_ EPAS3S_a149_pcbTemp m149 : 16|8@1- (1,60) [-68|187] "degC" Vector__XXX
 SG_ EPAS3S_a150_pcbTemp m150 : 16|8@1- (1,60) [-68|187] "degC" Vector__XXX
 SG_ EPAS3S_a150_phaUMainPathCalcDiff m150 : 24|15@1+ (1,0) [0|32767] "Counts" Vector__XXX
 SG_ EPAS3S_a150_phaVMainPathCalcDiff m150 : 39|15@1+ (1,0) [0|32767] "Counts" Vector__XXX
 SG_ EPAS3S_a150_otherECUAssistStatus m150 : 54|1@1+ (1,0) [0|1] "" Vector__XXX
 SG_ EPAS3S_a155_vehicleSpeed m155 : 16|10@1+ (0.5,0) [0|511.5] "kph" Vector__XXX
 SG_ EPAS3S_a156_vehicleSpeed m156 : 16|10@1+ (0.5,0) [0|511.5] "kph" Vector__XXX
 SG_ EPAS3S_a160_currentSensorStatus m160 : 16|2@1+ (1,0) [0|3] "" Vector__XXX
 SG_ EPAS3S_a160_gateDriverStatus m160 : 18|2@1+ (1,0) [0|3] "" Vector__XXX
 SG_ EPAS3S_a160_highSideDisconnectFe m160 : 20|2@1+ (1,0) [0|3] "" Vector__XXX
 SG_ EPAS3S_a160_phaseDisconnectFetSt m160 : 22|2@1+ (1,0) [0|3] "" Vector__XXX
 SG_ EPAS3S_a160_inverterFetStatus m160 : 24|2@1+ (1,0) [0|3] "" Vector__XXX
 SG_ EPAS3S_a160_hsdFetFailShortTest m160 : 26|2@1+ (1,0) [0|3] "" Vector__XXX
 SG_ EPAS3S_a160_phaDisconnFailOpenTe m160 : 28|2@1+ (1,0) [0|3] "" Vector__XXX
 SG_ EPAS3S_a160_phaDisconnFailShortT m160 : 30|2@1+ (1,0) [0|3] "" Vector__XXX
 SG_ EPAS3S_a160_invFetInitTest m160 : 32|2@1+ (1,0) [0|3] "" Vector__XXX
 SG_ EPAS3S_a160_gateDrvrInitTest m160 : 34|2@1+ (1,0) [0|3] "" Vector__XXX
 SG_ EPAS3S_a160_latentFaultTestTimeo m160 : 36|1@1+ (1,0) [0|1] "" Vector__XXX
 SG_ EPAS3S_a161_pcoMinPhaseBCurrent m161 : 16|12@1- (0.1025,0) [-209.92|209.8175] "Amps" Vector__XXX
 SG_ EPAS3S_a161_pcoMaxPhaseBCurrent m161 : 28|12@1- (0.1025,0) [-209.92|209.8175] "Amps" Vector__XXX
 SG_ EPAS3S_a161_pcoMinPhaseACurrent m161 : 40|12@1- (0.1025,0) [-209.92|209.8175] "Amps" Vector__XXX
 SG_ EPAS3S_a161_pcoMaxPhaseACurrent m161 : 52|12@1- (0.1025,0) [-209.92|209.8175] "Amps" Vector__XXX
 SG_ EPAS3S_a162_vBridgeClosed m162 : 16|16@1+ (0.00537,0) [0|351.92295] "Volts" Vector__XXX
 SG_ EPAS3S_a162_vBridgeOpen m162 : 32|16@1+ (0.00537,0) [0|351.92295] "Volts" Vector__XXX
 SG_ EPAS3S_a163_gateDrvrStatusReg m163 : 16|11@1+ (1,0) [0|2047] "Counts" Vector__XXX
 SG_ EPAS3S_a163_gateDrvrDiag2Reg m163 : 27|9@1+ (1,0) [0|511] "Counts" Vector__XXX
 SG_ EPAS3S_a163_gateDrvrDiag1Reg m163 : 36|9@1+ (1,0) [0|511] "Counts" Vector__XXX
 SG_ EPAS3S_a163_gateDrvrDiag0Reg m163 : 45|9@1+ (1,0) [0|511] "Counts" Vector__XXX
 SG_ EPAS3S_a163_diagStatus m163 : 54|1@1+ (1,0) [0|1] "" Vector__XXX
 SG_ EPAS3S_a163_powerStatus m163 : 55|1@1+ (1,0) [0|1] "" Vector__XXX
 SG_ EPAS3S_a164_dcsRegister0x19 m164 : 16|16@1+ (1,0) [0|65535] "Counts" Vector__XXX
 SG_ EPAS3S_a164_currentSensorRailed m164 : 32|1@1+ (1,0) [0|1] "" Vector__XXX

BO_ 913 EPAS3S_alertMatrix: 8 EPAS3S
 SG_ EPAS3S_matrixIndex M : 0|4@1+ (1,0) [0|15] "" Vector__XXX
 SG_ EPAS3S_a001_sent1Mia m0 : 4|1@1+ (1,0) [0|1] "" Vector__XXX
 SG_ EPAS3S_a002_sent1Error m0 : 5|1@1+ (1,0) [0|1] "" Vector__XXX
 SG_ EPAS3S_a003_trqSens1Supply m0 : 6|1@1+ (1,0) [0|1] "" Vector__XXX
 SG_ EPAS3S_a004_trqSens1Eeprom m0 : 7|1@1+ (1,0) [0|1] "" Vector__XXX
 SG_ EPAS3S_a005_sent2Mia m0 : 8|1@1+ (1,0) [0|1] "" Vector__XXX
 SG_ EPAS3S_a006_sent2Error m0 : 9|1@1+ (1,0) [0|1] "" Vector__XXX
 SG_ EPAS3S_a007_trqSens2Supply m0 : 10|1@1+ (1,0) [0|1] "" Vector__XXX
 SG_ EPAS3S_a008_trqSens2Eeprom m0 : 11|1@1+ (1,0) [0|1] "" Vector__XXX
 SG_ EPAS3S_a009_sentDiff m0 : 12|1@1+ (1,0) [0|1] "" Vector__XXX
 SG_ EPAS3S_a010_trqSensCalError m0 : 13|1@1+ (1,0) [0|1] "" Vector__XXX
 SG_ EPAS3S_a011_currentSensError m0 : 14|1@1+ (1,0) [0|1] "" Vector__XXX
 SG_ EPAS3S_a012_currentSensCalError m0 : 15|1@1+ (1,0) [0|1] "" Vector__XXX
 SG_ EPAS3S_a013_gateDriveError m0 : 16|1@1+ (1,0) [0|1] "" Vector__XXX
 SG_ EPAS3S_a014_gateDriveTxError m0 : 17|1@1+ (1,0) [0|1] "" Vector__XXX
 SG_ EPAS3S_a015_gateDriveEeprom m0 : 18|1@1+ (1,0) [0|1] "" Vector__XXX
 SG_ EPAS3S_a016_phaseUhighUv m0 : 19|1@1+ (1,0) [0|1] "" Vector__XXX
 SG_ EPAS3S_a017_phaseUlowUv m0 : 20|1@1+ (1,0) [0|1] "" Vector__XXX
 SG_ EPAS3S_a018_phaseVhighUv m0 : 21|1@1+ (1,0) [0|1] "" Vector__XXX
 SG_ EPAS3S_a019_phaseVlowUv m0 : 22|1@1+ (1,0) [0|1] "" Vector__XXX
 SG_ EPAS3S_a020_phaseWhighUv m0 : 23|1@1+ (1,0) [0|1] "" Vector__XXX
 SG_ EPAS3S_a021_phaseWlowUv m0 : 24|1@1+ (1,0) [0|1] "" Vector__XXX
 SG_ EPAS3S_a022_phaseUhighOv m0 : 25|1@1+ (1,0) [0|1] "" Vector__XXX
 SG_ EPAS3S_a023_phaseUlowOv m0 : 26|1@1+ (1,0) [0|1] "" Vector__XXX
 SG_ EPAS3S_a024_phaseVhighOv m0 : 27|1@1+ (1,0) [0|1] "" Vector__XXX
 SG_ EPAS3S_a025_phaseVlowOv m0 : 28|1@1+ (1,0) [0|1] "" Vector__XXX
 SG_ EPAS3S_a026_phaseWhighOv m0 : 29|1@1+ (1,0) [0|1] "" Vector__XXX
 SG_ EPAS3S_a027_phaseWlowOv m0 : 30|1@1+ (1,0) [0|1] "" Vector__XXX
 SG_ EPAS3S_a028_phaseUbootUv m0 : 31|1@1+ (1,0) [0|1] "" Vector__XXX
 SG_ EPAS3S_a029_phaseVbootUv m0 : 32|1@1+ (1,0) [0|1] "" Vector__XXX
 SG_ EPAS3S_a030_phaseWbootUv m0 : 33|1@1+ (1,0) [0|1] "" Vector__XXX
 SG_ EPAS3S_a031_abnormalShutdown m0 : 34|1@1+ (1,0) [0|1] "" Vector__XXX
 SG_ EPAS3S_a032_vRegOutputUv m0 : 35|1@1+ (1,0) [0|1] "" Vector__XXX
 SG_ EPAS3S_a033_vRegOutputOv m0 : 36|1@1+ (1,0) [0|1] "" Vector__XXX
 SG_ EPAS3S_a034_vRegError m0 : 37|1@1+ (1,0) [0|1] "" Vector__XXX
 SG_ EPAS3S_a035_vbbSupplyUv m0 : 38|1@1+ (1,0) [0|1] "" Vector__XXX
 SG_ EPAS3S_a036_vbbSupplyOv m0 : 39|1@1+ (1,0) [0|1] "" Vector__XXX
 SG_ EPAS3S_a037_motPos1ParityError m0 : 40|1@1+ (1,0) [0|1] "" Vector__XXX
 SG_ EPAS3S_a038_motPos1Uv m0 : 41|1@1+ (1,0) [0|1] "" Vector__XXX
 SG_ EPAS3S_a039_motPos1MagnetMia m0 : 42|1@1+ (1,0) [0|1] "" Vector__XXX
 SG_ EPAS3S_a040_motPos1LogicError m0 : 43|1@1+ (1,0) [0|1] "" Vector__XXX
 SG_ EPAS3S_a041_motPos1tempError m0 : 44|1@1+ (1,0) [0|1] "" Vector__XXX
 SG_ EPAS3S_a042_motPos2ParityError m0 : 45|1@1+ (1,0) [0|1] "" Vector__XXX
 SG_ EPAS3S_a043_motPos2Uv m0 : 46|1@1+ (1,0) [0|1] "" Vector__XXX
 SG_ EPAS3S_a044_motPos2MagnetMia m0 : 47|1@1+ (1,0) [0|1] "" Vector__XXX
 SG_ EPAS3S_a045_motPos2LogicError m0 : 48|1@1+ (1,0) [0|1] "" Vector__XXX
 SG_ EPAS3S_a046_motPos2tempError m0 : 49|1@1+ (1,0) [0|1] "" Vector__XXX
 SG_ EPAS3S_a047_motPosCorrError m0 : 50|1@1+ (1,0) [0|1] "" Vector__XXX
 SG_ EPAS3S_a048_motPosCalError m0 : 51|1@1+ (1,0) [0|1] "" Vector__XXX
 SG_ EPAS3S_a049_piCtrlError m0 : 52|1@1+ (1,0) [0|1] "" Vector__XXX
 SG_ EPAS3S_a050_mcuSmuError m0 : 53|1@1+ (1,0) [0|1] "" Vector__XXX
 SG_ EPAS3S_a051_mcuSupError m0 : 54|1@1+ (1,0) [0|1] "" Vector__XXX
 SG_ EPAS3S_a052_intWatchdogError m0 : 55|1@1+ (1,0) [0|1] "" Vector__XXX
 SG_ EPAS3S_a053_extWatchdogError m0 : 56|1@1+ (1,0) [0|1] "" Vector__XXX
 SG_ EPAS3S_a054_memoryProtectError m0 : 57|1@1+ (1,0) [0|1] "" Vector__XXX
 SG_ EPAS3S_a055_floatPointError m0 : 58|1@1+ (1,0) [0|1] "" Vector__XXX
 SG_ EPAS3S_a056_battUv m0 : 59|1@1+ (1,0) [0|1] "" Vector__XXX
 SG_ EPAS3S_a057_battUvReduced m0 : 60|1@1+ (1,0) [0|1] "" Vector__XXX
 SG_ EPAS3S_a058_battOv m0 : 61|1@1+ (1,0) [0|1] "" Vector__XXX
 SG_ EPAS3S_a059_battOvReduced m0 : 62|1@1+ (1,0) [0|1] "" Vector__XXX
 SG_ EPAS3S_a060_battBridgeDiff m0 : 63|1@1+ (1,0) [0|1] "" Vector__XXX
 SG_ EPAS3S_a061_bridgeUv m1 : 4|1@1+ (1,0) [0|1] "" Vector__XXX
 SG_ EPAS3S_a062_assistCorrError m1 : 5|1@1+ (1,0) [0|1] "" Vector__XXX
 SG_ EPAS3S_a063_dampCorrError m1 : 6|1@1+ (1,0) [0|1] "" Vector__XXX
 SG_ EPAS3S_a064_phaseCompCorrError m1 : 7|1@1+ (1,0) [0|1] "" Vector__XXX
 SG_ EPAS3S_a065_trqTarCorrError m1 : 8|1@1+ (1,0) [0|1] "" Vector__XXX
 SG_ EPAS3S_a066_returnCorrError m1 : 9|1@1+ (1,0) [0|1] "" Vector__XXX
 SG_ EPAS3S_a067_yawDampCorrError m1 : 10|1@1+ (1,0) [0|1] "" Vector__XXX
 SG_ EPAS3S_a068_hystCorrError m1 : 11|1@1+ (1,0) [0|1] "" Vector__XXX
 SG_ EPAS3S_a069_eacCorrError m1 : 12|1@1+ (1,0) [0|1] "" Vector__XXX
 SG_ EPAS3S_a070_hodCorrError m1 : 13|1@1+ (1,0) [0|1] "" Vector__XXX
 SG_ EPAS3S_a071_vehSpdCorrError m1 : 14|1@1+ (1,0) [0|1] "" Vector__XXX
 SG_ EPAS3S_a072_motFeedFwdError m1 : 15|1@1+ (1,0) [0|1] "" Vector__XXX
 SG_ EPAS3S_a073_motParEstError m1 : 16|1@1+ (1,0) [0|1] "" Vector__XXX
 SG_ EPAS3S_a074_overHeatProtect m1 : 17|1@1+ (1,0) [0|1] "" Vector__XXX
 SG_ EPAS3S_a075_fspPwrCut m1 : 18|1@1+ (1,0) [0|1] "" Vector__XXX
 SG_ EPAS3S_a076_tempSensOutofRange m1 : 19|1@1+ (1,0) [0|1] "" Vector__XXX
 SG_ EPAS3S_a077_highSideFetError m1 : 20|1@1+ (1,0) [0|1] "" Vector__XXX
 SG_ EPAS3S_a078_phaseDisconnectError m1 : 21|1@1+ (1,0) [0|1] "" Vector__XXX
 SG_ EPAS3S_a079_backupCurrentPlaus m1 : 22|1@1+ (1,0) [0|1] "" Vector__XXX
 SG_ EPAS3S_a080_ecuInitArbError m1 : 23|1@1+ (1,0) [0|1] "" Vector__XXX
 SG_ EPAS3S_a081_coggCompError m1 : 24|1@1+ (1,0) [0|1] "" Vector__XXX
 SG_ EPAS3S_a082_polarityCalError m1 : 25|1@1+ (1,0) [0|1] "" Vector__XXX
 SG_ EPAS3S_a083_crcMismatch m1 : 26|1@1+ (1,0) [0|1] "" Vector__XXX
 SG_ EPAS3S_a084_eacCancelled m1 : 27|1@1+ (1,0) [0|1] "" Vector__XXX
 SG_ EPAS3S_a085_canBusOff m1 : 28|1@1+ (1,0) [0|1] "" Vector__XXX
 SG_ EPAS3S_a086_dasMia m1 : 29|1@1+ (1,0) [0|1] "" Vector__XXX
 SG_ EPAS3S_a087_dasCntError m1 : 30|1@1+ (1,0) [0|1] "" Vector__XXX
 SG_ EPAS3S_a088_dasCsError m1 : 31|1@1+ (1,0) [0|1] "" Vector__XXX
 SG_ EPAS3S_a089_espWsMia m1 : 32|1@1+ (1,0) [0|1] "" Vector__XXX
 SG_ EPAS3S_a090_espWsCntError m1 : 33|1@1+ (1,0) [0|1] "" Vector__XXX
 SG_ EPAS3S_a091_espWsCsError m1 : 34|1@1+ (1,0) [0|1] "" Vector__XXX
 SG_ EPAS3S_a092_espWrMia m1 : 35|1@1+ (1,0) [0|1] "" Vector__XXX
 SG_ EPAS3S_a093_espWrCntError m1 : 36|1@1+ (1,0) [0|1] "" Vector__XXX
 SG_ EPAS3S_a094_espWrCsError m1 : 37|1@1+ (1,0) [0|1] "" Vector__XXX
 SG_ EPAS3S_a095_espWsStatus m1 : 38|1@1+ (1,0) [0|1] "" Vector__XXX
 SG_ EPAS3S_a096_rcmMia m1 : 39|1@1+ (1,0) [0|1] "" Vector__XXX
 SG_ EPAS3S_a097_rcmCntError m1 : 40|1@1+ (1,0) [0|1] "" Vector__XXX
 SG_ EPAS3S_a098_rcmCsError m1 : 41|1@1+ (1,0) [0|1] "" Vector__XXX
 SG_ EPAS3S_a099_yawRateStatus m1 : 42|1@1+ (1,0) [0|1] "" Vector__XXX
 SG_ EPAS3S_a100_diMia m1 : 43|1@1+ (1,0) [0|1] "" Vector__XXX
 SG_ EPAS3S_a101_diCntError m1 : 44|1@1+ (1,0) [0|1] "" Vector__XXX
 SG_ EPAS3S_a102_diCsError m1 : 45|1@1+ (1,0) [0|1] "" Vector__XXX
 SG_ EPAS3S_a103_vcFrontMia m1 : 46|1@1+ (1,0) [0|1] "" Vector__XXX
 SG_ EPAS3S_a104_vcFrontCntError m1 : 47|1@1+ (1,0) [0|1] "" Vector__XXX
 SG_ EPAS3S_a105_vcFrontCsError m1 : 48|1@1+ (1,0) [0|1] "" Vector__XXX
 SG_ EPAS3S_a106_vcFrontTempMia m1 : 49|1@1+ (1,0) [0|1] "" Vector__XXX
 SG_ EPAS3S_a107_uiTuneReqMia m1 : 50|1@1+ (1,0) [0|1] "" Vector__XXX
 SG_ EPAS3S_a108_uiTuneReqCntError m1 : 51|1@1+ (1,0) [0|1] "" Vector__XXX
 SG_ EPAS3S_a109_uiTuneReqCsError m1 : 52|1@1+ (1,0) [0|1] "" Vector__XXX
 SG_ EPAS3S_a110_sasMia m1 : 53|1@1+ (1,0) [0|1] "" Vector__XXX
 SG_ EPAS3S_a111_sasCntError m1 : 54|1@1+ (1,0) [0|1] "" Vector__XXX
 SG_ EPAS3S_a112_sasCsError m1 : 55|1@1+ (1,0) [0|1] "" Vector__XXX
 SG_ EPAS3S_a113_sasStatusError m1 : 56|1@1+ (1,0) [0|1] "" Vector__XXX
 SG_ EPAS3S_a114_gtwConfigMia m1 : 57|1@1+ (1,0) [0|1] "" Vector__XXX
 SG_ EPAS3S_a115_ecuStatMia m1 : 58|1@1+ (1,0) [0|1] "" Vector__XXX
 SG_ EPAS3S_a116_ecuStatCntError m1 : 59|1@1+ (1,0) [0|1] "" Vector__XXX
 SG_ EPAS3S_a117_ecuStatCrcError m1 : 60|1@1+ (1,0) [0|1] "" Vector__XXX
 SG_ EPAS3S_a118_privateBusOff m1 : 61|1@1+ (1,0) [0|1] "" Vector__XXX
 SG_ EPAS3S_a119_pvtEcuStatMia m1 : 62|1@1+ (1,0) [0|1] "" Vector__XXX
 SG_ EPAS3S_a120_pvtEcuStatCntError m1 : 63|1@1+ (1,0) [0|1] "" Vector__XXX
 SG_ EPAS3S_a121_pvtEcuStatCrcError m2 : 4|1@1+ (1,0) [0|1] "" Vector__XXX
 SG_ EPAS3S_a122_olpActive m2 : 5|1@1+ (1,0) [0|1] "" Vector__XXX
 SG_ EPAS3S_a123_combEcu2StatFail m2 : 6|1@1+ (1,0) [0|1] "" Vector__XXX
 SG_ EPAS3S_a124_tempSensStuckInRange m2 : 7|1@1+ (1,0) [0|1] "" Vector__XXX
 SG_ EPAS3S_a125_trqSensTrimOutRange m2 : 8|1@1+ (1,0) [0|1] "" Vector__XXX
 SG_ EPAS3S_a126_apsMia m2 : 9|1@1+ (1,0) [0|1] "" Vector__XXX
 SG_ EPAS3S_a127_apsCntError m2 : 10|1@1+ (1,0) [0|1] "" Vector__XXX
 SG_ EPAS3S_a128_apsCsError m2 : 11|1@1+ (1,0) [0|1] "" Vector__XXX
 SG_ EPAS3S_a129_combEcu1StatFail m2 : 12|1@1+ (1,0) [0|1] "" Vector__XXX
 SG_ EPAS3S_a130_sasOffsetNotCal m2 : 13|1@1+ (1,0) [0|1] "" Vector__XXX
 SG_ EPAS3S_a131_phaseFeedbackError m2 : 14|1@1+ (1,0) [0|1] "" Vector__XXX
 SG_ EPAS3S_a132_motFeedFwdCounter25 m2 : 15|1@1+ (1,0) [0|1] "" Vector__XXX
 SG_ EPAS3S_a133_motFeedFwdCounter50 m2 : 16|1@1+ (1,0) [0|1] "" Vector__XXX
 SG_ EPAS3S_a134_motFeedFwdCounter85 m2 : 17|1@1+ (1,0) [0|1] "" Vector__XXX
 SG_ EPAS3S_a135_piCtrlCounter25 m2 : 18|1@1+ (1,0) [0|1] "" Vector__XXX
 SG_ EPAS3S_a136_piCtrlCounter50 m2 : 19|1@1+ (1,0) [0|1] "" Vector__XXX
 SG_ EPAS3S_a137_piCtrlCounter85 m2 : 20|1@1+ (1,0) [0|1] "" Vector__XXX
 SG_ EPAS3S_a144_diSpdMia m2 : 21|1@1+ (1,0) [0|1] "" Vector__XXX
 SG_ EPAS3S_a145_diSpdCntError m2 : 22|1@1+ (1,0) [0|1] "" Vector__XXX
 SG_ EPAS3S_a146_diSpdCsError m2 : 23|1@1+ (1,0) [0|1] "" Vector__XXX
 SG_ EPAS3S_a147_backupVehSpeed m2 : 24|1@1+ (1,0) [0|1] "" Vector__XXX
 SG_ EPAS3S_a148_vMaxAssist m2 : 25|1@1+ (1,0) [0|1] "" Vector__XXX
 SG_ EPAS3S_a149_currentSensPathSwitc m2 : 26|1@1+ (1,0) [0|1] "" Vector__XXX
 SG_ EPAS3S_a150_currentSensOffsetDet m2 : 27|1@1+ (1,0) [0|1] "" Vector__XXX
 SG_ EPAS3S_a151_dcsCboot m2 : 28|1@1+ (1,0) [0|1] "" Vector__XXX
 SG_ EPAS3S_a152_dcsDiagReg m2 : 29|1@1+ (1,0) [0|1] "" Vector__XXX
 SG_ EPAS3S_a153_dcsInitOffset m2 : 30|1@1+ (1,0) [0|1] "" Vector__XXX
 SG_ EPAS3S_a154_assistTorqueDisabled m2 : 31|1@1+ (1,0) [0|1] "" Vector__XXX
 SG_ EPAS3S_a155_backupEacActive m2 : 32|1@1+ (1,0) [0|1] "" Vector__XXX
 SG_ EPAS3S_a156_angleSensorDivergenc m2 : 33|1@1+ (1,0) [0|1] "" Vector__XXX
 SG_ EPAS3S_a157_pmState2Mia m2 : 34|1@1+ (1,0) [0|1] "" Vector__XXX
 SG_ EPAS3S_a158_pmState2CntError m2 : 35|1@1+ (1,0) [0|1] "" Vector__XXX
 SG_ EPAS3S_a159_pmState2CsError m2 : 36|1@1+ (1,0) [0|1] "" Vector__XXX
 SG_ EPAS3S_a160_latentFaultTestResul m2 : 37|1@1+ (1,0) [0|1] "" Vector__XXX
 SG_ EPAS3S_a161_initTestPhaDisconnIn m2 : 38|1@1+ (1,0) [0|1] "" Vector__XXX
 SG_ EPAS3S_a162_initTestHSDFetInfo m2 : 39|1@1+ (1,0) [0|1] "" Vector__XXX
 SG_ EPAS3S_a163_initTestGateDrvrInfo m2 : 40|1@1+ (1,0) [0|1] "" Vector__XXX
 SG_ EPAS3S_a164_initTestDCSInfo m2 : 41|1@1+ (1,0) [0|1] "" Vector__XXX
 SG_ EPAS3S_a165_epbStatusMia m2 : 42|1@1+ (1,0) [0|1] "" Vector__XXX
 SG_ EPAS3S_a166_epbStatusCntError m2 : 43|1@1+ (1,0) [0|1] "" Vector__XXX
 SG_ EPAS3S_a167_epbStatusCsError m2 : 44|1@1+ (1,0) [0|1] "" Vector__XXX
 SG_ EPAS3S_a168_torsionBarTorqueQfDe m2 : 45|1@1+ (1,0) [0|1] "" Vector__XXX

BO_ 980 EPAS3S_angleCalibration: 8 EPAS3S
 SG_ EPAS3S_appliedAngleOffset : 0|8@1+ (0.1,-12.8) [-12.8|12.7] "deg" Vector__XXX
 SG_ EPAS3S_calculatedAngleOffset : 8|8@1+ (0.1,-12.8) [-12.8|12.7] "deg" Vector__XXX
 SG_ EPAS3S_resyncStatus : 16|1@1+ (1,0) [0|1] "" Vector__XXX
 SG_ EPAS3S_pullDriftLongTermTrq : 17|12@1+ (0.01,-10) [-10|10] "Nm" Vector__XXX
 SG_ EPAS3S_pullDriftCompTrq : 29|12@1+ (0.01,-10) [-10|10] "Nm" Vector__XXX
 SG_ EPAS3S_learnedSCCMOffset : 41|8@1+ (0.1,-12.8) [-12.8|12.7] "deg" Vector__XXX

BO_TX_BU_ 2006 : DI;
BO_TX_BU_ 597 : DI;
BO_TX_BU_ 296 : DI;
BO_TX_BU_ 616 : DI;
BO_TX_BU_ 280 : DI;
BO_TX_BU_ 2036 : DI;
BO_TX_BU_ 615 : DI;
BO_TX_BU_ 1237 : DPB;
BO_TX_BU_ 999 : DPB;
BO_TX_BU_ 1426 : EPAS3P;
BO_TX_BU_ 2035 : EPAS3P;
BO_TX_BU_ 977 : EPAS3P;
BO_TX_BU_ 817 : EPAS3P;
BO_TX_BU_ 883 : EPAS3P;
BO_TX_BU_ 1592 : EPAS3P;
BO_TX_BU_ 1425 : EPAS3S;
BO_TX_BU_ 913 : EPAS3S;
BO_TX_BU_ 980 : EPAS3S;
CM_ BO_ 2006 "Drive inverter message: stalkless interfaces";
CM_ SG_ 2006 DI_stalklessInterfacesChecksum "Drive inverter: stalkless interfaces checksum";
CM_ SG_ 2006 DI_stalklessInterfacesCounter "Drive inverter: stalkless interfaces counter";
CM_ SG_ 2006 DI_smartShiftClosureOpen "Drive inverter: smart shift closure open";
CM_ SG_ 2006 DI_smartShiftSeatbeltUnbuckled "Drive inverter: smart shift seatbelt unbuckled";
CM_ SG_ 2006 DI_smartShiftAvailable "Drive inverter: smart shift available";
CM_ SG_ 2006 DI_smartShiftPrimed "Drive inverter: smart shift primed";
CM_ SG_ 2006 DI_smartShiftBrakePressed "Drive inverter: smart shift brake pressed";
CM_ SG_ 2006 DI_smartShiftBrakeReapplyRequire "Drive inverter: smart shift brake reapply required";
CM_ BO_ 597 "Drive inverter message: suggested gear";
CM_ SG_ 597 DI_lastQualifiedGear "Drive inverter: last qualified gear; raw 7 = signal not available (SNA)";
CM_ SG_ 597 DI_lastDrivingGear "Drive inverter: last driving gear; raw 7 = signal not available (SNA)";
CM_ SG_ 597 DI_distDrivenInGear "Drive inverter: dist driven in gear";
CM_ SG_ 597 DI_frontBlocked "Drive inverter: front blocked";
CM_ SG_ 597 DI_rearBlocked "Drive inverter: rear blocked";
CM_ SG_ 597 DI_firstShiftOccurred "Drive inverter: first shift occurred";
CM_ SG_ 597 DI_suggestedGearReason "Reason for the suggested gear";
CM_ SG_ 597 DI_parallelParked "Drive inverter: parallel parked";
CM_ SG_ 597 DI_smartShiftGear "Gear vehicle will shift into if smart shift occurs";
CM_ SG_ 597 DI_smartShiftUnavailableReason "Reports the reason why Smart Shift is unavailable; raw 0 = signal not available (SNA)";
CM_ BO_ 296 "Drive inverter message: system limits";
CM_ SG_ 296 DI_limitRegenPower "TRUE when torque is limited due to regen power limit.";
CM_ SG_ 296 DI_limitIBat "TRUE when torque is limited due to battery current.";
CM_ SG_ 296 DI_limitVBatLow "Drive inverter: limit v bat low";
CM_ SG_ 296 DI_limitVBatHigh "Drive inverter: limit v bat high";
CM_ SG_ 296 DI_limitObstacleDetection "TRUE when torque is limited due to obstacle detected in vehicle path.";
CM_ SG_ 296 DI_limitSystemLimp "Drive inverter: limit system limp";
CM_ SG_ 296 DI_limitSystemGPO "Drive inverter: limit system GPO";
CM_ SG_ 296 DI_limitShift "Drive inverter: limit shift";
CM_ SG_ 296 DI_limitDriveTorque "TRUE when drive torque is limited due to driver torque limit command";
CM_ SG_ 296 DI_limitRegenTorque "TRUE when regen torque is limited due to driver torque limit command";
CM_ SG_ 296 DI_limitVehicleSpeed "Drive inverter: limit vehicle speed";
CM_ SG_ 296 DI_limitBmsMiaFreeze "Drive inverter: limit bms mia freeze";
CM_ SG_ 296 DI_limitSystemSpinDownLearning "Drive inverter: limit system spin down learning";
CM_ SG_ 296 DI_limitCdp "Drive inverter: limit cdp";
CM_ SG_ 296 DI_vehicleSpeedLimitType "Speed limit source/type of DI_vehicleSpeedLimit.";
CM_ SG_ 296 DI_vehicleSpeedLimit "Vehicle speed limit (including powertrain limits) being enforced by the DI and published to the UI; raw 511 = signal not available (SNA)";
CM_ SG_ 296 DI_vehicleSpeedLimitReason "Speed limit reason of DI_vehicleSpeedLimit.";
CM_ SG_ 296 DI_proximity "TRUE if the proximity hardware input signal is active.";
CM_ SG_ 296 DI_limitClosureNotClosed "Drive inverter: limit closure not closed";
CM_ SG_ 296 DI_undersideAbuse "Drive inverter: underside abuse";
CM_ SG_ 296 DI_immobilizerAuthLevel "Immobilizer Authentication Level";
CM_ SG_ 296 DI_manualRecoveryDistanceRemaini "Drive inverter: manual recovery distance remaining; raw 127 = signal not available (SNA)";
CM_ SG_ 296 DI_restrictedDrivingMode "Drive inverter: restricted driving mode";
CM_ BO_ 616 "Drive inverter message: system power";
CM_ SG_ 616 DI_sysHeatPowerMax "Drive inverter: sys heat power max";
CM_ SG_ 616 DI_sysHeatPowerActual "Drive Inverter system heat power";
CM_ SG_ 616 DI_sysDrivePowerMax "Maximum drive power output total for all motors; raw 511 = signal not available (SNA)";
CM_ SG_ 616 DI_primaryUnitSiliconType "Drive inverter: primary unit silicon type";
CM_ SG_ 616 DI_sysRegenPowerMax "Maximum regen power output total for all motors; raw 255 = signal not available (SNA)";
CM_ BO_ 280 "Drive inverter message: system status";
CM_ SG_ 280 DI_systemStatusChecksum "Drive inverter: system status checksum";
CM_ SG_ 280 DI_systemStatusCounter "Drive inverter: system status counter";
CM_ SG_ 280 DI_secondaryGearControlStatus "Indicates if gear control through PRND is being honored";
CM_ SG_ 280 DI_immobilizerState "Detects state of the Drive Inverter (DI) immobilizer; raw 0 = signal not available (SNA)";
CM_ SG_ 280 DI_systemState "DI system state machine state.";
CM_ SG_ 280 DI_brakePedalState "Brake pedal switch signal sensed at the drive inverter.";
CM_ SG_ 280 DI_gear "Detects the current operating gear reported by the drive inverter; raw 7 = signal not available (SNA)";
CM_ SG_ 280 DI_driveBlocked "Reason drive unit is blocked from entering enable";
CM_ SG_ 280 DI_hvilSystemStatus "Aggregated HVIL system status; raw 3 = signal not available (SNA)";
CM_ SG_ 280 DI_driveModeState "System drive mode state";
CM_ SG_ 280 DI_shiftRequestType "Type of most recent shift request";
CM_ SG_ 280 DI_accelPedalPos "Drive Inverter measured accelerator pedal position; raw 255 = signal not available (SNA)";
CM_ SG_ 280 DI_tractionControlMode "Active traction control mode as requested by the driver.";
CM_ SG_ 280 DI_dynoModeAvailable "Reports to the vehicle if the Drive Inverter (DI) will accept a request to enter dyno mode.";
CM_ SG_ 280 DI_epbRequest "Reports Electronic Parking Brake (EPB) requests.";
CM_ SG_ 280 DI_brakeSource "Drive inverter: brake source";
CM_ SG_ 280 DI_keepDrivePowerStateRequest "Reports that the Drive Inverter (DI) expects vehicle power state to remain in drive.";
CM_ SG_ 280 DI_trackModeState "Indicates state of Track mode";
CM_ SG_ 280 DI_autonomyControlActive "Drive inverter: autonomy control active";
CM_ SG_ 280 DI_regenLight "Drive inverter: regen light";
CM_ SG_ 280 DI_vehicleAcceleration "Drive inverter: vehicle acceleration; raw 2048 = signal not available (SNA)";
CM_ BO_ 2036 "Drive inverter message: vdc right";
CM_ SG_ 2036 DI_vdcRightChecksum "Drive inverter: vdc right checksum";
CM_ SG_ 2036 DI_vdcRightCounter "Drive inverter: vdc right counter";
CM_ SG_ 2036 DI_vdcCommandTypeFrR "Drive inverter: vdc command type fr r";
CM_ SG_ 2036 DI_vdcCommandTypeReR "Drive inverter: vdc command type re r";
CM_ SG_ 2036 DI_vdcCommandABSFrR "Drive inverter: vdc command ABS fr r";
CM_ SG_ 2036 DI_vdcCommandABSReR "Drive inverter: vdc command ABS re r";
CM_ SG_ 2036 DI_brakeTorqueTarFrR "Drive inverter: brake torque tar fr r";
CM_ SG_ 2036 DI_brakeTorqueTarReR "Drive inverter: brake torque tar re r";
CM_ SG_ 2036 DI_wheelSlipLimitFrR "Drive inverter: wheel slip limit fr r";
CM_ SG_ 2036 DI_wheelSlipLimitReR "Drive inverter: wheel slip limit re r";
CM_ SG_ 2036 DI_rawLowMuProbability "Drive inverter: raw low mu probability";
CM_ BO_ 615 "Drive inverter message: vehicle estimates";
CM_ SG_ 615 DI_mass "Detects learned mass.";
CM_ SG_ 615 DI_massRLS "Drive inverter: mass RLS";
CM_ SG_ 615 DI_trailerDetected "Drive inverter: trailer detected";
CM_ SG_ 615 DI_vehicleEstimatesCounter "Drive inverter: vehicle estimates counter";
CM_ SG_ 615 DI_relativeTireTreadDepth "Reports estimate of tire wear ratio, represented in estimated tread depth difference between front and rear tires. A positive value indicates the rear tires are more worn than the front tires; raw 32 = signal not available (SNA)";
CM_ SG_ 615 DI_tireFitment "Drive inverter: tire fitment; raw 3 = signal not available (SNA)";
CM_ SG_ 615 DI_rollCoeff "Drive inverter: roll coeff";
CM_ SG_ 615 DI_massConfidence "Drive inverter: mass confidence";
CM_ SG_ 615 DI_gradeEst "Grade estimate reported by the drive inverter.";
CM_ SG_ 615 DI_vehicleEstimatesChecksum "Drive inverter: vehicle estimates checksum";
CM_ SG_ 615 DI_gradeEstInternal "Drive inverter: grade est internal";
CM_ SG_ 615 DI_massConfidenceRLS "Drive inverter: mass confidence RLS";
CM_ SG_ 615 DI_steeringAngleOffset "Steering angle offset learned by vehicle dynamics control (VDC) represented as a hand wheel angle";
CM_ BO_ 1237 "DPB ECU message: alert log";
CM_ SG_ 1237 DPB_alertID "DPB ECU: alert ID";
CM_ SG_ 1237 DPB_alertState "DPB ECU: alert state";
CM_ BO_ 999 "DPB ECU message: alert matrix";
CM_ SG_ 999 DPB_matrixIndex "DPB ECU: matrix index";
CM_ SG_ 999 DPB_a001_pPlungerSensorOffsetHig "DPB ECU: a001 p plunger sensor offset high";
CM_ SG_ 999 DPB_a002_pMC2SensorOffsetHigh "DPB ECU: a002 p MC2 sensor offset high";
CM_ SG_ 999 DPB_a003_AswEEPROMReadFailure "DPB ECU: a003 asw EEPROM read failure";
CM_ SG_ 999 DPB_a004_assertionFault "DPB ECU: a004 assertion fault";
CM_ SG_ 999 DPB_a005_hardPedalChar "DPB ECU: a005 hard pedal char";
CM_ SG_ 999 DPB_a006_hardPedalCharGoodCheck "DPB ECU: a006 hard pedal char good check";
CM_ SG_ 999 DPB_a007_PMCLeakageDetected "DPB ECU: a007 PMC leakage detected";
CM_ SG_ 999 DPB_a008_LiPSPts1Offset "DPB ECU: a008 li PS pts1 offset";
CM_ SG_ 999 DPB_a009_LiPSPts2Offset "DPB ECU: a009 li PS pts2 offset";
CM_ SG_ 999 DPB_a010_LiPSPtsConsistency "DPB ECU: a010 li PS pts consistency";
CM_ SG_ 999 DPB_a011_PtsNonZeroStage1 "DPB ECU: a011 pts non zero stage1";
CM_ SG_ 999 DPB_a012_PtsNonZeroStage2 "DPB ECU: a012 pts non zero stage2";
CM_ SG_ 999 DPB_a013_softPedalChar "DPB ECU: a013 soft pedal char";
CM_ SG_ 999 DPB_a014_CANControllerHWFault "DPB ECU: a014 CAN controller HW fault";
CM_ SG_ 999 DPB_a015_CAN1BusOff "DPB ECU: a015 CAN1 bus off";
CM_ SG_ 999 DPB_a016_CAN2BusOff "DPB ECU: a016 CAN2 bus off";
CM_ SG_ 999 DPB_a017_largeLeakageDetected "DPB ECU: a017 large leakage detected";
CM_ SG_ 999 DPB_a018_largeLeakageDetectedGoo "DPB ECU: a018 large leakage detected good check";
CM_ SG_ 999 DPB_a019_DETReportError "DPB ECU: a019 DET report error";
CM_ SG_ 999 DPB_a020_ecuHuMismatch "DPB ECU: a020 ecu hu mismatch";
CM_ SG_ 999 DPB_a021_brakeSystemOverheatLvl1 "DPB ECU: a021 brake system overheat lvl1";
CM_ SG_ 999 DPB_a022_brakeSystemOverheatLvl2 "DPB ECU: a022 brake system overheat lvl2";
CM_ SG_ 999 DPB_a023_initialPlungerCheckFail "DPB ECU: a023 initial plunger check failed";
CM_ SG_ 999 DPB_a024_ESPLDMFailure "DPB ECU: a024 ESPLDM failure";
CM_ SG_ 999 DPB_a025_backupCircuitLeakage "DPB ECU: a025 backup circuit leakage";
CM_ SG_ 999 DPB_a026_LiPSIDTimeout "DPB ECU: a026 li PSID timeout";
CM_ SG_ 999 DPB_a027_motorTempHighLevel1 "DPB ECU: a027 motor temp high level1";
CM_ SG_ 999 DPB_a028_motorTempHighLevel2 "DPB ECU: a028 motor temp high level2";
CM_ SG_ 999 DPB_a029_motorTestFault "DPB ECU: a029 motor test fault";
CM_ SG_ 999 DPB_a030_notShutDownRight "DPB ECU: a030 not shut down right";
CM_ SG_ 999 DPB_a031_HWParamReadFailed "DPB ECU: a031 HW param read failed";
CM_ SG_ 999 DPB_a032_HWParamWriteFailed "DPB ECU: a032 HW param write failed";
CM_ SG_ 999 DPB_a033_motorDynamicLimited "DPB ECU: a033 motor dynamic limited";
CM_ SG_ 999 DPB_a034_lipsMemoryEmpty "DPB ECU: a034 lips memory empty";
CM_ SG_ 999 DPB_a035_PDURouterinitialization "DPB ECU: a035 PDU routerinitialization failed";
CM_ SG_ 999 DPB_a036_lossOfPDUInstanceDetect "DPB ECU: a036 loss of PDU instance detected";
CM_ SG_ 999 DPB_a037_plungerCircuitPressHigh "DPB ECU: a037 plunger circuit press high";
CM_ SG_ 999 DPB_a038_plungerCircuitPressHigh "DPB ECU: a038 plunger circuit press high good check";
CM_ SG_ 999 DPB_a039_plungerCircuitPressLow "DPB ECU: a039 plunger circuit press low";
CM_ SG_ 999 DPB_a040_plungerCircuitPressLowG "DPB ECU: a040 plunger circuit press low good check";
CM_ SG_ 999 DPB_a041_PSCGearRatioReadFault "DPB ECU: a041 PSC gear ratio read fault";
CM_ SG_ 999 DPB_a042_motorLoadPressImplausib "DPB ECU: a042 motor load press implausible";
CM_ SG_ 999 DPB_a043_PSCMotorSizeReadFault "DPB ECU: a043 PSC motor size read fault";
CM_ SG_ 999 DPB_a044_supplyOvervoltageLvl1 "DPB ECU: a044 supply overvoltage lvl1";
CM_ SG_ 999 DPB_a045_supplyOvervoltageLvl2 "DPB ECU: a045 supply overvoltage lvl2";
CM_ SG_ 999 DPB_a046_supplyOvervoltageLvl3 "DPB ECU: a046 supply overvoltage lvl3";
CM_ SG_ 999 DPB_a047_pPlungerPlausCheckFailu "DPB ECU: a047 p plunger plaus check failure";
CM_ SG_ 999 DPB_a048_supplyUndervoltageLvl1 "DPB ECU: a048 supply undervoltage lvl1";
CM_ SG_ 999 DPB_a049_supplyUndervoltageLvl2 "DPB ECU: a049 supply undervoltage lvl2";
CM_ SG_ 999 DPB_a050_supplyUndervoltageLvl3 "DPB ECU: a050 supply undervoltage lvl3";
CM_ SG_ 999 DPB_a051_PSCVoltageImplausible "DPB ECU: a051 PSC voltage implausible";
CM_ SG_ 999 DPB_a052_PSIDTimeOut "DPB ECU: a052 PSID time out";
CM_ SG_ 999 DPB_a053_hydraulicAssemblyModeAc "DPB ECU: a053 hydraulic assembly mode active";
CM_ SG_ 999 DPB_a054_unsupportedHW "DPB ECU: a054 unsupported HW";
CM_ SG_ 999 DPB_a055_unsupportedSeriesHWDete "DPB ECU: a055 unsupported series HW detected";
CM_ SG_ 999 DPB_a056_AdcPeripheralFault "DPB ECU: a056 adc peripheral fault";
CM_ SG_ 999 DPB_a057_AdcPinTest "DPB ECU: a057 adc pin test";
CM_ SG_ 999 DPB_a058_AdcSelftestC5P "DPB ECU: a058 adc selftest C5 p";
CM_ SG_ 999 DPB_a059_factoryModeActive "DPB ECU: a059 factory mode active";
CM_ SG_ 999 DPB_a060_motorBridgeDriverFault "DPB ECU: a060 motor bridge driver fault";
CM_ SG_ 999 DPB_a061_bridgeSwitchInitError "DPB ECU: a061 bridge switch init error";
CM_ SG_ 999 DPB_a062_loadDumpOnFSLTest "DPB ECU: a062 load dump on FSL test";
CM_ SG_ 999 DPB_a063_motorConfigMismatch "DPB ECU: a063 motor config mismatch";
CM_ SG_ 999 DPB_a064_current1OffsetHigh "DPB ECU: a064 current1 offset high";
CM_ SG_ 999 DPB_a065_current1OffsetLow "DPB ECU: a065 current1 offset low";
CM_ SG_ 999 DPB_a066_current2OffsetHigh "DPB ECU: a066 current2 offset high";
CM_ SG_ 999 DPB_a067_current2OffsetLow "DPB ECU: a067 current2 offset low";
CM_ SG_ 999 DPB_a068_BLMMuxerTimeoutError "DPB ECU: a068 BLM muxer timeout error";
CM_ SG_ 999 DPB_a069_OBDCurrent1OORHigh "DPB ECU: a069 OBD current1 OOR high";
CM_ SG_ 999 DPB_a070_OBDCurrent1OORLow "DPB ECU: a070 OBD current1 OOR low";
CM_ SG_ 999 DPB_a071_OBDCurrent2OORHigh "DPB ECU: a071 OBD current2 OOR high";
CM_ SG_ 999 DPB_a072_OBDCurrent2OORLow "DPB ECU: a072 OBD current2 OOR low";
CM_ SG_ 999 DPB_a073_rotorCosOutOfRangeHigh "DPB ECU: a073 rotor cos out of range high";
CM_ SG_ 999 DPB_a074_rotorCosOutOfRangeLow "DPB ECU: a074 rotor cos out of range low";
CM_ SG_ 999 DPB_a075_rotorSinOutOfRangeHigh "DPB ECU: a075 rotor sin out of range high";
CM_ SG_ 999 DPB_a076_rotorSinOutOfRangeLow "DPB ECU: a076 rotor sin out of range low";
CM_ SG_ 999 DPB_a077_tempSens1ShortToSupply "DPB ECU: a077 temp sens1 short to supply";
CM_ SG_ 999 DPB_a078_tempSens1ShortToGround "DPB ECU: a078 temp sens1 short to ground";
CM_ SG_ 999 DPB_a079_tempSens2ShortToSupply "DPB ECU: a079 temp sens2 short to supply";
CM_ SG_ 999 DPB_a080_tempSens2ShortToGround "DPB ECU: a080 temp sens2 short to ground";
CM_ SG_ 999 DPB_a081_tempSensImplausVoltage "DPB ECU: a081 temp sens implaus voltage";
CM_ SG_ 999 DPB_a082_chargePumpFault "DPB ECU: a082 charge pump fault";
CM_ SG_ 999 DPB_a083_chargePumpUndervoltage "DPB ECU: a083 charge pump undervoltage";
CM_ SG_ 999 DPB_a084_RBCPUException "DPB ECU: a084 RBCPU exception";
CM_ SG_ 999 DPB_a085_infoFailureWrongCUBASHa "DPB ECU: a085 info failure wrong CUBAS handling detected";
CM_ SG_ 999 DPB_a086_diagHydProtectionPressF "DPB ECU: a086 diag hyd protection press fault";
CM_ SG_ 999 DPB_a087_diagHydProtectionVlvFau "DPB ECU: a087 diag hyd protection vlv fault";
CM_ SG_ 999 DPB_a088_DMATransferError "DPB ECU: a088 DMA transfer error";
CM_ SG_ 999 DPB_a089_ecuBandgap "DPB ECU: a089 ecu bandgap";
CM_ SG_ 999 DPB_a090_flashFault "DPB ECU: a090 flash fault";
CM_ SG_ 999 DPB_a091_MRGPathTestFault "DPB ECU: a091 MRG path test fault";
CM_ SG_ 999 DPB_a092_decoupleBitTestFault "DPB ECU: a092 decouple bit test fault";
CM_ SG_ 999 DPB_a093_ecuBistFaultCtrFault "DPB ECU: a093 ecu bist fault ctr fault";
CM_ SG_ 999 DPB_a094_ecuClockTestFault "DPB ECU: a094 ecu clock test fault";
CM_ SG_ 999 DPB_a095_ecuEnableElHighFault "DPB ECU: a095 ecu enable el high fault";
CM_ SG_ 999 DPB_a096_ecuEnableElLowFault "DPB ECU: a096 ecu enable el low fault";
CM_ SG_ 999 DPB_a097_ecuEnableHyHighFault "DPB ECU: a097 ecu enable hy high fault";
CM_ SG_ 999 DPB_a098_ecuEnableHyLowFault "DPB ECU: a098 ecu enable hy low fault";
CM_ SG_ 999 DPB_a099_ecuEnContinuousError "DPB ECU: a099 ecu en continuous error";
CM_ SG_ 999 DPB_a100_ecuErrpinCounterFault "DPB ECU: a100 ecu errpin counter fault";
CM_ SG_ 999 DPB_a101_ecuFastWdTestFault "DPB ECU: a101 ecu fast wd test fault";
CM_ SG_ 999 DPB_a102_ecuVrOnWhileWdTimeout "DPB ECU: a102 ecu vr on while wd timeout";
CM_ SG_ 999 DPB_a103_ecuVrViaSpiFails "DPB ECU: a103 ecu vr via spi fails";
CM_ SG_ 999 DPB_a104_ecuWdStartuptestFault "DPB ECU: a104 ecu wd startuptest fault";
CM_ SG_ 999 DPB_a105_ecuWdSContinuousError "DPB ECU: a105 ecu wd s continuous error";
CM_ SG_ 999 DPB_a106_ecuBistCmdTestFault "DPB ECU: a106 ecu bist cmd test fault";
CM_ SG_ 999 DPB_a107_vrOnFails "DPB ECU: a107 vr on fails";
CM_ SG_ 999 DPB_a108_GTMRefFrequencyError "DPB ECU: a108 GTM ref frequency error";
CM_ SG_ 999 DPB_a109_GTMTbuMonError "DPB ECU: a109 GTM tbu mon error";
CM_ SG_ 999 DPB_a110_HWBISTError "DPB ECU: a110 HWBIST error";
CM_ SG_ 999 DPB_a111_hydraulicHardUndervolta "DPB ECU: a111 hydraulic hard undervoltage";
CM_ SG_ 999 DPB_a112_hydraulicUndervoltage "DPB ECU: a112 hydraulic undervoltage";
CM_ SG_ 999 DPB_a113_LiPS1SentLineHigh "DPB ECU: a113 li PS1 sent line high";
CM_ SG_ 999 DPB_a114_LiPS1SentLineLow "DPB ECU: a114 li PS1 sent line low";
CM_ SG_ 999 DPB_a115_LiPS1SentSensor "DPB ECU: a115 li PS1 sent sensor";
CM_ SG_ 999 DPB_a116_LiPS1SentTransmission "DPB ECU: a116 li PS1 sent transmission";
CM_ SG_ 999 DPB_a117_LiPS2PwmLineHigh "DPB ECU: a117 li PS2 pwm line high";
CM_ SG_ 999 DPB_a118_LiPS2PwmLineLow "DPB ECU: a118 li PS2 pwm line low";
CM_ SG_ 999 DPB_a119_LiPS2PwmTransmission "DPB ECU: a119 li PS2 pwm transmission";
CM_ SG_ 999 DPB_a120_LiPSOutOfRangeHigh "DPB ECU: a120 li PS out of range high";
CM_ SG_ 999 DPB_a121_LiPSOutOfRangeLow "DPB ECU: a121 li PS out of range low";
CM_ SG_ 999 DPB_a122_micAsicClkInError "DPB ECU: a122 mic asic clk in error";
CM_ SG_ 999 DPB_a123_micAsicInitTestError "DPB ECU: a123 mic asic init test error";
CM_ SG_ 999 DPB_a124_asicOscillatorError "DPB ECU: a124 asic oscillator error";
CM_ SG_ 999 DPB_a125_B6AsicFault "DPB ECU: a125 B6 asic fault";
CM_ SG_ 999 DPB_a126_MICB6TransferError "DPB ECU: a126 MICB6 transfer error";
CM_ SG_ 999 DPB_a127_hydraulicAsicShortCircu "DPB ECU: a127 hydraulic asic short circuit";
CM_ SG_ 999 DPB_a128_micSpiTransferError "DPB ECU: a128 mic spi transfer error";
CM_ SG_ 999 DPB_a129_AsicTrimmingNotComplete "DPB ECU: a129 asic trimming not completed";
CM_ SG_ 999 DPB_a130_AsicMalfunctionDetected "DPB ECU: a130 asic malfunction detected";
CM_ SG_ 999 DPB_a131_ASICOvercurrentOnGPIO25 "DPB ECU: a131 ASIC overcurrent on GPIO250 1";
CM_ SG_ 999 DPB_a132_ASICOvercurrentOnGPIO25 "DPB ECU: a132 ASIC overcurrent on GPIO250 2";
CM_ SG_ 999 DPB_a133_ASICOvercurrentOnGPIO50 "DPB ECU: a133 ASIC overcurrent on GPIO50 1";
CM_ SG_ 999 DPB_a134_ASICOvercurrentOnGPIO50 "DPB ECU: a134 ASIC overcurrent on GPIO50 2";
CM_ SG_ 999 DPB_a135_ASICOvercurrentOnGPIO50 "DPB ECU: a135 ASIC overcurrent on GPIO50 3";
CM_ SG_ 999 DPB_a136_ASICOvercurrentOnGPIO50 "DPB ECU: a136 ASIC overcurrent on GPIO50 4";
CM_ SG_ 999 DPB_a137_ASICOvercurrentOnWRHS "DPB ECU: a137 ASIC overcurrent on WRHS";
CM_ SG_ 999 DPB_a138_DIchassisControlCounter "DPB ECU: a138 d ichassis control counter";
CM_ SG_ 999 DPB_a139_DIchassisControlChecksu "DPB ECU: a139 d ichassis control checksum";
CM_ SG_ 999 DPB_a140_DIchassisControlDLC "DPB ECU: a140 d ichassis control DLC";
CM_ SG_ 999 DPB_a141_DIchassisControlTimeout "DPB ECU: a141 d ichassis control timeout";
CM_ SG_ 999 DPB_a142_DIsystemStatusCounter "DPB ECU: a142 d isystem status counter";
CM_ SG_ 999 DPB_a143_DIsystemStatusChecksum "DPB ECU: a143 d isystem status checksum";
CM_ SG_ 999 DPB_a144_DIsystemStatusDLC "DPB ECU: a144 d isystem status DLC";
CM_ SG_ 999 DPB_a145_DIsystemStatusTimeout "DPB ECU: a145 d isystem status timeout";
CM_ SG_ 999 DPB_a146_DIFtorqueCounter "DPB ECU: a146 DI ftorque counter";
CM_ SG_ 999 DPB_a147_DIFtorqueChecksum "DPB ECU: a147 DI ftorque checksum";
CM_ SG_ 999 DPB_a148_DIFtorqueDLC "DPB ECU: a148 DI ftorque DLC";
CM_ SG_ 999 DPB_a149_DIFtorqueTimeout "DPB ECU: a149 DI ftorque timeout";
CM_ SG_ 999 DPB_a150_DIRtorqueCounter "DPB ECU: a150 DI rtorque counter";
CM_ SG_ 999 DPB_a151_DIRtorqueChecksum "DPB ECU: a151 DI rtorque checksum";
CM_ SG_ 999 DPB_a152_DIRtorqueDLC "DPB ECU: a152 DI rtorque DLC";
CM_ SG_ 999 DPB_a153_DIRtorqueTimeout "DPB ECU: a153 DI rtorque timeout";
CM_ SG_ 999 DPB_a154_EPBLstatusCounter "DPB ECU: a154 EPB lstatus counter";
CM_ SG_ 999 DPB_a155_EPBLstatusChecksum "DPB ECU: a155 EPB lstatus checksum";
CM_ SG_ 999 DPB_a156_EPBLstatusDLC "DPB ECU: a156 EPB lstatus DLC";
CM_ SG_ 999 DPB_a157_EPBLstatusTimeout "DPB ECU: a157 EPB lstatus timeout";
CM_ SG_ 999 DPB_a158_EPBRstatusCounter "DPB ECU: a158 EPB rstatus counter";
CM_ SG_ 999 DPB_a159_EPBRstatusChecksum "DPB ECU: a159 EPB rstatus checksum";
CM_ SG_ 999 DPB_a160_EPBRstatusDLC "DPB ECU: a160 EPB rstatus DLC";
CM_ SG_ 999 DPB_a161_EPBRstatusTimeout "DPB ECU: a161 EPB rstatus timeout";
CM_ SG_ 999 DPB_a162_ESP_modulator1Counter "DPB ECU: a162 ESP modulator1 counter";
CM_ SG_ 999 DPB_a163_ESP_modulator1Checksum "DPB ECU: a163 ESP modulator1 checksum";
CM_ SG_ 999 DPB_a164_ESP_modulator1DLC "DPB ECU: a164 ESP modulator1 DLC";
CM_ SG_ 999 DPB_a165_ESP_modulator1Timeout "DPB ECU: a165 ESP modulator1 timeout";
CM_ SG_ 999 DPB_a166_ESP_chassis3Counter "DPB ECU: a166 ESP chassis3 counter";
CM_ SG_ 999 DPB_a167_ESP_chassis3Checksum "DPB ECU: a167 ESP chassis3 checksum";
CM_ SG_ 999 DPB_a168_ESP_chassis3DLC "DPB ECU: a168 ESP chassis3 DLC";
CM_ SG_ 999 DPB_a169_ESP_chassis3Timeout "DPB ECU: a169 ESP chassis3 timeout";
CM_ SG_ 999 DPB_a170_ESP_modulator2Counter "DPB ECU: a170 ESP modulator2 counter";
CM_ SG_ 999 DPB_a171_ESP_modulator2Checksum "DPB ECU: a171 ESP modulator2 checksum";
CM_ SG_ 999 DPB_a172_ESP_modulator2DLC "DPB ECU: a172 ESP modulator2 DLC";
CM_ SG_ 999 DPB_a173_ESP_modulator2Timeout "DPB ECU: a173 ESP modulator2 timeout";
CM_ SG_ 999 DPB_a174_ESP_modulator3Counter "DPB ECU: a174 ESP modulator3 counter";
CM_ SG_ 999 DPB_a175_ESP_modulator3Checksum "DPB ECU: a175 ESP modulator3 checksum";
CM_ SG_ 999 DPB_a176_ESP_modulator3DLC "DPB ECU: a176 ESP modulator3 DLC";
CM_ SG_ 999 DPB_a177_ESP_modulator3Timeout "DPB ECU: a177 ESP modulator3 timeout";
CM_ SG_ 999 DPB_a178_PMstate2Counter "DPB ECU: a178 p mstate2 counter";
CM_ SG_ 999 DPB_a179_PMstate2Checksum "DPB ECU: a179 p mstate2 checksum";
CM_ SG_ 999 DPB_a180_PMstate2DLC "DPB ECU: a180 p mstate2 DLC";
CM_ SG_ 999 DPB_a181_PMstate2Timeout "DPB ECU: a181 p mstate2 timeout";
CM_ SG_ 999 DPB_a182_RCMInertial2Counter "DPB ECU: a182 RCM inertial2 counter";
CM_ SG_ 999 DPB_a183_RCMInertial2Checksum "DPB ECU: a183 RCM inertial2 checksum";
CM_ SG_ 999 DPB_a184_RCMInertial2DLC "DPB ECU: a184 RCM inertial2 DLC";
CM_ SG_ 999 DPB_a185_RCMInertial2Timeout "DPB ECU: a185 RCM inertial2 timeout";
CM_ SG_ 999 DPB_a186_LVPowerStateTimeout "DPB ECU: a186 LV power state timeout";
CM_ SG_ 999 DPB_a187_LVPowerStateChecksum "DPB ECU: a187 LV power state checksum";
CM_ SG_ 999 DPB_a188_LVPowerStateDLC "DPB ECU: a188 LV power state DLC";
CM_ SG_ 999 DPB_a189_LVPowerStateCounter "DPB ECU: a189 LV power state counter";
CM_ SG_ 999 DPB_a190_VCLEFTepbmStatusCounter "DPB ECU: a190 VCLEF tepbm status counter";
CM_ SG_ 999 DPB_a191_VCLEFTepbmStatusChecksu "DPB ECU: a191 VCLEF tepbm status checksum";
CM_ SG_ 999 DPB_a192_VCLEFTepbmStatusDLC "DPB ECU: a192 VCLEF tepbm status DLC";
CM_ SG_ 999 DPB_a193_VCLEFTepbmStatusTimeout "DPB ECU: a193 VCLEF tepbm status timeout";
CM_ SG_ 999 DPB_a194_VCRIGHTepbmStatusCounte "DPB ECU: a194 VCRIGH tepbm status counter";
CM_ SG_ 999 DPB_a195_VCRIGHTepbmStatusChecks "DPB ECU: a195 VCRIGH tepbm status checksum";
CM_ SG_ 999 DPB_a196_VCRIGHTepbmStatusDLC "DPB ECU: a196 VCRIGH tepbm status DLC";
CM_ SG_ 999 DPB_a197_VCRIGHTepbmStatusTimeou "DPB ECU: a197 VCRIGH tepbm status timeout";
CM_ SG_ 999 DPB_a198_CANOvervoltage "DPB ECU: a198 CAN overvoltage";
CM_ SG_ 999 DPB_a199_pMC1QFaulty "DPB ECU: a199 p MC1 q faulty";
CM_ SG_ 999 DPB_a200_ESPRunoutSupportNotAvai "DPB ECU: a200 ESP runout support not available";
CM_ SG_ 999 DPB_a201_vehicleSpeedQFaulty "DPB ECU: a201 vehicle speed q faulty";
CM_ SG_ 999 DPB_a202_vehicleStandstillQFault "DPB ECU: a202 vehicle standstill q faulty";
CM_ SG_ 999 DPB_a203_ABSNotAvailable "DPB ECU: a203 ABS not available";
CM_ SG_ 999 DPB_a204_CANUndervoltage "DPB ECU: a204 CAN undervoltage";
CM_ SG_ 999 DPB_a205_NvMWriteCycleExceed "DPB ECU: a205 nv m write cycle exceed";
CM_ SG_ 999 DPB_a206_OSTaskSchemeError "DPB ECU: a206 OS task scheme error";
CM_ SG_ 999 DPB_a207_hydraulicOvervoltage "DPB ECU: a207 hydraulic overvoltage";
CM_ SG_ 999 DPB_a208_pressureSensor1Short "DPB ECU: a208 pressure sensor1 short";
CM_ SG_ 999 DPB_a209_pressureSensor1High "DPB ECU: a209 pressure sensor1 high";
CM_ SG_ 999 DPB_a210_pressureSensor1Low "DPB ECU: a210 pressure sensor1 low";
CM_ SG_ 999 DPB_a211_pressureSensor1Fault "DPB ECU: a211 pressure sensor1 fault";
CM_ SG_ 999 DPB_a212_pressureSensor1Temp "DPB ECU: a212 pressure sensor1 temp";
CM_ SG_ 999 DPB_a213_pressureSensor1Fault "DPB ECU: a213 pressure sensor1 fault";
CM_ SG_ 999 DPB_a214_pressureSensor2Short "DPB ECU: a214 pressure sensor2 short";
CM_ SG_ 999 DPB_a215_pressureSensor2High "DPB ECU: a215 pressure sensor2 high";
CM_ SG_ 999 DPB_a216_pressureSensor2Low "DPB ECU: a216 pressure sensor2 low";
CM_ SG_ 999 DPB_a217_pressureSensor2Fault "DPB ECU: a217 pressure sensor2 fault";
CM_ SG_ 999 DPB_a218_pressureSensor2Temp "DPB ECU: a218 pressure sensor2 temp";
CM_ SG_ 999 DPB_a219_pressureSensor2Fault "DPB ECU: a219 pressure sensor2 fault";
CM_ SG_ 999 DPB_a220_excessiveBoostWakeupsDe "DPB ECU: a220 excessive boost wakeups detected";
CM_ SG_ 999 DPB_a221_notShutdownRight "DPB ECU: a221 not shutdown right";
CM_ SG_ 999 DPB_a222_excessiveEcuResetsDetec "DPB ECU: a222 excessive ecu resets detected";
CM_ SG_ 999 DPB_a223_RAMFault "DPB ECU: a223 RAM fault";
CM_ SG_ 999 DPB_a224_brakeBoostLost "DPB ECU: a224 brake boost lost";
CM_ SG_ 999 DPB_a225_U5VOutOfRange "DPB ECU: a225 U5 v out of range";
CM_ SG_ 999 DPB_a226_U5VTestFault "DPB ECU: a226 U5 v test fault";
CM_ SG_ 999 DPB_a227_brakeFluidLoss "DPB ECU: a227 brake fluid loss";
CM_ SG_ 999 DPB_a228_supplyASICInitFault "DPB ECU: a228 supply ASIC init fault";
CM_ SG_ 999 DPB_a229_IREFOutOfRange "DPB ECU: a229 IREF out of range";
CM_ SG_ 999 DPB_a230_OSErrorHook "DPB ECU: a230 OS error hook";
CM_ SG_ 999 DPB_a231_stackOverUnderFlow "DPB ECU: a231 stack over under flow";
CM_ SG_ 999 DPB_a232_systemErrorHook "DPB ECU: a232 system error hook";
CM_ SG_ 999 DPB_a233_systemTaskJitter "DPB ECU: a233 system task jitter";
CM_ SG_ 999 DPB_a234_systemTaskOverRun "DPB ECU: a234 system task over run";
CM_ SG_ 999 DPB_a235_UB6PlausiMonFault "DPB ECU: a235 UB6 plausi mon fault";
CM_ SG_ 999 DPB_a236_UB6SupplyPathFault "DPB ECU: a236 UB6 supply path fault";
CM_ SG_ 999 DPB_a237_uCVoltageDividerDrift "DPB ECU: a237 u c voltage divider drift";
CM_ SG_ 999 DPB_a238_microRegisterFault "DPB ECU: a238 micro register fault";
CM_ SG_ 999 DPB_a239_microSafetyFault "DPB ECU: a239 micro safety fault";
CM_ SG_ 999 DPB_a240_microSafetyLogicFault "DPB ECU: a240 micro safety logic fault";
CM_ SG_ 999 DPB_a241_uCSafetyNotification "DPB ECU: a241 u c safety notification";
CM_ SG_ 999 DPB_a242_uCSafetyNotificationGRA "DPB ECU: a242 u c safety notification GRAM";
CM_ SG_ 999 DPB_a243_microSupplyError "DPB ECU: a243 micro supply error";
CM_ SG_ 999 DPB_a244_valvesGenericFault "DPB ECU: a244 valves generic fault";
CM_ SG_ 999 DPB_a245_valveMV0Fault "DPB ECU: a245 valve MV0 fault";
CM_ SG_ 999 DPB_a246_valveMV5Fault "DPB ECU: a246 valve MV5 fault";
CM_ SG_ 999 DPB_a247_valveMV6Fault "DPB ECU: a247 valve MV6 fault";
CM_ SG_ 999 DPB_a248_valveMV61Fault "DPB ECU: a248 valve MV61 fault";
CM_ SG_ 999 DPB_a249_valveMV62Fault "DPB ECU: a249 valve MV62 fault";
CM_ SG_ 999 DPB_a250_valveMV7Fault "DPB ECU: a250 valve MV7 fault";
CM_ SG_ 999 DPB_a251_valveMV8Fault "DPB ECU: a251 valve MV8 fault";
CM_ SG_ 999 DPB_a252_valveMV81Fault "DPB ECU: a252 valve MV81 fault";
CM_ SG_ 999 DPB_a253_valveMV82Fault "DPB ECU: a253 valve MV82 fault";
CM_ SG_ 999 DPB_a254_valveMV9Fault "DPB ECU: a254 valve MV9 fault";
CM_ SG_ 999 DPB_a255_valveRelayShort "DPB ECU: a255 valve relay short";
CM_ SG_ 999 DPB_a256_valveRelayActuationFaul "DPB ECU: a256 valve relay actuation fault";
CM_ SG_ 999 DPB_a257_valveRelayOnContinuous "DPB ECU: a257 valve relay on continuous";
CM_ SG_ 999 DPB_a258_valveRelayOffContinuous "DPB ECU: a258 valve relay off continuous";
CM_ SG_ 999 DPB_a259_valveRelayTestUndervolt "DPB ECU: a259 valve relay test undervoltage";
CM_ SG_ 999 DPB_a260_valveRelaySafetySwitchF "DPB ECU: a260 valve relay safety switch fault";
CM_ SG_ 999 DPB_a261_WdhAsicWdCmdMissing "DPB ECU: a261 wdh asic wd cmd missing";
CM_ SG_ 999 DPB_a262_WdhAsicWdErrorCntLimit "DPB ECU: a262 wdh asic wd error cnt limit";
CM_ SG_ 999 DPB_a263_WdhAsicWdErrorCntStuck "DPB ECU: a263 wdh asic wd error cnt stuck";
CM_ SG_ 999 DPB_a264_WdhSwBistConCnt "DPB ECU: a264 wdh sw bist con cnt";
CM_ SG_ 999 DPB_a265_WdhTaskMonConCnt "DPB ECU: a265 wdh task mon con cnt";
CM_ SG_ 999 DPB_a266_RPSNvMReadFault "DPB ECU: a266 RPS nv m read fault";
CM_ SG_ 999 DPB_a267_RpsAngleImplausible "DPB ECU: a267 rps angle implausible";
CM_ SG_ 999 DPB_a268_RPSVectorOscillating "DPB ECU: a268 RPS vector oscillating";
CM_ SG_ 999 DPB_a269_RPSVectorRangeHigh "DPB ECU: a269 RPS vector range high";
CM_ SG_ 999 DPB_a270_RPSVectorRangeLow "DPB ECU: a270 RPS vector range low";
CM_ SG_ 999 DPB_a271_RPSWrongCalibData "DPB ECU: a271 RPS wrong calib data";
CM_ SG_ 999 DPB_a272_runtimeAssertionFault "DPB ECU: a272 runtime assertion fault";
CM_ SG_ 999 DPB_a273_SMMOneRequestsInit "DPB ECU: a273 SMM one requests init";
CM_ SG_ 999 DPB_a274_AswSystemTimeOut "DPB ECU: a274 asw system time out";
CM_ SG_ 999 DPB_a275_Ps1Ps2PlausibilityFault "DPB ECU: a275 ps1 ps2 plausibility fault";
CM_ SG_ 999 DPB_a276_VCFRONTsensorsCounter "DPB ECU: a276 VCFRON tsensors counter";
CM_ SG_ 999 DPB_a277_VCFRONTsensorsChecksum "DPB ECU: a277 VCFRON tsensors checksum";
CM_ SG_ 999 DPB_a278_VCFRONTsensorsDLC "DPB ECU: a278 VCFRON tsensors DLC";
CM_ SG_ 999 DPB_a279_VCFRONTsensorsTimeout "DPB ECU: a279 VCFRON tsensors timeout";
CM_ SG_ 999 DPB_a280_LowBrakeFluid "DPB ECU: a280 low brake fluid";
CM_ SG_ 999 DPB_a281_brakeFluidOORHigh "DPB ECU: a281 brake fluid OOR high";
CM_ SG_ 999 DPB_a282_DIbrakeCommandCounter "DPB ECU: a282 d ibrake command counter";
CM_ SG_ 999 DPB_a283_DIbrakeCommandChecksum "DPB ECU: a283 d ibrake command checksum";
CM_ SG_ 999 DPB_a284_DIbrakeCommandDLC "DPB ECU: a284 d ibrake command DLC";
CM_ SG_ 999 DPB_a285_DIbrakeCommandTimeout "DPB ECU: a285 d ibrake command timeout";
CM_ SG_ 999 DPB_a286_ebrCmdStateInvalid "DPB ECU: a286 ebr cmd state invalid";
CM_ SG_ 999 DPB_a287_brakeCmdStateInvalid "DPB ECU: a287 brake cmd state invalid";
CM_ SG_ 999 DPB_a288_PlantDegradedSW "DPB ECU: a288 plant degraded SW";
CM_ SG_ 999 DPB_a289_evacFillNotComplete "DPB ECU: a289 evac fill not complete";
CM_ SG_ 999 DPB_a290_securityInfo "DPB ECU: a290 security info";
CM_ SG_ 999 DPB_a291_extDBRRequestTooLow "DPB ECU: a291 ext DBR request too low";
CM_ SG_ 999 DPB_a292_CBDS_fillBufferThreshol "DPB ECU: a292 CBDS fill buffer threshold";
CM_ SG_ 999 DPB_a293_CBDS_fmeInternalEvent "DPB ECU: a293 CBDS fme internal event";
CM_ SG_ 999 DPB_a294_hbaNormalModeActive "DPB ECU: a294 hba normal mode active";
CM_ SG_ 999 DPB_a295_hbaTrackModeActive "DPB ECU: a295 hba track mode active";
CM_ SG_ 999 DPB_a296_StatInvalid_DI_FullSNA "DPB ECU: a296 stat invalid DI full SNA";
CM_ SG_ 999 DPB_a297_undefinedAlertDetected "DPB ECU: a297 undefined alert detected";
CM_ SG_ 999 DPB_a298_runningPlungerCircuitTe "DPB ECU: a298 running plunger circuit test";
CM_ SG_ 999 DPB_a299_PM_locStateCounter "DPB ECU: a299 PM loc state counter";
CM_ SG_ 999 DPB_a300_PM_locStateChecksum "DPB ECU: a300 PM loc state checksum";
CM_ SG_ 999 DPB_a301_PM_locStateDLC "DPB ECU: a301 PM loc state DLC";
CM_ SG_ 999 DPB_a302_PM_locStateTimeout "DPB ECU: a302 PM loc state timeout";
CM_ SG_ 999 DPB_a303_actuatingDIFullTorqueCm "DPB ECU: a303 actuating DI full torque cmd";
CM_ SG_ 999 DPB_a304_actuatingDITorqueCmd "DPB ECU: a304 actuating DI torque cmd";
CM_ SG_ 999 DPB_a305_DIbrakeTorqueCommandAnd "DPB ECU: a305 d ibrake torque command and flag mismatch";
CM_ SG_ 999 DPB_a306_actuatorFallbackBasicMa "DPB ECU: a306 actuator fallback basic map";
CM_ SG_ 999 DPB_a307_actuatorDegradedMap "DPB ECU: a307 actuator degraded map";
CM_ SG_ 999 DPB_a308_backupMode "DPB ECU: a308 backup mode";
CM_ SG_ 999 DPB_a309_DIFAxleTorqueInvalid "DPB ECU: a309 DIF axle torque invalid";
CM_ SG_ 999 DPB_a310_DIRAxleTorqueInvalid "DPB ECU: a310 DIR axle torque invalid";
CM_ SG_ 999 DPB_a311_postrunDurationTooLong "DPB ECU: a311 postrun duration too long";
CM_ SG_ 999 DPB_a312_continuouslyActivatedVa "DPB ECU: a312 continuously activated valves off";
CM_ SG_ 999 DPB_a313_qualifiedBrakeEventDete "DPB ECU: a313 qualified brake event detected";
CM_ SG_ 999 DPB_a314_runningCyclicVolumeChec "DPB ECU: a314 running cyclic volume check";
CM_ SG_ 999 DPB_a315_runningLeakageAndAirMon "DPB ECU: a315 running leakage and air monitoring";
CM_ SG_ 999 DPB_a316_lowBrakeFluidDetectedOn "DPB ECU: a316 low brake fluid detected on hill slope";
CM_ SG_ 999 DPB_a317_DASredundantBrakingCont "DPB ECU: a317 DA sredundant braking control party checksum";
CM_ SG_ 999 DPB_a318_DASredundantBrakingCont "DPB ECU: a318 DA sredundant braking control party counter";
CM_ SG_ 999 DPB_a319_DASredundantBrakingCont "DPB ECU: a319 DA sredundant braking control party DLC";
CM_ SG_ 999 DPB_a320_DASredundantBrakingCont "DPB ECU: a320 DA sredundant braking control party timeout";
CM_ SG_ 999 DPB_a321_DASredundantBrakingCont "DPB ECU: a321 DA sredundant braking control chassis checksum";
CM_ SG_ 999 DPB_a322_DASredundantBrakingCont "DPB ECU: a322 DA sredundant braking control chassis counter";
CM_ SG_ 999 DPB_a323_DASredundantBrakingCont "DPB ECU: a323 DA sredundant braking control chassis DLC";
CM_ SG_ 999 DPB_a324_DASredundantBrakingCont "DPB ECU: a324 DA sredundant braking control chassis timeout";
CM_ SG_ 999 DPB_a325_DIlocStatus2Checksum "DPB ECU: a325 d iloc status2 checksum";
CM_ SG_ 999 DPB_a326_DIlocStatus2Counter "DPB ECU: a326 d iloc status2 counter";
CM_ SG_ 999 DPB_a327_DIlocStatus2DLC "DPB ECU: a327 d iloc status2 DLC";
CM_ SG_ 999 DPB_a328_DIlocStatus2Timeout "DPB ECU: a328 d iloc status2 timeout";
CM_ SG_ 999 DPB_a329_standaloneEBRActive "DPB ECU: a329 standalone EBR active";
CM_ SG_ 999 DPB_a330_EMCMain11Checksum "DPB ECU: a330 EMC main11 checksum";
CM_ SG_ 999 DPB_a331_EMCMain11Counter "DPB ECU: a331 EMC main11 counter";
CM_ SG_ 999 DPB_a332_EMCMain11DLC "DPB ECU: a332 EMC main11 DLC";
CM_ SG_ 999 DPB_a333_EMCMain11Timeout "DPB ECU: a333 EMC main11 timeout";
CM_ SG_ 999 DPB_a334_EMCMain21Checksum "DPB ECU: a334 EMC main21 checksum";
CM_ SG_ 999 DPB_a335_EMCMain21Counter "DPB ECU: a335 EMC main21 counter";
CM_ SG_ 999 DPB_a336_EMCMain21DLC "DPB ECU: a336 EMC main21 DLC";
CM_ SG_ 999 DPB_a337_EMCMain21Timeout "DPB ECU: a337 EMC main21 timeout";
CM_ BO_ 1426 "Electric power steering (primary) message: alert log";
CM_ SG_ 1426 EPAS3P_alertID "Electric power steering (primary): alert ID";
CM_ SG_ 1426 EPAS3P_alertState "Electric power steering (primary): alert state";
CM_ SG_ 1426 EPAS3P_a147_transitionReason "Electric power steering (primary): a147 transition reason";
CM_ SG_ 1426 EPAS3P_a149_pcbTemp "Electric power steering (primary): a149 pcb temp";
CM_ SG_ 1426 EPAS3P_a150_pcbTemp "Electric power steering (primary): a150 pcb temp";
CM_ SG_ 1426 EPAS3P_a150_phaUMainPathCalcDiff "Electric power steering (primary): a150 pha u main path calc diff";
CM_ SG_ 1426 EPAS3P_a150_phaVMainPathCalcDiff "Electric power steering (primary): a150 pha v main path calc diff";
CM_ SG_ 1426 EPAS3P_a150_otherECUAssistStatus "Electric power steering (primary): a150 other ECU assist status flag";
CM_ SG_ 1426 EPAS3P_a155_vehicleSpeed "Electric power steering (primary): a155 vehicle speed";
CM_ SG_ 1426 EPAS3P_a156_vehicleSpeed "Electric power steering (primary): a156 vehicle speed";
CM_ SG_ 1426 EPAS3P_a160_currentSensorStatus "Electric power steering (primary): a160 current sensor status";
CM_ SG_ 1426 EPAS3P_a160_gateDriverStatus "Electric power steering (primary): a160 gate driver status";
CM_ SG_ 1426 EPAS3P_a160_highSideDisconnectFe "Electric power steering (primary): a160 high side disconnect fet status";
CM_ SG_ 1426 EPAS3P_a160_phaseDisconnectFetSt "Electric power steering (primary): a160 phase disconnect fet status";
CM_ SG_ 1426 EPAS3P_a160_inverterFetStatus "Electric power steering (primary): a160 inverter fet status";
CM_ SG_ 1426 EPAS3P_a160_hsdFetFailShortTest "Electric power steering (primary): a160 hsd fet fail short test";
CM_ SG_ 1426 EPAS3P_a160_phaDisconnFailOpenTe "Electric power steering (primary): a160 pha disconn fail open test";
CM_ SG_ 1426 EPAS3P_a160_phaDisconnFailShortT "Electric power steering (primary): a160 pha disconn fail short test";
CM_ SG_ 1426 EPAS3P_a160_invFetInitTest "Electric power steering (primary): a160 inv fet init test";
CM_ SG_ 1426 EPAS3P_a160_gateDrvrInitTest "Electric power steering (primary): a160 gate drvr init test";
CM_ SG_ 1426 EPAS3P_a160_latentFaultTestTimeo "Electric power steering (primary): a160 latent fault test timeout";
CM_ SG_ 1426 EPAS3P_a161_pcoMinPhaseBCurrent "Electric power steering (primary): a161 pco min phase b current";
CM_ SG_ 1426 EPAS3P_a161_pcoMaxPhaseBCurrent "Electric power steering (primary): a161 pco max phase b current";
CM_ SG_ 1426 EPAS3P_a161_pcoMinPhaseACurrent "Electric power steering (primary): a161 pco min phase a current";
CM_ SG_ 1426 EPAS3P_a161_pcoMaxPhaseACurrent "Electric power steering (primary): a161 pco max phase a current";
CM_ SG_ 1426 EPAS3P_a162_vBridgeClosed "Electric power steering (primary): a162 v bridge closed";
CM_ SG_ 1426 EPAS3P_a162_vBridgeOpen "Electric power steering (primary): a162 v bridge open";
CM_ SG_ 1426 EPAS3P_a163_gateDrvrStatusReg "Electric power steering (primary): a163 gate drvr status reg";
CM_ SG_ 1426 EPAS3P_a163_gateDrvrDiag2Reg "Electric power steering (primary): a163 gate drvr diag2 reg";
CM_ SG_ 1426 EPAS3P_a163_gateDrvrDiag1Reg "Electric power steering (primary): a163 gate drvr diag1 reg";
CM_ SG_ 1426 EPAS3P_a163_gateDrvrDiag0Reg "Electric power steering (primary): a163 gate drvr diag0 reg";
CM_ SG_ 1426 EPAS3P_a163_diagStatus "Electric power steering (primary): a163 diag status";
CM_ SG_ 1426 EPAS3P_a163_powerStatus "Electric power steering (primary): a163 power status";
CM_ SG_ 1426 EPAS3P_a164_dcsRegister0x19 "Electric power steering (primary): a164 dcs register0x19";
CM_ SG_ 1426 EPAS3P_a164_currentSensorRailed "Electric power steering (primary): a164 current sensor railed";
CM_ BO_ 2035 "Electric power steering (primary) message: alert matrix";
CM_ SG_ 2035 EPAS3P_matrixIndex "Electric power steering (primary): matrix index";
CM_ SG_ 2035 EPAS3P_a001_sent1Mia "Electric power steering (primary): a001 sent1 mia";
CM_ SG_ 2035 EPAS3P_a002_sent1Error "Electric power steering (primary): a002 sent1 error";
CM_ SG_ 2035 EPAS3P_a003_trqSens1Supply "Electric power steering (primary): a003 trq sens1 supply";
CM_ SG_ 2035 EPAS3P_a004_trqSens1Eeprom "Electric power steering (primary): a004 trq sens1 eeprom";
CM_ SG_ 2035 EPAS3P_a005_sent2Mia "Electric power steering (primary): a005 sent2 mia";
CM_ SG_ 2035 EPAS3P_a006_sent2Error "Electric power steering (primary): a006 sent2 error";
CM_ SG_ 2035 EPAS3P_a007_trqSens2Supply "Electric power steering (primary): a007 trq sens2 supply";
CM_ SG_ 2035 EPAS3P_a008_trqSens2Eeprom "Electric power steering (primary): a008 trq sens2 eeprom";
CM_ SG_ 2035 EPAS3P_a009_sentDiff "Electric power steering (primary): a009 sent diff";
CM_ SG_ 2035 EPAS3P_a010_trqSensCalError "Electric power steering (primary): a010 trq sens cal error";
CM_ SG_ 2035 EPAS3P_a011_currentSensError "Electric power steering (primary): a011 current sens error";
CM_ SG_ 2035 EPAS3P_a012_currentSensCalError "Electric power steering (primary): a012 current sens cal error";
CM_ SG_ 2035 EPAS3P_a013_gateDriveError "Electric power steering (primary): a013 gate drive error";
CM_ SG_ 2035 EPAS3P_a014_gateDriveTxError "Electric power steering (primary): a014 gate drive tx error";
CM_ SG_ 2035 EPAS3P_a015_gateDriveEeprom "Electric power steering (primary): a015 gate drive eeprom";
CM_ SG_ 2035 EPAS3P_a016_phaseUhighUv "Electric power steering (primary): a016 phase uhigh uv";
CM_ SG_ 2035 EPAS3P_a017_phaseUlowUv "Electric power steering (primary): a017 phase ulow uv";
CM_ SG_ 2035 EPAS3P_a018_phaseVhighUv "Electric power steering (primary): a018 phase vhigh uv";
CM_ SG_ 2035 EPAS3P_a019_phaseVlowUv "Electric power steering (primary): a019 phase vlow uv";
CM_ SG_ 2035 EPAS3P_a020_phaseWhighUv "Electric power steering (primary): a020 phase whigh uv";
CM_ SG_ 2035 EPAS3P_a021_phaseWlowUv "Electric power steering (primary): a021 phase wlow uv";
CM_ SG_ 2035 EPAS3P_a022_phaseUhighOv "Electric power steering (primary): a022 phase uhigh ov";
CM_ SG_ 2035 EPAS3P_a023_phaseUlowOv "Electric power steering (primary): a023 phase ulow ov";
CM_ SG_ 2035 EPAS3P_a024_phaseVhighOv "Electric power steering (primary): a024 phase vhigh ov";
CM_ SG_ 2035 EPAS3P_a025_phaseVlowOv "Electric power steering (primary): a025 phase vlow ov";
CM_ SG_ 2035 EPAS3P_a026_phaseWhighOv "Electric power steering (primary): a026 phase whigh ov";
CM_ SG_ 2035 EPAS3P_a027_phaseWlowOv "Electric power steering (primary): a027 phase wlow ov";
CM_ SG_ 2035 EPAS3P_a028_phaseUbootUv "Electric power steering (primary): a028 phase uboot uv";
CM_ SG_ 2035 EPAS3P_a029_phaseVbootUv "Electric power steering (primary): a029 phase vboot uv";
CM_ SG_ 2035 EPAS3P_a030_phaseWbootUv "Electric power steering (primary): a030 phase wboot uv";
CM_ SG_ 2035 EPAS3P_a031_abnormalShutdown "Electric power steering (primary): a031 abnormal shutdown";
CM_ SG_ 2035 EPAS3P_a032_vRegOutputUv "Electric power steering (primary): a032 v reg output uv";
CM_ SG_ 2035 EPAS3P_a033_vRegOutputOv "Electric power steering (primary): a033 v reg output ov";
CM_ SG_ 2035 EPAS3P_a034_vRegError "Electric power steering (primary): a034 v reg error";
CM_ SG_ 2035 EPAS3P_a035_vbbSupplyUv "Electric power steering (primary): a035 vbb supply uv";
CM_ SG_ 2035 EPAS3P_a036_vbbSupplyOv "Electric power steering (primary): a036 vbb supply ov";
CM_ SG_ 2035 EPAS3P_a037_motPos1ParityError "Electric power steering (primary): a037 mot pos1 parity error";
CM_ SG_ 2035 EPAS3P_a038_motPos1Uv "Electric power steering (primary): a038 mot pos1 uv";
CM_ SG_ 2035 EPAS3P_a039_motPos1MagnetMia "Electric power steering (primary): a039 mot pos1 magnet mia";
CM_ SG_ 2035 EPAS3P_a040_motPos1LogicError "Electric power steering (primary): a040 mot pos1 logic error";
CM_ SG_ 2035 EPAS3P_a041_motPos1tempError "Electric power steering (primary): a041 mot pos1temp error";
CM_ SG_ 2035 EPAS3P_a042_motPos2ParityError "Electric power steering (primary): a042 mot pos2 parity error";
CM_ SG_ 2035 EPAS3P_a043_motPos2Uv "Electric power steering (primary): a043 mot pos2 uv";
CM_ SG_ 2035 EPAS3P_a044_motPos2MagnetMia "Electric power steering (primary): a044 mot pos2 magnet mia";
CM_ SG_ 2035 EPAS3P_a045_motPos2LogicError "Electric power steering (primary): a045 mot pos2 logic error";
CM_ SG_ 2035 EPAS3P_a046_motPos2tempError "Electric power steering (primary): a046 mot pos2temp error";
CM_ SG_ 2035 EPAS3P_a047_motPosCorrError "Electric power steering (primary): a047 mot pos corr error";
CM_ SG_ 2035 EPAS3P_a048_motPosCalError "Electric power steering (primary): a048 mot pos cal error";
CM_ SG_ 2035 EPAS3P_a049_piCtrlError "Electric power steering (primary): a049 pi ctrl error";
CM_ SG_ 2035 EPAS3P_a050_mcuSmuError "Electric power steering (primary): a050 mcu smu error";
CM_ SG_ 2035 EPAS3P_a051_mcuSupError "Electric power steering (primary): a051 mcu sup error";
CM_ SG_ 2035 EPAS3P_a052_intWatchdogError "Electric power steering (primary): a052 int watchdog error";
CM_ SG_ 2035 EPAS3P_a053_extWatchdogError "Electric power steering (primary): a053 ext watchdog error";
CM_ SG_ 2035 EPAS3P_a054_memoryProtectError "Electric power steering (primary): a054 memory protect error";
CM_ SG_ 2035 EPAS3P_a055_floatPointError "Electric power steering (primary): a055 float point error";
CM_ SG_ 2035 EPAS3P_a056_battUv "Electric power steering (primary): a056 batt uv";
CM_ SG_ 2035 EPAS3P_a057_battUvReduced "Electric power steering (primary): a057 batt uv reduced";
CM_ SG_ 2035 EPAS3P_a058_battOv "Electric power steering (primary): a058 batt ov";
CM_ SG_ 2035 EPAS3P_a059_battOvReduced "Electric power steering (primary): a059 batt ov reduced";
CM_ SG_ 2035 EPAS3P_a060_battBridgeDiff "Electric power steering (primary): a060 batt bridge diff";
CM_ SG_ 2035 EPAS3P_a061_bridgeUv "Electric power steering (primary): a061 bridge uv";
CM_ SG_ 2035 EPAS3P_a062_assistCorrError "Electric power steering (primary): a062 assist corr error";
CM_ SG_ 2035 EPAS3P_a063_dampCorrError "Electric power steering (primary): a063 damp corr error";
CM_ SG_ 2035 EPAS3P_a064_phaseCompCorrError "Electric power steering (primary): a064 phase comp corr error";
CM_ SG_ 2035 EPAS3P_a065_trqTarCorrError "Electric power steering (primary): a065 trq tar corr error";
CM_ SG_ 2035 EPAS3P_a066_returnCorrError "Electric power steering (primary): a066 return corr error";
CM_ SG_ 2035 EPAS3P_a067_yawDampCorrError "Electric power steering (primary): a067 yaw damp corr error";
CM_ SG_ 2035 EPAS3P_a068_hystCorrError "Electric power steering (primary): a068 hyst corr error";
CM_ SG_ 2035 EPAS3P_a069_eacCorrError "Electric power steering (primary): a069 eac corr error";
CM_ SG_ 2035 EPAS3P_a070_hodCorrError "Electric power steering (primary): a070 hod corr error";
CM_ SG_ 2035 EPAS3P_a071_vehSpdCorrError "Electric power steering (primary): a071 veh spd corr error";
CM_ SG_ 2035 EPAS3P_a072_motFeedFwdError "Electric power steering (primary): a072 mot feed fwd error";
CM_ SG_ 2035 EPAS3P_a073_motParEstError "Electric power steering (primary): a073 mot par est error";
CM_ SG_ 2035 EPAS3P_a074_overHeatProtect "Electric power steering (primary): a074 over heat protect";
CM_ SG_ 2035 EPAS3P_a075_fspPwrCut "Electric power steering (primary): a075 fsp pwr cut";
CM_ SG_ 2035 EPAS3P_a076_tempSensOutofRange "Electric power steering (primary): a076 temp sens outof range";
CM_ SG_ 2035 EPAS3P_a077_highSideFetError "Electric power steering (primary): a077 high side fet error";
CM_ SG_ 2035 EPAS3P_a078_phaseDisconnectError "Electric power steering (primary): a078 phase disconnect error";
CM_ SG_ 2035 EPAS3P_a079_backupCurrentPlaus "Electric power steering (primary): a079 backup current plaus";
CM_ SG_ 2035 EPAS3P_a080_ecuInitArbError "Electric power steering (primary): a080 ecu init arb error";
CM_ SG_ 2035 EPAS3P_a081_coggCompError "Electric power steering (primary): a081 cogg comp error";
CM_ SG_ 2035 EPAS3P_a082_polarityCalError "Electric power steering (primary): a082 polarity cal error";
CM_ SG_ 2035 EPAS3P_a083_crcMismatch "Electric power steering (primary): a083 crc mismatch";
CM_ SG_ 2035 EPAS3P_a084_eacCancelled "Electric power steering (primary): a084 eac cancelled";
CM_ SG_ 2035 EPAS3P_a085_canBusOff "Electric power steering (primary): a085 can bus off";
CM_ SG_ 2035 EPAS3P_a086_dasMia "Electric power steering (primary): a086 das mia";
CM_ SG_ 2035 EPAS3P_a087_dasCntError "Electric power steering (primary): a087 das cnt error";
CM_ SG_ 2035 EPAS3P_a088_dasCsError "Electric power steering (primary): a088 das cs error";
CM_ SG_ 2035 EPAS3P_a089_espWsMia "Electric power steering (primary): a089 esp ws mia";
CM_ SG_ 2035 EPAS3P_a090_espWsCntError "Electric power steering (primary): a090 esp ws cnt error";
CM_ SG_ 2035 EPAS3P_a091_espWsCsError "Electric power steering (primary): a091 esp ws cs error";
CM_ SG_ 2035 EPAS3P_a092_espWrMia "Electric power steering (primary): a092 esp wr mia";
CM_ SG_ 2035 EPAS3P_a093_espWrCntError "Electric power steering (primary): a093 esp wr cnt error";
CM_ SG_ 2035 EPAS3P_a094_espWrCsError "Electric power steering (primary): a094 esp wr cs error";
CM_ SG_ 2035 EPAS3P_a095_espWsStatus "Electric power steering (primary): a095 esp ws status";
CM_ SG_ 2035 EPAS3P_a096_rcmMia "Electric power steering (primary): a096 rcm mia";
CM_ SG_ 2035 EPAS3P_a097_rcmCntError "Electric power steering (primary): a097 rcm cnt error";
CM_ SG_ 2035 EPAS3P_a098_rcmCsError "Electric power steering (primary): a098 rcm cs error";
CM_ SG_ 2035 EPAS3P_a099_yawRateStatus "Electric power steering (primary): a099 yaw rate status";
CM_ SG_ 2035 EPAS3P_a100_diMia "Electric power steering (primary): a100 di mia";
CM_ SG_ 2035 EPAS3P_a101_diCntError "Electric power steering (primary): a101 di cnt error";
CM_ SG_ 2035 EPAS3P_a102_diCsError "Electric power steering (primary): a102 di cs error";
CM_ SG_ 2035 EPAS3P_a103_vcFrontMia "Electric power steering (primary): a103 vc front mia";
CM_ SG_ 2035 EPAS3P_a104_vcFrontCntError "Electric power steering (primary): a104 vc front cnt error";
CM_ SG_ 2035 EPAS3P_a105_vcFrontCsError "Electric power steering (primary): a105 vc front cs error";
CM_ SG_ 2035 EPAS3P_a106_vcFrontTempMia "Electric power steering (primary): a106 vc front temp mia";
CM_ SG_ 2035 EPAS3P_a107_uiTuneReqMia "Electric power steering (primary): a107 ui tune req mia";
CM_ SG_ 2035 EPAS3P_a108_uiTuneReqCntError "Electric power steering (primary): a108 ui tune req cnt error";
CM_ SG_ 2035 EPAS3P_a109_uiTuneReqCsError "Electric power steering (primary): a109 ui tune req cs error";
CM_ SG_ 2035 EPAS3P_a110_sasMia "Electric power steering (primary): a110 sas mia";
CM_ SG_ 2035 EPAS3P_a111_sasCntError "Electric power steering (primary): a111 sas cnt error";
CM_ SG_ 2035 EPAS3P_a112_sasCsError "Electric power steering (primary): a112 sas cs error";
CM_ SG_ 2035 EPAS3P_a113_sasStatusError "Electric power steering (primary): a113 sas status error";
CM_ SG_ 2035 EPAS3P_a114_gtwConfigMia "Electric power steering (primary): a114 gtw config mia";
CM_ SG_ 2035 EPAS3P_a115_ecuStatMia "Electric power steering (primary): a115 ecu stat mia";
CM_ SG_ 2035 EPAS3P_a116_ecuStatCntError "Electric power steering (primary): a116 ecu stat cnt error";
CM_ SG_ 2035 EPAS3P_a117_ecuStatCrcError "Electric power steering (primary): a117 ecu stat crc error";
CM_ SG_ 2035 EPAS3P_a118_privateBusOff "Electric power steering (primary): a118 private bus off";
CM_ SG_ 2035 EPAS3P_a119_pvtEcuStatMia "Electric power steering (primary): a119 pvt ecu stat mia";
CM_ SG_ 2035 EPAS3P_a120_pvtEcuStatCntError "Electric power steering (primary): a120 pvt ecu stat cnt error";
CM_ SG_ 2035 EPAS3P_a121_pvtEcuStatCrcError "Electric power steering (primary): a121 pvt ecu stat crc error";
CM_ SG_ 2035 EPAS3P_a122_olpActive "Electric power steering (primary): a122 olp active";
CM_ SG_ 2035 EPAS3P_a123_combEcu2StatFail "Electric power steering (primary): a123 comb ecu2 stat fail";
CM_ SG_ 2035 EPAS3P_a124_tempSensStuckInRange "Electric power steering (primary): a124 temp sens stuck in range";
CM_ SG_ 2035 EPAS3P_a125_trqSensTrimOutRange "Electric power steering (primary): a125 trq sens trim out range";
CM_ SG_ 2035 EPAS3P_a126_apsMia "Electric power steering (primary): a126 aps mia";
CM_ SG_ 2035 EPAS3P_a127_apsCntError "Electric power steering (primary): a127 aps cnt error";
CM_ SG_ 2035 EPAS3P_a128_apsCsError "Electric power steering (primary): a128 aps cs error";
CM_ SG_ 2035 EPAS3P_a129_combEcu1StatFail "Electric power steering (primary): a129 comb ecu1 stat fail";
CM_ SG_ 2035 EPAS3P_a130_sasOffsetNotCal "Electric power steering (primary): a130 sas offset not cal";
CM_ SG_ 2035 EPAS3P_a131_phaseFeedbackError "Electric power steering (primary): a131 phase feedback error";
CM_ SG_ 2035 EPAS3P_a132_motFeedFwdCounter25 "Electric power steering (primary): a132 mot feed fwd counter25";
CM_ SG_ 2035 EPAS3P_a133_motFeedFwdCounter50 "Electric power steering (primary): a133 mot feed fwd counter50";
CM_ SG_ 2035 EPAS3P_a134_motFeedFwdCounter85 "Electric power steering (primary): a134 mot feed fwd counter85";
CM_ SG_ 2035 EPAS3P_a135_piCtrlCounter25 "Electric power steering (primary): a135 pi ctrl counter25";
CM_ SG_ 2035 EPAS3P_a136_piCtrlCounter50 "Electric power steering (primary): a136 pi ctrl counter50";
CM_ SG_ 2035 EPAS3P_a137_piCtrlCounter85 "Electric power steering (primary): a137 pi ctrl counter85";
CM_ SG_ 2035 EPAS3P_a144_diSpdMia "Electric power steering (primary): a144 di spd mia";
CM_ SG_ 2035 EPAS3P_a145_diSpdCntError "Electric power steering (primary): a145 di spd cnt error";
CM_ SG_ 2035 EPAS3P_a146_diSpdCsError "Electric power steering (primary): a146 di spd cs error";
CM_ SG_ 2035 EPAS3P_a147_backupVehSpeed "Electric power steering (primary): a147 backup veh speed";
CM_ SG_ 2035 EPAS3P_a148_vMaxAssist "Electric power steering (primary): a148 v max assist";
CM_ SG_ 2035 EPAS3P_a149_currentSensPathSwitc "Electric power steering (primary): a149 current sens path switch";
CM_ SG_ 2035 EPAS3P_a150_currentSensOffsetDet "Electric power steering (primary): a150 current sens offset detect";
CM_ SG_ 2035 EPAS3P_a151_dcsCboot "Electric power steering (primary): a151 dcs cboot";
CM_ SG_ 2035 EPAS3P_a152_dcsDiagReg "Electric power steering (primary): a152 dcs diag reg";
CM_ SG_ 2035 EPAS3P_a153_dcsInitOffset "Electric power steering (primary): a153 dcs init offset";
CM_ SG_ 2035 EPAS3P_a154_assistTorqueDisabled "Electric power steering (primary): a154 assist torque disabled";
CM_ SG_ 2035 EPAS3P_a155_backupEacActive "Electric power steering (primary): a155 backup eac active";
CM_ SG_ 2035 EPAS3P_a156_angleSensorDivergenc "Electric power steering (primary): a156 angle sensor divergence";
CM_ SG_ 2035 EPAS3P_a157_pmState2Mia "Electric power steering (primary): a157 pm state2 mia";
CM_ SG_ 2035 EPAS3P_a158_pmState2CntError "Electric power steering (primary): a158 pm state2 cnt error";
CM_ SG_ 2035 EPAS3P_a159_pmState2CsError "Electric power steering (primary): a159 pm state2 cs error";
CM_ SG_ 2035 EPAS3P_a160_latentFaultTestResul "Electric power steering (primary): a160 latent fault test result";
CM_ SG_ 2035 EPAS3P_a161_initTestPhaDisconnIn "Electric power steering (primary): a161 init test pha disconn info";
CM_ SG_ 2035 EPAS3P_a162_initTestHSDFetInfo "Electric power steering (primary): a162 init test HSD fet info";
CM_ SG_ 2035 EPAS3P_a163_initTestGateDrvrInfo "Electric power steering (primary): a163 init test gate drvr info";
CM_ SG_ 2035 EPAS3P_a164_initTestDCSInfo "Electric power steering (primary): a164 init test DCS info";
CM_ SG_ 2035 EPAS3P_a165_epbStatusMia "Electric power steering (primary): a165 epb status mia";
CM_ SG_ 2035 EPAS3P_a166_epbStatusCntError "Electric power steering (primary): a166 epb status cnt error";
CM_ SG_ 2035 EPAS3P_a167_epbStatusCsError "Electric power steering (primary): a167 epb status cs error";
CM_ SG_ 2035 EPAS3P_a168_torsionBarTorqueQfDe "Electric power steering (primary): a168 torsion bar torque qf degraded";
CM_ SG_ 2035 EPAS3P_a169_difMia "Electric power steering (primary): a169 dif mia";
CM_ SG_ 2035 EPAS3P_a170_difCntError "Electric power steering (primary): a170 dif cnt error";
CM_ SG_ 2035 EPAS3P_a171_difCsError "Electric power steering (primary): a171 dif cs error";
CM_ BO_ 977 "Electric power steering (primary) message: angle calibration";
CM_ SG_ 977 EPAS3P_appliedAngleOffset "This represents the angle delta between the absolute steering angle reference and what EPAS estimates to be straight ahead. The steering angle offset can change up to 5deg at the beginning of each drive cycle.";
CM_ SG_ 977 EPAS3P_calculatedAngleOffset "Reports the calculated steering angle offset learned between the Steering Column Control Module (SCCM) and the Electronic Power Assist Steering (EPAS) steering angle.";
CM_ SG_ 977 EPAS3P_resyncStatus "Electric power steering (primary): resync status";
CM_ SG_ 977 EPAS3P_pullDriftLongTermTrq "The learned, long term pull drift or road crown compensation torque that the rack is applying to the steering wheel.";
CM_ SG_ 977 EPAS3P_pullDriftCompTrq "The current pull drift or road crown compensation torque that the rack is applying to the steering wheel.";
CM_ SG_ 977 EPAS3P_learnedSCCMOffset "Electric power steering (primary): learned SCCM offset";
CM_ BO_ 817 "Electric power steering (primary) message: info";
CM_ SG_ 817 EPAS3P_infoIndex "Electric power steering (primary): info index";
CM_ SG_ 817 EPAS3P_infoBuildType "Electric power steering (primary): info build type";
CM_ SG_ 817 EPAS3P_infoComponentID "Electric power steering (primary): info component ID";
CM_ SG_ 817 EPAS3P_infoPcbaID "Electric power steering (primary): info pcba ID";
CM_ SG_ 817 EPAS3P_infoAssemblyID "Electric power steering (primary): info assembly ID";
CM_ SG_ 817 EPAS3P_infoUsageID "Electric power steering (primary): info usage ID";
CM_ SG_ 817 EPAS3P_infoApplicationCRC "Electric power steering (primary): info application CRC";
CM_ SG_ 817 EPAS3P_infoBootUdsProtoVersion "Electric power steering (primary): info boot uds proto version";
CM_ SG_ 817 EPAS3P_infoBootloaderCRC "Electric power steering (primary): info bootloader CRC";
CM_ SG_ 817 EPAS3P_infoSubcomponent2 "Electric power steering (primary): info subcomponent2";
CM_ BO_ 883 "Electric power steering (primary) message: sys status";
CM_ SG_ 883 EPAS3P_steeringRackForce "The real time, estimated force applied by the steering rack to the tie rods; raw 1023 = signal not available (SNA)";
CM_ SG_ 883 EPAS3P_steeringFault "Electric power steering (primary): steering fault";
CM_ SG_ 883 EPAS3P_steeringReduced "Electric power steering (primary): steering reduced";
CM_ SG_ 883 EPAS3P_internalSASQF "This signal identifies the validity of the EPAS3P_internalSAS signal.";
CM_ SG_ 883 EPAS3P_currentTuneMode "Electric power steering (primary): current tune mode";
CM_ SG_ 883 EPAS3P_torsionBarTorque "The measurement of the steering wheel torque input. If the value is positive the steering wheel torque is applied in the clockwise direction; raw 4095 = signal not available (SNA)";
CM_ SG_ 883 EPAS3P_eacErrorCode "Electric power steering (primary): eac error code; raw 15 = signal not available (SNA)";
CM_ SG_ 883 EPAS3P_internalSAS "The measurement of the steering wheel angle that is calculated by electronic power steering assist steering. Clockwise positive.";
CM_ SG_ 883 EPAS3P_handsOnLevel "Electric power steering (primary): hands on level";
CM_ SG_ 883 EPAS3P_sysStatusCounter "Electric power steering (primary): sys status counter";
CM_ SG_ 883 EPAS3P_driverlessState "Electric power steering (primary): driverless state";
CM_ SG_ 883 EPAS3P_eacStatus "Electric power steering (primary): eac status";
CM_ SG_ 883 EPAS3P_sysStatusChecksum "Electric power steering (primary): sys status checksum";
CM_ BO_ 1592 "Electric power steering (primary) message: uds response CH";
CM_ SG_ 1592 EPAS3P_udsResponseDataCH "Electric power steering (primary): uds response data CH";
CM_ BO_ 1425 "Electric power steering (secondary) message: alert log";
CM_ SG_ 1425 EPAS3S_alertID "Electric power steering (secondary): alert ID";
CM_ SG_ 1425 EPAS3S_alertState "Electric power steering (secondary): alert state";
CM_ SG_ 1425 EPAS3S_a147_transitionReason "Electric power steering (secondary): a147 transition reason";
CM_ SG_ 1425 EPAS3S_a149_pcbTemp "Electric power steering (secondary): a149 pcb temp";
CM_ SG_ 1425 EPAS3S_a150_pcbTemp "Electric power steering (secondary): a150 pcb temp";
CM_ SG_ 1425 EPAS3S_a150_phaUMainPathCalcDiff "Electric power steering (secondary): a150 pha u main path calc diff";
CM_ SG_ 1425 EPAS3S_a150_phaVMainPathCalcDiff "Electric power steering (secondary): a150 pha v main path calc diff";
CM_ SG_ 1425 EPAS3S_a150_otherECUAssistStatus "Electric power steering (secondary): a150 other ECU assist status flag";
CM_ SG_ 1425 EPAS3S_a155_vehicleSpeed "Electric power steering (secondary): a155 vehicle speed";
CM_ SG_ 1425 EPAS3S_a156_vehicleSpeed "Electric power steering (secondary): a156 vehicle speed";
CM_ SG_ 1425 EPAS3S_a160_currentSensorStatus "Electric power steering (secondary): a160 current sensor status";
CM_ SG_ 1425 EPAS3S_a160_gateDriverStatus "Electric power steering (secondary): a160 gate driver status";
CM_ SG_ 1425 EPAS3S_a160_highSideDisconnectFe "Electric power steering (secondary): a160 high side disconnect fet status";
CM_ SG_ 1425 EPAS3S_a160_phaseDisconnectFetSt "Electric power steering (secondary): a160 phase disconnect fet status";
CM_ SG_ 1425 EPAS3S_a160_inverterFetStatus "Electric power steering (secondary): a160 inverter fet status";
CM_ SG_ 1425 EPAS3S_a160_hsdFetFailShortTest "Electric power steering (secondary): a160 hsd fet fail short test";
CM_ SG_ 1425 EPAS3S_a160_phaDisconnFailOpenTe "Electric power steering (secondary): a160 pha disconn fail open test";
CM_ SG_ 1425 EPAS3S_a160_phaDisconnFailShortT "Electric power steering (secondary): a160 pha disconn fail short test";
CM_ SG_ 1425 EPAS3S_a160_invFetInitTest "Electric power steering (secondary): a160 inv fet init test";
CM_ SG_ 1425 EPAS3S_a160_gateDrvrInitTest "Electric power steering (secondary): a160 gate drvr init test";
CM_ SG_ 1425 EPAS3S_a160_latentFaultTestTimeo "Electric power steering (secondary): a160 latent fault test timeout";
CM_ SG_ 1425 EPAS3S_a161_pcoMinPhaseBCurrent "Electric power steering (secondary): a161 pco min phase b current";
CM_ SG_ 1425 EPAS3S_a161_pcoMaxPhaseBCurrent "Electric power steering (secondary): a161 pco max phase b current";
CM_ SG_ 1425 EPAS3S_a161_pcoMinPhaseACurrent "Electric power steering (secondary): a161 pco min phase a current";
CM_ SG_ 1425 EPAS3S_a161_pcoMaxPhaseACurrent "Electric power steering (secondary): a161 pco max phase a current";
CM_ SG_ 1425 EPAS3S_a162_vBridgeClosed "Electric power steering (secondary): a162 v bridge closed";
CM_ SG_ 1425 EPAS3S_a162_vBridgeOpen "Electric power steering (secondary): a162 v bridge open";
CM_ SG_ 1425 EPAS3S_a163_gateDrvrStatusReg "Electric power steering (secondary): a163 gate drvr status reg";
CM_ SG_ 1425 EPAS3S_a163_gateDrvrDiag2Reg "Electric power steering (secondary): a163 gate drvr diag2 reg";
CM_ SG_ 1425 EPAS3S_a163_gateDrvrDiag1Reg "Electric power steering (secondary): a163 gate drvr diag1 reg";
CM_ SG_ 1425 EPAS3S_a163_gateDrvrDiag0Reg "Electric power steering (secondary): a163 gate drvr diag0 reg";
CM_ SG_ 1425 EPAS3S_a163_diagStatus "Electric power steering (secondary): a163 diag status";
CM_ SG_ 1425 EPAS3S_a163_powerStatus "Electric power steering (secondary): a163 power status";
CM_ SG_ 1425 EPAS3S_a164_dcsRegister0x19 "Electric power steering (secondary): a164 dcs register0x19";
CM_ SG_ 1425 EPAS3S_a164_currentSensorRailed "Electric power steering (secondary): a164 current sensor railed";
CM_ BO_ 913 "Electric power steering (secondary) message: alert matrix";
CM_ SG_ 913 EPAS3S_matrixIndex "Electric power steering (secondary): matrix index";
CM_ SG_ 913 EPAS3S_a001_sent1Mia "Electric power steering (secondary): a001 sent1 mia";
CM_ SG_ 913 EPAS3S_a002_sent1Error "Electric power steering (secondary): a002 sent1 error";
CM_ SG_ 913 EPAS3S_a003_trqSens1Supply "Electric power steering (secondary): a003 trq sens1 supply";
CM_ SG_ 913 EPAS3S_a004_trqSens1Eeprom "Electric power steering (secondary): a004 trq sens1 eeprom";
CM_ SG_ 913 EPAS3S_a005_sent2Mia "Electric power steering (secondary): a005 sent2 mia";
CM_ SG_ 913 EPAS3S_a006_sent2Error "Electric power steering (secondary): a006 sent2 error";
CM_ SG_ 913 EPAS3S_a007_trqSens2Supply "Electric power steering (secondary): a007 trq sens2 supply";
CM_ SG_ 913 EPAS3S_a008_trqSens2Eeprom "Electric power steering (secondary): a008 trq sens2 eeprom";
CM_ SG_ 913 EPAS3S_a009_sentDiff "Electric power steering (secondary): a009 sent diff";
CM_ SG_ 913 EPAS3S_a010_trqSensCalError "Electric power steering (secondary): a010 trq sens cal error";
CM_ SG_ 913 EPAS3S_a011_currentSensError "Electric power steering (secondary): a011 current sens error";
CM_ SG_ 913 EPAS3S_a012_currentSensCalError "Electric power steering (secondary): a012 current sens cal error";
CM_ SG_ 913 EPAS3S_a013_gateDriveError "Electric power steering (secondary): a013 gate drive error";
CM_ SG_ 913 EPAS3S_a014_gateDriveTxError "Electric power steering (secondary): a014 gate drive tx error";
CM_ SG_ 913 EPAS3S_a015_gateDriveEeprom "Electric power steering (secondary): a015 gate drive eeprom";
CM_ SG_ 913 EPAS3S_a016_phaseUhighUv "Electric power steering (secondary): a016 phase uhigh uv";
CM_ SG_ 913 EPAS3S_a017_phaseUlowUv "Electric power steering (secondary): a017 phase ulow uv";
CM_ SG_ 913 EPAS3S_a018_phaseVhighUv "Electric power steering (secondary): a018 phase vhigh uv";
CM_ SG_ 913 EPAS3S_a019_phaseVlowUv "Electric power steering (secondary): a019 phase vlow uv";
CM_ SG_ 913 EPAS3S_a020_phaseWhighUv "Electric power steering (secondary): a020 phase whigh uv";
CM_ SG_ 913 EPAS3S_a021_phaseWlowUv "Electric power steering (secondary): a021 phase wlow uv";
CM_ SG_ 913 EPAS3S_a022_phaseUhighOv "Electric power steering (secondary): a022 phase uhigh ov";
CM_ SG_ 913 EPAS3S_a023_phaseUlowOv "Electric power steering (secondary): a023 phase ulow ov";
CM_ SG_ 913 EPAS3S_a024_phaseVhighOv "Electric power steering (secondary): a024 phase vhigh ov";
CM_ SG_ 913 EPAS3S_a025_phaseVlowOv "Electric power steering (secondary): a025 phase vlow ov";
CM_ SG_ 913 EPAS3S_a026_phaseWhighOv "Electric power steering (secondary): a026 phase whigh ov";
CM_ SG_ 913 EPAS3S_a027_phaseWlowOv "Electric power steering (secondary): a027 phase wlow ov";
CM_ SG_ 913 EPAS3S_a028_phaseUbootUv "Electric power steering (secondary): a028 phase uboot uv";
CM_ SG_ 913 EPAS3S_a029_phaseVbootUv "Electric power steering (secondary): a029 phase vboot uv";
CM_ SG_ 913 EPAS3S_a030_phaseWbootUv "Electric power steering (secondary): a030 phase wboot uv";
CM_ SG_ 913 EPAS3S_a031_abnormalShutdown "Electric power steering (secondary): a031 abnormal shutdown";
CM_ SG_ 913 EPAS3S_a032_vRegOutputUv "Electric power steering (secondary): a032 v reg output uv";
CM_ SG_ 913 EPAS3S_a033_vRegOutputOv "Electric power steering (secondary): a033 v reg output ov";
CM_ SG_ 913 EPAS3S_a034_vRegError "Electric power steering (secondary): a034 v reg error";
CM_ SG_ 913 EPAS3S_a035_vbbSupplyUv "Electric power steering (secondary): a035 vbb supply uv";
CM_ SG_ 913 EPAS3S_a036_vbbSupplyOv "Electric power steering (secondary): a036 vbb supply ov";
CM_ SG_ 913 EPAS3S_a037_motPos1ParityError "Electric power steering (secondary): a037 mot pos1 parity error";
CM_ SG_ 913 EPAS3S_a038_motPos1Uv "Electric power steering (secondary): a038 mot pos1 uv";
CM_ SG_ 913 EPAS3S_a039_motPos1MagnetMia "Electric power steering (secondary): a039 mot pos1 magnet mia";
CM_ SG_ 913 EPAS3S_a040_motPos1LogicError "Electric power steering (secondary): a040 mot pos1 logic error";
CM_ SG_ 913 EPAS3S_a041_motPos1tempError "Electric power steering (secondary): a041 mot pos1temp error";
CM_ SG_ 913 EPAS3S_a042_motPos2ParityError "Electric power steering (secondary): a042 mot pos2 parity error";
CM_ SG_ 913 EPAS3S_a043_motPos2Uv "Electric power steering (secondary): a043 mot pos2 uv";
CM_ SG_ 913 EPAS3S_a044_motPos2MagnetMia "Electric power steering (secondary): a044 mot pos2 magnet mia";
CM_ SG_ 913 EPAS3S_a045_motPos2LogicError "Electric power steering (secondary): a045 mot pos2 logic error";
CM_ SG_ 913 EPAS3S_a046_motPos2tempError "Electric power steering (secondary): a046 mot pos2temp error";
CM_ SG_ 913 EPAS3S_a047_motPosCorrError "Electric power steering (secondary): a047 mot pos corr error";
CM_ SG_ 913 EPAS3S_a048_motPosCalError "Electric power steering (secondary): a048 mot pos cal error";
CM_ SG_ 913 EPAS3S_a049_piCtrlError "Electric power steering (secondary): a049 pi ctrl error";
CM_ SG_ 913 EPAS3S_a050_mcuSmuError "Electric power steering (secondary): a050 mcu smu error";
CM_ SG_ 913 EPAS3S_a051_mcuSupError "Electric power steering (secondary): a051 mcu sup error";
CM_ SG_ 913 EPAS3S_a052_intWatchdogError "Electric power steering (secondary): a052 int watchdog error";
CM_ SG_ 913 EPAS3S_a053_extWatchdogError "Electric power steering (secondary): a053 ext watchdog error";
CM_ SG_ 913 EPAS3S_a054_memoryProtectError "Electric power steering (secondary): a054 memory protect error";
CM_ SG_ 913 EPAS3S_a055_floatPointError "Electric power steering (secondary): a055 float point error";
CM_ SG_ 913 EPAS3S_a056_battUv "Electric power steering (secondary): a056 batt uv";
CM_ SG_ 913 EPAS3S_a057_battUvReduced "Electric power steering (secondary): a057 batt uv reduced";
CM_ SG_ 913 EPAS3S_a058_battOv "Electric power steering (secondary): a058 batt ov";
CM_ SG_ 913 EPAS3S_a059_battOvReduced "Electric power steering (secondary): a059 batt ov reduced";
CM_ SG_ 913 EPAS3S_a060_battBridgeDiff "Electric power steering (secondary): a060 batt bridge diff";
CM_ SG_ 913 EPAS3S_a061_bridgeUv "Electric power steering (secondary): a061 bridge uv";
CM_ SG_ 913 EPAS3S_a062_assistCorrError "Electric power steering (secondary): a062 assist corr error";
CM_ SG_ 913 EPAS3S_a063_dampCorrError "Electric power steering (secondary): a063 damp corr error";
CM_ SG_ 913 EPAS3S_a064_phaseCompCorrError "Electric power steering (secondary): a064 phase comp corr error";
CM_ SG_ 913 EPAS3S_a065_trqTarCorrError "Electric power steering (secondary): a065 trq tar corr error";
CM_ SG_ 913 EPAS3S_a066_returnCorrError "Electric power steering (secondary): a066 return corr error";
CM_ SG_ 913 EPAS3S_a067_yawDampCorrError "Electric power steering (secondary): a067 yaw damp corr error";
CM_ SG_ 913 EPAS3S_a068_hystCorrError "Electric power steering (secondary): a068 hyst corr error";
CM_ SG_ 913 EPAS3S_a069_eacCorrError "Electric power steering (secondary): a069 eac corr error";
CM_ SG_ 913 EPAS3S_a070_hodCorrError "Electric power steering (secondary): a070 hod corr error";
CM_ SG_ 913 EPAS3S_a071_vehSpdCorrError "Electric power steering (secondary): a071 veh spd corr error";
CM_ SG_ 913 EPAS3S_a072_motFeedFwdError "Electric power steering (secondary): a072 mot feed fwd error";
CM_ SG_ 913 EPAS3S_a073_motParEstError "Electric power steering (secondary): a073 mot par est error";
CM_ SG_ 913 EPAS3S_a074_overHeatProtect "Electric power steering (secondary): a074 over heat protect";
CM_ SG_ 913 EPAS3S_a075_fspPwrCut "Electric power steering (secondary): a075 fsp pwr cut";
CM_ SG_ 913 EPAS3S_a076_tempSensOutofRange "Electric power steering (secondary): a076 temp sens outof range";
CM_ SG_ 913 EPAS3S_a077_highSideFetError "Electric power steering (secondary): a077 high side fet error";
CM_ SG_ 913 EPAS3S_a078_phaseDisconnectError "Electric power steering (secondary): a078 phase disconnect error";
CM_ SG_ 913 EPAS3S_a079_backupCurrentPlaus "Electric power steering (secondary): a079 backup current plaus";
CM_ SG_ 913 EPAS3S_a080_ecuInitArbError "Electric power steering (secondary): a080 ecu init arb error";
CM_ SG_ 913 EPAS3S_a081_coggCompError "Electric power steering (secondary): a081 cogg comp error";
CM_ SG_ 913 EPAS3S_a082_polarityCalError "Electric power steering (secondary): a082 polarity cal error";
CM_ SG_ 913 EPAS3S_a083_crcMismatch "Electric power steering (secondary): a083 crc mismatch";
CM_ SG_ 913 EPAS3S_a084_eacCancelled "Electric power steering (secondary): a084 eac cancelled";
CM_ SG_ 913 EPAS3S_a085_canBusOff "Electric power steering (secondary): a085 can bus off";
CM_ SG_ 913 EPAS3S_a086_dasMia "Electric power steering (secondary): a086 das mia";
CM_ SG_ 913 EPAS3S_a087_dasCntError "Electric power steering (secondary): a087 das cnt error";
CM_ SG_ 913 EPAS3S_a088_dasCsError "Electric power steering (secondary): a088 das cs error";
CM_ SG_ 913 EPAS3S_a089_espWsMia "Electric power steering (secondary): a089 esp ws mia";
CM_ SG_ 913 EPAS3S_a090_espWsCntError "Electric power steering (secondary): a090 esp ws cnt error";
CM_ SG_ 913 EPAS3S_a091_espWsCsError "Electric power steering (secondary): a091 esp ws cs error";
CM_ SG_ 913 EPAS3S_a092_espWrMia "Electric power steering (secondary): a092 esp wr mia";
CM_ SG_ 913 EPAS3S_a093_espWrCntError "Electric power steering (secondary): a093 esp wr cnt error";
CM_ SG_ 913 EPAS3S_a094_espWrCsError "Electric power steering (secondary): a094 esp wr cs error";
CM_ SG_ 913 EPAS3S_a095_espWsStatus "Electric power steering (secondary): a095 esp ws status";
CM_ SG_ 913 EPAS3S_a096_rcmMia "Electric power steering (secondary): a096 rcm mia";
CM_ SG_ 913 EPAS3S_a097_rcmCntError "Electric power steering (secondary): a097 rcm cnt error";
CM_ SG_ 913 EPAS3S_a098_rcmCsError "Electric power steering (secondary): a098 rcm cs error";
CM_ SG_ 913 EPAS3S_a099_yawRateStatus "Electric power steering (secondary): a099 yaw rate status";
CM_ SG_ 913 EPAS3S_a100_diMia "Electric power steering (secondary): a100 di mia";
CM_ SG_ 913 EPAS3S_a101_diCntError "Electric power steering (secondary): a101 di cnt error";
CM_ SG_ 913 EPAS3S_a102_diCsError "Electric power steering (secondary): a102 di cs error";
CM_ SG_ 913 EPAS3S_a103_vcFrontMia "Electric power steering (secondary): a103 vc front mia";
CM_ SG_ 913 EPAS3S_a104_vcFrontCntError "Electric power steering (secondary): a104 vc front cnt error";
CM_ SG_ 913 EPAS3S_a105_vcFrontCsError "Electric power steering (secondary): a105 vc front cs error";
CM_ SG_ 913 EPAS3S_a106_vcFrontTempMia "Electric power steering (secondary): a106 vc front temp mia";
CM_ SG_ 913 EPAS3S_a107_uiTuneReqMia "Electric power steering (secondary): a107 ui tune req mia";
CM_ SG_ 913 EPAS3S_a108_uiTuneReqCntError "Electric power steering (secondary): a108 ui tune req cnt error";
CM_ SG_ 913 EPAS3S_a109_uiTuneReqCsError "Electric power steering (secondary): a109 ui tune req cs error";
CM_ SG_ 913 EPAS3S_a110_sasMia "Electric power steering (secondary): a110 sas mia";
CM_ SG_ 913 EPAS3S_a111_sasCntError "Electric power steering (secondary): a111 sas cnt error";
CM_ SG_ 913 EPAS3S_a112_sasCsError "Electric power steering (secondary): a112 sas cs error";
CM_ SG_ 913 EPAS3S_a113_sasStatusError "Electric power steering (secondary): a113 sas status error";
CM_ SG_ 913 EPAS3S_a114_gtwConfigMia "Electric power steering (secondary): a114 gtw config mia";
CM_ SG_ 913 EPAS3S_a115_ecuStatMia "Electric power steering (secondary): a115 ecu stat mia";
CM_ SG_ 913 EPAS3S_a116_ecuStatCntError "Electric power steering (secondary): a116 ecu stat cnt error";
CM_ SG_ 913 EPAS3S_a117_ecuStatCrcError "Electric power steering (secondary): a117 ecu stat crc error";
CM_ SG_ 913 EPAS3S_a118_privateBusOff "Electric power steering (secondary): a118 private bus off";
CM_ SG_ 913 EPAS3S_a119_pvtEcuStatMia "Electric power steering (secondary): a119 pvt ecu stat mia";
CM_ SG_ 913 EPAS3S_a120_pvtEcuStatCntError "Electric power steering (secondary): a120 pvt ecu stat cnt error";
CM_ SG_ 913 EPAS3S_a121_pvtEcuStatCrcError "Electric power steering (secondary): a121 pvt ecu stat crc error";
CM_ SG_ 913 EPAS3S_a122_olpActive "Electric power steering (secondary): a122 olp active";
CM_ SG_ 913 EPAS3S_a123_combEcu2StatFail "Electric power steering (secondary): a123 comb ecu2 stat fail";
CM_ SG_ 913 EPAS3S_a124_tempSensStuckInRange "Electric power steering (secondary): a124 temp sens stuck in range";
CM_ SG_ 913 EPAS3S_a125_trqSensTrimOutRange "Electric power steering (secondary): a125 trq sens trim out range";
CM_ SG_ 913 EPAS3S_a126_apsMia "Electric power steering (secondary): a126 aps mia";
CM_ SG_ 913 EPAS3S_a127_apsCntError "Electric power steering (secondary): a127 aps cnt error";
CM_ SG_ 913 EPAS3S_a128_apsCsError "Electric power steering (secondary): a128 aps cs error";
CM_ SG_ 913 EPAS3S_a129_combEcu1StatFail "Electric power steering (secondary): a129 comb ecu1 stat fail";
CM_ SG_ 913 EPAS3S_a130_sasOffsetNotCal "Electric power steering (secondary): a130 sas offset not cal";
CM_ SG_ 913 EPAS3S_a131_phaseFeedbackError "Electric power steering (secondary): a131 phase feedback error";
CM_ SG_ 913 EPAS3S_a132_motFeedFwdCounter25 "Electric power steering (secondary): a132 mot feed fwd counter25";
CM_ SG_ 913 EPAS3S_a133_motFeedFwdCounter50 "Electric power steering (secondary): a133 mot feed fwd counter50";
CM_ SG_ 913 EPAS3S_a134_motFeedFwdCounter85 "Electric power steering (secondary): a134 mot feed fwd counter85";
CM_ SG_ 913 EPAS3S_a135_piCtrlCounter25 "Electric power steering (secondary): a135 pi ctrl counter25";
CM_ SG_ 913 EPAS3S_a136_piCtrlCounter50 "Electric power steering (secondary): a136 pi ctrl counter50";
CM_ SG_ 913 EPAS3S_a137_piCtrlCounter85 "Electric power steering (secondary): a137 pi ctrl counter85";
CM_ SG_ 913 EPAS3S_a144_diSpdMia "Electric power steering (secondary): a144 di spd mia";
CM_ SG_ 913 EPAS3S_a145_diSpdCntError "Electric power steering (secondary): a145 di spd cnt error";
CM_ SG_ 913 EPAS3S_a146_diSpdCsError "Electric power steering (secondary): a146 di spd cs error";
CM_ SG_ 913 EPAS3S_a147_backupVehSpeed "Electric power steering (secondary): a147 backup veh speed";
CM_ SG_ 913 EPAS3S_a148_vMaxAssist "Electric power steering (secondary): a148 v max assist";
CM_ SG_ 913 EPAS3S_a149_currentSensPathSwitc "Electric power steering (secondary): a149 current sens path switch";
CM_ SG_ 913 EPAS3S_a150_currentSensOffsetDet "Electric power steering (secondary): a150 current sens offset detect";
CM_ SG_ 913 EPAS3S_a151_dcsCboot "Electric power steering (secondary): a151 dcs cboot";
CM_ SG_ 913 EPAS3S_a152_dcsDiagReg "Electric power steering (secondary): a152 dcs diag reg";
CM_ SG_ 913 EPAS3S_a153_dcsInitOffset "Electric power steering (secondary): a153 dcs init offset";
CM_ SG_ 913 EPAS3S_a154_assistTorqueDisabled "Electric power steering (secondary): a154 assist torque disabled";
CM_ SG_ 913 EPAS3S_a155_backupEacActive "Electric power steering (secondary): a155 backup eac active";
CM_ SG_ 913 EPAS3S_a156_angleSensorDivergenc "Electric power steering (secondary): a156 angle sensor divergence";
CM_ SG_ 913 EPAS3S_a157_pmState2Mia "Electric power steering (secondary): a157 pm state2 mia";
CM_ SG_ 913 EPAS3S_a158_pmState2CntError "Electric power steering (secondary): a158 pm state2 cnt error";
CM_ SG_ 913 EPAS3S_a159_pmState2CsError "Electric power steering (secondary): a159 pm state2 cs error";
CM_ SG_ 913 EPAS3S_a160_latentFaultTestResul "Electric power steering (secondary): a160 latent fault test result";
CM_ SG_ 913 EPAS3S_a161_initTestPhaDisconnIn "Electric power steering (secondary): a161 init test pha disconn info";
CM_ SG_ 913 EPAS3S_a162_initTestHSDFetInfo "Electric power steering (secondary): a162 init test HSD fet info";
CM_ SG_ 913 EPAS3S_a163_initTestGateDrvrInfo "Electric power steering (secondary): a163 init test gate drvr info";
CM_ SG_ 913 EPAS3S_a164_initTestDCSInfo "Electric power steering (secondary): a164 init test DCS info";
CM_ SG_ 913 EPAS3S_a165_epbStatusMia "Electric power steering (secondary): a165 epb status mia";
CM_ SG_ 913 EPAS3S_a166_epbStatusCntError "Electric power steering (secondary): a166 epb status cnt error";
CM_ SG_ 913 EPAS3S_a167_epbStatusCsError "Electric power steering (secondary): a167 epb status cs error";
CM_ SG_ 913 EPAS3S_a168_torsionBarTorqueQfDe "Electric power steering (secondary): a168 torsion bar torque qf degraded";
CM_ BO_ 980 "Electric power steering (secondary) message: angle calibration";
CM_ SG_ 980 EPAS3S_appliedAngleOffset "This represents the angle delta between the absolute steering angle reference and what EPAS estimates to be straight ahead. The steering angle offset can change up to 5deg at the beginning of each drive cycle.";
CM_ SG_ 980 EPAS3S_calculatedAngleOffset "Reports the calculated steering angle offset learned between the Steering Column Control Module (SCCM) and the Electronic Power Assist Steering (EPAS) steering angle.";
CM_ SG_ 980 EPAS3S_resyncStatus "Electric power steering (secondary): resync status";
CM_ SG_ 980 EPAS3S_pullDriftLongTermTrq "The learned, long term pull drift or road crown compensation torque that the rack is applying to the steering wheel.";
CM_ SG_ 980 EPAS3S_pullDriftCompTrq "The current pull drift or road crown compensation torque that the rack is applying to the steering wheel.";
CM_ SG_ 980 EPAS3S_learnedSCCMOffset "Electric power steering (secondary): learned SCCM offset";
BA_DEF_ BO_ "GenMsgCycleTime" INT 0 3600000;
BA_DEF_ BO_ "GenMsgSendType" ENUM "Cyclic","NotUsed","NotUsed","NotUsed","NotUsed","NotUsed","NotUsed","IfActive","NoMsgSendType","NotUsed";
BA_DEF_ BO_ "VFrameFormat" ENUM "StandardCAN","ExtendedCAN","reserved","J1939PG","reserved","reserved","reserved","reserved","reserved","reserved","reserved","reserved","reserved","reserved","StandardCAN_FD","ExtendedCAN_FD";
BA_DEF_ BO_ "CANFD_BRS" ENUM "0","1";
BA_DEF_ SG_ "GenSigSNA" STRING;
BA_DEF_ SG_ "SystemSignalLongSymbol" STRING;
BA_DEF_ SG_ "Confidence" ENUM "validated","plausible","layout-only","contradicted";
BA_DEF_DEF_ "GenMsgCycleTime" 0;
BA_DEF_DEF_ "GenMsgSendType" "NoMsgSendType";
BA_DEF_DEF_ "VFrameFormat" "StandardCAN";
BA_DEF_DEF_ "CANFD_BRS" "1";
BA_DEF_DEF_ "GenSigSNA" "";
BA_DEF_DEF_ "SystemSignalLongSymbol" "";
BA_DEF_DEF_ "Confidence" "layout-only";
BA_ "GenMsgCycleTime" BO_ 2006 100;
BA_ "GenMsgSendType" BO_ 2006 0;
BA_ "GenMsgCycleTime" BO_ 597 100;
BA_ "GenMsgSendType" BO_ 597 0;
BA_ "GenMsgCycleTime" BO_ 296 100;
BA_ "GenMsgSendType" BO_ 296 0;
BA_ "GenMsgCycleTime" BO_ 616 100;
BA_ "GenMsgSendType" BO_ 616 0;
BA_ "GenMsgCycleTime" BO_ 280 10;
BA_ "GenMsgSendType" BO_ 280 0;
BA_ "GenMsgCycleTime" BO_ 2036 20;
BA_ "GenMsgSendType" BO_ 2036 0;
BA_ "GenMsgCycleTime" BO_ 615 1000;
BA_ "GenMsgSendType" BO_ 615 0;
BA_ "GenMsgCycleTime" BO_ 999 1000;
BA_ "GenMsgSendType" BO_ 999 0;
BA_ "GenMsgCycleTime" BO_ 2035 1000;
BA_ "GenMsgSendType" BO_ 2035 0;
BA_ "GenMsgCycleTime" BO_ 977 1000;
BA_ "GenMsgSendType" BO_ 977 0;
BA_ "GenMsgCycleTime" BO_ 817 1000;
BA_ "GenMsgSendType" BO_ 817 0;
BA_ "GenMsgCycleTime" BO_ 883 10;
BA_ "GenMsgSendType" BO_ 883 0;
BA_ "GenMsgCycleTime" BO_ 913 1000;
BA_ "GenMsgSendType" BO_ 913 0;
BA_ "GenMsgCycleTime" BO_ 980 1000;
BA_ "GenMsgSendType" BO_ 980 0;
BA_ "Confidence" SG_ 2006 DI_stalklessInterfacesChecksum 0;
BA_ "Confidence" SG_ 2006 DI_stalklessInterfacesCounter 0;
BA_ "Confidence" SG_ 2006 DI_smartShiftClosureOpen 0;
BA_ "Confidence" SG_ 2006 DI_smartShiftSeatbeltUnbuckled 0;
BA_ "Confidence" SG_ 2006 DI_smartShiftAvailable 0;
BA_ "Confidence" SG_ 2006 DI_smartShiftPrimed 0;
BA_ "Confidence" SG_ 2006 DI_smartShiftBrakePressed 0;
BA_ "Confidence" SG_ 2006 DI_smartShiftBrakeReapplyRequire 0;
BA_ "SystemSignalLongSymbol" SG_ 2006 DI_smartShiftBrakeReapplyRequire "DI_smartShiftBrakeReapplyRequired";
BA_ "Confidence" SG_ 597 DI_lastQualifiedGear 0;
BA_ "GenSigSNA" SG_ 597 DI_lastQualifiedGear "7";
BA_ "Confidence" SG_ 597 DI_lastDrivingGear 0;
BA_ "GenSigSNA" SG_ 597 DI_lastDrivingGear "7";
BA_ "Confidence" SG_ 597 DI_distDrivenInGear 0;
BA_ "Confidence" SG_ 597 DI_frontBlocked 0;
BA_ "Confidence" SG_ 597 DI_rearBlocked 0;
BA_ "Confidence" SG_ 597 DI_firstShiftOccurred 0;
BA_ "Confidence" SG_ 597 DI_suggestedGearReason 0;
BA_ "Confidence" SG_ 597 DI_parallelParked 0;
BA_ "Confidence" SG_ 597 DI_smartShiftGear 0;
BA_ "Confidence" SG_ 597 DI_smartShiftUnavailableReason 0;
BA_ "GenSigSNA" SG_ 597 DI_smartShiftUnavailableReason "0";
BA_ "Confidence" SG_ 296 DI_limitRegenPower 0;
BA_ "Confidence" SG_ 296 DI_limitIBat 0;
BA_ "Confidence" SG_ 296 DI_limitVBatLow 0;
BA_ "Confidence" SG_ 296 DI_limitVBatHigh 0;
BA_ "Confidence" SG_ 296 DI_limitObstacleDetection 0;
BA_ "Confidence" SG_ 296 DI_limitSystemLimp 0;
BA_ "Confidence" SG_ 296 DI_limitSystemGPO 0;
BA_ "Confidence" SG_ 296 DI_limitShift 0;
BA_ "Confidence" SG_ 296 DI_limitDriveTorque 0;
BA_ "Confidence" SG_ 296 DI_limitRegenTorque 0;
BA_ "Confidence" SG_ 296 DI_limitVehicleSpeed 0;
BA_ "Confidence" SG_ 296 DI_limitBmsMiaFreeze 0;
BA_ "Confidence" SG_ 296 DI_limitSystemSpinDownLearning 0;
BA_ "Confidence" SG_ 296 DI_limitCdp 0;
BA_ "Confidence" SG_ 296 DI_vehicleSpeedLimitType 0;
BA_ "Confidence" SG_ 296 DI_vehicleSpeedLimit 0;
BA_ "GenSigSNA" SG_ 296 DI_vehicleSpeedLimit "511";
BA_ "Confidence" SG_ 296 DI_vehicleSpeedLimitReason 0;
BA_ "Confidence" SG_ 296 DI_proximity 0;
BA_ "Confidence" SG_ 296 DI_limitClosureNotClosed 0;
BA_ "Confidence" SG_ 296 DI_undersideAbuse 0;
BA_ "Confidence" SG_ 296 DI_immobilizerAuthLevel 0;
BA_ "Confidence" SG_ 296 DI_manualRecoveryDistanceRemaini 0;
BA_ "GenSigSNA" SG_ 296 DI_manualRecoveryDistanceRemaini "127";
BA_ "SystemSignalLongSymbol" SG_ 296 DI_manualRecoveryDistanceRemaini "DI_manualRecoveryDistanceRemaining";
BA_ "Confidence" SG_ 296 DI_restrictedDrivingMode 0;
BA_ "Confidence" SG_ 616 DI_sysHeatPowerMax 0;
BA_ "Confidence" SG_ 616 DI_sysHeatPowerActual 0;
BA_ "Confidence" SG_ 616 DI_sysDrivePowerMax 0;
BA_ "GenSigSNA" SG_ 616 DI_sysDrivePowerMax "511";
BA_ "Confidence" SG_ 616 DI_primaryUnitSiliconType 0;
BA_ "Confidence" SG_ 616 DI_sysRegenPowerMax 0;
BA_ "GenSigSNA" SG_ 616 DI_sysRegenPowerMax "255";
BA_ "Confidence" SG_ 280 DI_systemStatusChecksum 0;
BA_ "Confidence" SG_ 280 DI_systemStatusCounter 0;
BA_ "Confidence" SG_ 280 DI_secondaryGearControlStatus 0;
BA_ "Confidence" SG_ 280 DI_immobilizerState 0;
BA_ "GenSigSNA" SG_ 280 DI_immobilizerState "0";
BA_ "Confidence" SG_ 280 DI_systemState 0;
BA_ "Confidence" SG_ 280 DI_brakePedalState 0;
BA_ "Confidence" SG_ 280 DI_gear 0;
BA_ "GenSigSNA" SG_ 280 DI_gear "7";
BA_ "Confidence" SG_ 280 DI_driveBlocked 0;
BA_ "Confidence" SG_ 280 DI_hvilSystemStatus 0;
BA_ "GenSigSNA" SG_ 280 DI_hvilSystemStatus "3";
BA_ "Confidence" SG_ 280 DI_driveModeState 0;
BA_ "Confidence" SG_ 280 DI_shiftRequestType 0;
BA_ "Confidence" SG_ 280 DI_accelPedalPos 0;
BA_ "GenSigSNA" SG_ 280 DI_accelPedalPos "255";
BA_ "Confidence" SG_ 280 DI_tractionControlMode 0;
BA_ "Confidence" SG_ 280 DI_dynoModeAvailable 0;
BA_ "Confidence" SG_ 280 DI_epbRequest 0;
BA_ "Confidence" SG_ 280 DI_brakeSource 0;
BA_ "Confidence" SG_ 280 DI_keepDrivePowerStateRequest 0;
BA_ "Confidence" SG_ 280 DI_trackModeState 0;
BA_ "Confidence" SG_ 280 DI_autonomyControlActive 0;
BA_ "Confidence" SG_ 280 DI_regenLight 0;
BA_ "Confidence" SG_ 280 DI_vehicleAcceleration 0;
BA_ "GenSigSNA" SG_ 280 DI_vehicleAcceleration "2048";
BA_ "Confidence" SG_ 2036 DI_vdcRightChecksum 0;
BA_ "Confidence" SG_ 2036 DI_vdcRightCounter 0;
BA_ "Confidence" SG_ 2036 DI_vdcCommandTypeFrR 0;
BA_ "Confidence" SG_ 2036 DI_vdcCommandTypeReR 0;
BA_ "Confidence" SG_ 2036 DI_vdcCommandABSFrR 0;
BA_ "Confidence" SG_ 2036 DI_vdcCommandABSReR 0;
BA_ "Confidence" SG_ 2036 DI_brakeTorqueTarFrR 0;
BA_ "Confidence" SG_ 2036 DI_brakeTorqueTarReR 0;
BA_ "Confidence" SG_ 2036 DI_wheelSlipLimitFrR 0;
BA_ "Confidence" SG_ 2036 DI_wheelSlipLimitReR 0;
BA_ "Confidence" SG_ 2036 DI_rawLowMuProbability 0;
BA_ "Confidence" SG_ 615 DI_mass 0;
BA_ "Confidence" SG_ 615 DI_massRLS 0;
BA_ "Confidence" SG_ 615 DI_trailerDetected 0;
BA_ "Confidence" SG_ 615 DI_vehicleEstimatesCounter 0;
BA_ "Confidence" SG_ 615 DI_relativeTireTreadDepth 0;
BA_ "GenSigSNA" SG_ 615 DI_relativeTireTreadDepth "32";
BA_ "Confidence" SG_ 615 DI_tireFitment 0;
BA_ "GenSigSNA" SG_ 615 DI_tireFitment "3";
BA_ "Confidence" SG_ 615 DI_rollCoeff 0;
BA_ "Confidence" SG_ 615 DI_massConfidence 0;
BA_ "Confidence" SG_ 615 DI_gradeEst 0;
BA_ "Confidence" SG_ 615 DI_vehicleEstimatesChecksum 0;
BA_ "Confidence" SG_ 615 DI_gradeEstInternal 0;
BA_ "Confidence" SG_ 615 DI_massConfidenceRLS 0;
BA_ "Confidence" SG_ 615 DI_steeringAngleOffset 0;
BA_ "Confidence" SG_ 1237 DPB_alertID 1;
BA_ "Confidence" SG_ 1237 DPB_alertState 1;
BA_ "Confidence" SG_ 999 DPB_matrixIndex 1;
BA_ "SystemSignalLongSymbol" SG_ 999 DPB_a001_pPlungerSensorOffsetHig "DPB_a001_pPlungerSensorOffsetHigh";
BA_ "SystemSignalLongSymbol" SG_ 999 DPB_a018_largeLeakageDetectedGoo "DPB_a018_largeLeakageDetectedGoodCheck";
BA_ "SystemSignalLongSymbol" SG_ 999 DPB_a023_initialPlungerCheckFail "DPB_a023_initialPlungerCheckFailed";
BA_ "SystemSignalLongSymbol" SG_ 999 DPB_a035_PDURouterinitialization "DPB_a035_PDURouterinitializationFailed";
BA_ "SystemSignalLongSymbol" SG_ 999 DPB_a036_lossOfPDUInstanceDetect "DPB_a036_lossOfPDUInstanceDetected";
BA_ "SystemSignalLongSymbol" SG_ 999 DPB_a038_plungerCircuitPressHigh "DPB_a038_plungerCircuitPressHighGoodCheck";
BA_ "SystemSignalLongSymbol" SG_ 999 DPB_a040_plungerCircuitPressLowG "DPB_a040_plungerCircuitPressLowGoodCheck";
BA_ "SystemSignalLongSymbol" SG_ 999 DPB_a042_motorLoadPressImplausib "DPB_a042_motorLoadPressImplausible";
BA_ "SystemSignalLongSymbol" SG_ 999 DPB_a047_pPlungerPlausCheckFailu "DPB_a047_pPlungerPlausCheckFailure";
BA_ "SystemSignalLongSymbol" SG_ 999 DPB_a053_hydraulicAssemblyModeAc "DPB_a053_hydraulicAssemblyModeActive";
BA_ "SystemSignalLongSymbol" SG_ 999 DPB_a055_unsupportedSeriesHWDete "DPB_a055_unsupportedSeriesHWDetected";
BA_ "SystemSignalLongSymbol" SG_ 999 DPB_a085_infoFailureWrongCUBASHa "DPB_a085_infoFailureWrongCUBASHandlingDetected";
BA_ "SystemSignalLongSymbol" SG_ 999 DPB_a086_diagHydProtectionPressF "DPB_a086_diagHydProtectionPressFault";
BA_ "SystemSignalLongSymbol" SG_ 999 DPB_a087_diagHydProtectionVlvFau "DPB_a087_diagHydProtectionVlvFault";
BA_ "SystemSignalLongSymbol" SG_ 999 DPB_a111_hydraulicHardUndervolta "DPB_a111_hydraulicHardUndervoltage";
BA_ "SystemSignalLongSymbol" SG_ 999 DPB_a127_hydraulicAsicShortCircu "DPB_a127_hydraulicAsicShortCircuit";
BA_ "SystemSignalLongSymbol" SG_ 999 DPB_a129_AsicTrimmingNotComplete "DPB_a129_AsicTrimmingNotCompleted";
BA_ "SystemSignalLongSymbol" SG_ 999 DPB_a131_ASICOvercurrentOnGPIO25 "DPB_a131_ASICOvercurrentOnGPIO250_1";
BA_ "SystemSignalLongSymbol" SG_ 999 DPB_a132_ASICOvercurrentOnGPIO25 "DPB_a132_ASICOvercurrentOnGPIO250_2";
BA_ "SystemSignalLongSymbol" SG_ 999 DPB_a133_ASICOvercurrentOnGPIO50 "DPB_a133_ASICOvercurrentOnGPIO50_1";
BA_ "SystemSignalLongSymbol" SG_ 999 DPB_a134_ASICOvercurrentOnGPIO50 "DPB_a134_ASICOvercurrentOnGPIO50_2";
BA_ "SystemSignalLongSymbol" SG_ 999 DPB_a135_ASICOvercurrentOnGPIO50 "DPB_a135_ASICOvercurrentOnGPIO50_3";
BA_ "SystemSignalLongSymbol" SG_ 999 DPB_a136_ASICOvercurrentOnGPIO50 "DPB_a136_ASICOvercurrentOnGPIO50_4";
BA_ "SystemSignalLongSymbol" SG_ 999 DPB_a139_DIchassisControlChecksu "DPB_a139_DIchassisControlChecksum";
BA_ "SystemSignalLongSymbol" SG_ 999 DPB_a191_VCLEFTepbmStatusChecksu "DPB_a191_VCLEFTepbmStatusChecksum";
BA_ "SystemSignalLongSymbol" SG_ 999 DPB_a194_VCRIGHTepbmStatusCounte "DPB_a194_VCRIGHTepbmStatusCounter";
BA_ "SystemSignalLongSymbol" SG_ 999 DPB_a195_VCRIGHTepbmStatusChecks "DPB_a195_VCRIGHTepbmStatusChecksum";
BA_ "SystemSignalLongSymbol" SG_ 999 DPB_a197_VCRIGHTepbmStatusTimeou "DPB_a197_VCRIGHTepbmStatusTimeout";
BA_ "SystemSignalLongSymbol" SG_ 999 DPB_a200_ESPRunoutSupportNotAvai "DPB_a200_ESPRunoutSupportNotAvailable";
BA_ "SystemSignalLongSymbol" SG_ 999 DPB_a202_vehicleStandstillQFault "DPB_a202_vehicleStandstillQFaulty";
BA_ "SystemSignalLongSymbol" SG_ 999 DPB_a220_excessiveBoostWakeupsDe "DPB_a220_excessiveBoostWakeupsDetected";
BA_ "SystemSignalLongSymbol" SG_ 999 DPB_a222_excessiveEcuResetsDetec "DPB_a222_excessiveEcuResetsDetected";
BA_ "SystemSignalLongSymbol" SG_ 999 DPB_a242_uCSafetyNotificationGRA "DPB_a242_uCSafetyNotificationGRAM";
BA_ "SystemSignalLongSymbol" SG_ 999 DPB_a256_valveRelayActuationFaul "DPB_a256_valveRelayActuationFault";
BA_ "SystemSignalLongSymbol" SG_ 999 DPB_a259_valveRelayTestUndervolt "DPB_a259_valveRelayTestUndervoltage";
BA_ "SystemSignalLongSymbol" SG_ 999 DPB_a260_valveRelaySafetySwitchF "DPB_a260_valveRelaySafetySwitchFault";
BA_ "SystemSignalLongSymbol" SG_ 999 DPB_a292_CBDS_fillBufferThreshol "DPB_a292_CBDS_fillBufferThreshold";
BA_ "SystemSignalLongSymbol" SG_ 999 DPB_a298_runningPlungerCircuitTe "DPB_a298_runningPlungerCircuitTest";
BA_ "SystemSignalLongSymbol" SG_ 999 DPB_a303_actuatingDIFullTorqueCm "DPB_a303_actuatingDIFullTorqueCmd";
BA_ "SystemSignalLongSymbol" SG_ 999 DPB_a305_DIbrakeTorqueCommandAnd "DPB_a305_DIbrakeTorqueCommandAndFlagMismatch";
BA_ "SystemSignalLongSymbol" SG_ 999 DPB_a306_actuatorFallbackBasicMa "DPB_a306_actuatorFallbackBasicMap";
BA_ "SystemSignalLongSymbol" SG_ 999 DPB_a312_continuouslyActivatedVa "DPB_a312_continuouslyActivatedValvesOff";
BA_ "SystemSignalLongSymbol" SG_ 999 DPB_a313_qualifiedBrakeEventDete "DPB_a313_qualifiedBrakeEventDetected";
BA_ "SystemSignalLongSymbol" SG_ 999 DPB_a314_runningCyclicVolumeChec "DPB_a314_runningCyclicVolumeCheck";
BA_ "SystemSignalLongSymbol" SG_ 999 DPB_a315_runningLeakageAndAirMon "DPB_a315_runningLeakageAndAirMonitoring";
BA_ "SystemSignalLongSymbol" SG_ 999 DPB_a316_lowBrakeFluidDetectedOn "DPB_a316_lowBrakeFluidDetectedOnHillSlope";
BA_ "SystemSignalLongSymbol" SG_ 999 DPB_a317_DASredundantBrakingCont "DPB_a317_DASredundantBrakingControlPartyChecksum";
BA_ "SystemSignalLongSymbol" SG_ 999 DPB_a318_DASredundantBrakingCont "DPB_a318_DASredundantBrakingControlPartyCounter";
BA_ "SystemSignalLongSymbol" SG_ 999 DPB_a319_DASredundantBrakingCont "DPB_a319_DASredundantBrakingControlPartyDLC";
BA_ "SystemSignalLongSymbol" SG_ 999 DPB_a320_DASredundantBrakingCont "DPB_a320_DASredundantBrakingControlPartyTimeout";
BA_ "SystemSignalLongSymbol" SG_ 999 DPB_a321_DASredundantBrakingCont "DPB_a321_DASredundantBrakingControlChassisChecksum";
BA_ "SystemSignalLongSymbol" SG_ 999 DPB_a322_DASredundantBrakingCont "DPB_a322_DASredundantBrakingControlChassisCounter";
BA_ "SystemSignalLongSymbol" SG_ 999 DPB_a323_DASredundantBrakingCont "DPB_a323_DASredundantBrakingControlChassisDLC";
BA_ "SystemSignalLongSymbol" SG_ 999 DPB_a324_DASredundantBrakingCont "DPB_a324_DASredundantBrakingControlChassisTimeout";
BA_ "Confidence" SG_ 1426 EPAS3P_alertID 1;
BA_ "Confidence" SG_ 1426 EPAS3P_alertState 1;
BA_ "Confidence" SG_ 1426 EPAS3P_a147_transitionReason 1;
BA_ "Confidence" SG_ 1426 EPAS3P_a149_pcbTemp 1;
BA_ "Confidence" SG_ 1426 EPAS3P_a150_pcbTemp 1;
BA_ "Confidence" SG_ 1426 EPAS3P_a150_phaUMainPathCalcDiff 1;
BA_ "Confidence" SG_ 1426 EPAS3P_a150_phaVMainPathCalcDiff 1;
BA_ "SystemSignalLongSymbol" SG_ 1426 EPAS3P_a150_otherECUAssistStatus "EPAS3P_a150_otherECUAssistStatusFlag";
BA_ "Confidence" SG_ 1426 EPAS3P_a155_vehicleSpeed 1;
BA_ "Confidence" SG_ 1426 EPAS3P_a156_vehicleSpeed 1;
BA_ "Confidence" SG_ 1426 EPAS3P_a160_currentSensorStatus 1;
BA_ "Confidence" SG_ 1426 EPAS3P_a160_gateDriverStatus 1;
BA_ "Confidence" SG_ 1426 EPAS3P_a160_highSideDisconnectFe 1;
BA_ "SystemSignalLongSymbol" SG_ 1426 EPAS3P_a160_highSideDisconnectFe "EPAS3P_a160_highSideDisconnectFetStatus";
BA_ "Confidence" SG_ 1426 EPAS3P_a160_phaseDisconnectFetSt 1;
BA_ "SystemSignalLongSymbol" SG_ 1426 EPAS3P_a160_phaseDisconnectFetSt "EPAS3P_a160_phaseDisconnectFetStatus";
BA_ "Confidence" SG_ 1426 EPAS3P_a160_inverterFetStatus 1;
BA_ "Confidence" SG_ 1426 EPAS3P_a160_hsdFetFailShortTest 1;
BA_ "Confidence" SG_ 1426 EPAS3P_a160_phaDisconnFailOpenTe 1;
BA_ "SystemSignalLongSymbol" SG_ 1426 EPAS3P_a160_phaDisconnFailOpenTe "EPAS3P_a160_phaDisconnFailOpenTest";
BA_ "Confidence" SG_ 1426 EPAS3P_a160_phaDisconnFailShortT 1;
BA_ "SystemSignalLongSymbol" SG_ 1426 EPAS3P_a160_phaDisconnFailShortT "EPAS3P_a160_phaDisconnFailShortTest";
BA_ "Confidence" SG_ 1426 EPAS3P_a160_invFetInitTest 1;
BA_ "Confidence" SG_ 1426 EPAS3P_a160_gateDrvrInitTest 1;
BA_ "SystemSignalLongSymbol" SG_ 1426 EPAS3P_a160_latentFaultTestTimeo "EPAS3P_a160_latentFaultTestTimeout";
BA_ "Confidence" SG_ 1426 EPAS3P_a161_pcoMinPhaseBCurrent 1;
BA_ "Confidence" SG_ 1426 EPAS3P_a161_pcoMaxPhaseBCurrent 1;
BA_ "Confidence" SG_ 1426 EPAS3P_a161_pcoMinPhaseACurrent 1;
BA_ "Confidence" SG_ 1426 EPAS3P_a161_pcoMaxPhaseACurrent 1;
BA_ "Confidence" SG_ 1426 EPAS3P_a162_vBridgeClosed 1;
BA_ "Confidence" SG_ 1426 EPAS3P_a162_vBridgeOpen 1;
BA_ "Confidence" SG_ 1426 EPAS3P_a163_gateDrvrStatusReg 1;
BA_ "Confidence" SG_ 1426 EPAS3P_a163_gateDrvrDiag2Reg 1;
BA_ "Confidence" SG_ 1426 EPAS3P_a163_gateDrvrDiag1Reg 1;
BA_ "Confidence" SG_ 1426 EPAS3P_a163_gateDrvrDiag0Reg 1;
BA_ "Confidence" SG_ 1426 EPAS3P_a164_dcsRegister0x19 1;
BA_ "Confidence" SG_ 2035 EPAS3P_matrixIndex 1;
BA_ "SystemSignalLongSymbol" SG_ 2035 EPAS3P_a149_currentSensPathSwitc "EPAS3P_a149_currentSensPathSwitch";
BA_ "SystemSignalLongSymbol" SG_ 2035 EPAS3P_a150_currentSensOffsetDet "EPAS3P_a150_currentSensOffsetDetect";
BA_ "SystemSignalLongSymbol" SG_ 2035 EPAS3P_a156_angleSensorDivergenc "EPAS3P_a156_angleSensorDivergence";
BA_ "SystemSignalLongSymbol" SG_ 2035 EPAS3P_a160_latentFaultTestResul "EPAS3P_a160_latentFaultTestResult";
BA_ "SystemSignalLongSymbol" SG_ 2035 EPAS3P_a161_initTestPhaDisconnIn "EPAS3P_a161_initTestPhaDisconnInfo";
BA_ "SystemSignalLongSymbol" SG_ 2035 EPAS3P_a168_torsionBarTorqueQfDe "EPAS3P_a168_torsionBarTorqueQfDegraded";
BA_ "Confidence" SG_ 977 EPAS3P_appliedAngleOffset 0;
BA_ "Confidence" SG_ 977 EPAS3P_calculatedAngleOffset 0;
BA_ "Confidence" SG_ 977 EPAS3P_resyncStatus 0;
BA_ "Confidence" SG_ 977 EPAS3P_pullDriftLongTermTrq 0;
BA_ "Confidence" SG_ 977 EPAS3P_pullDriftCompTrq 0;
BA_ "Confidence" SG_ 977 EPAS3P_learnedSCCMOffset 0;
BA_ "Confidence" SG_ 817 EPAS3P_infoIndex 1;
BA_ "Confidence" SG_ 817 EPAS3P_infoBuildType 0;
BA_ "Confidence" SG_ 817 EPAS3P_infoComponentID 0;
BA_ "Confidence" SG_ 817 EPAS3P_infoPcbaID 0;
BA_ "Confidence" SG_ 817 EPAS3P_infoAssemblyID 0;
BA_ "Confidence" SG_ 817 EPAS3P_infoUsageID 0;
BA_ "Confidence" SG_ 817 EPAS3P_infoApplicationCRC 0;
BA_ "Confidence" SG_ 817 EPAS3P_infoBootUdsProtoVersion 0;
BA_ "Confidence" SG_ 817 EPAS3P_infoBootloaderCRC 0;
BA_ "Confidence" SG_ 817 EPAS3P_infoSubcomponent2 0;
BA_ "Confidence" SG_ 883 EPAS3P_steeringRackForce 1;
BA_ "GenSigSNA" SG_ 883 EPAS3P_steeringRackForce "1023";
BA_ "Confidence" SG_ 883 EPAS3P_steeringFault 1;
BA_ "Confidence" SG_ 883 EPAS3P_steeringReduced 1;
BA_ "Confidence" SG_ 883 EPAS3P_internalSASQF 1;
BA_ "Confidence" SG_ 883 EPAS3P_currentTuneMode 1;
BA_ "Confidence" SG_ 883 EPAS3P_torsionBarTorque 1;
BA_ "GenSigSNA" SG_ 883 EPAS3P_torsionBarTorque "4095";
BA_ "Confidence" SG_ 883 EPAS3P_eacErrorCode 1;
BA_ "GenSigSNA" SG_ 883 EPAS3P_eacErrorCode "15";
BA_ "Confidence" SG_ 883 EPAS3P_internalSAS 1;
BA_ "Confidence" SG_ 883 EPAS3P_handsOnLevel 1;
BA_ "Confidence" SG_ 883 EPAS3P_driverlessState 1;
BA_ "Confidence" SG_ 883 EPAS3P_eacStatus 1;
BA_ "Confidence" SG_ 1592 EPAS3P_udsResponseDataCH 1;
BA_ "Confidence" SG_ 1425 EPAS3S_alertID 1;
BA_ "Confidence" SG_ 1425 EPAS3S_alertState 1;
BA_ "Confidence" SG_ 1425 EPAS3S_a147_transitionReason 1;
BA_ "Confidence" SG_ 1425 EPAS3S_a149_pcbTemp 1;
BA_ "Confidence" SG_ 1425 EPAS3S_a150_pcbTemp 1;
BA_ "Confidence" SG_ 1425 EPAS3S_a150_phaUMainPathCalcDiff 1;
BA_ "Confidence" SG_ 1425 EPAS3S_a150_phaVMainPathCalcDiff 1;
BA_ "SystemSignalLongSymbol" SG_ 1425 EPAS3S_a150_otherECUAssistStatus "EPAS3S_a150_otherECUAssistStatusFlag";
BA_ "Confidence" SG_ 1425 EPAS3S_a155_vehicleSpeed 1;
BA_ "Confidence" SG_ 1425 EPAS3S_a156_vehicleSpeed 1;
BA_ "Confidence" SG_ 1425 EPAS3S_a160_currentSensorStatus 1;
BA_ "Confidence" SG_ 1425 EPAS3S_a160_gateDriverStatus 1;
BA_ "Confidence" SG_ 1425 EPAS3S_a160_highSideDisconnectFe 1;
BA_ "SystemSignalLongSymbol" SG_ 1425 EPAS3S_a160_highSideDisconnectFe "EPAS3S_a160_highSideDisconnectFetStatus";
BA_ "Confidence" SG_ 1425 EPAS3S_a160_phaseDisconnectFetSt 1;
BA_ "SystemSignalLongSymbol" SG_ 1425 EPAS3S_a160_phaseDisconnectFetSt "EPAS3S_a160_phaseDisconnectFetStatus";
BA_ "Confidence" SG_ 1425 EPAS3S_a160_inverterFetStatus 1;
BA_ "Confidence" SG_ 1425 EPAS3S_a160_hsdFetFailShortTest 1;
BA_ "Confidence" SG_ 1425 EPAS3S_a160_phaDisconnFailOpenTe 1;
BA_ "SystemSignalLongSymbol" SG_ 1425 EPAS3S_a160_phaDisconnFailOpenTe "EPAS3S_a160_phaDisconnFailOpenTest";
BA_ "Confidence" SG_ 1425 EPAS3S_a160_phaDisconnFailShortT 1;
BA_ "SystemSignalLongSymbol" SG_ 1425 EPAS3S_a160_phaDisconnFailShortT "EPAS3S_a160_phaDisconnFailShortTest";
BA_ "Confidence" SG_ 1425 EPAS3S_a160_invFetInitTest 1;
BA_ "Confidence" SG_ 1425 EPAS3S_a160_gateDrvrInitTest 1;
BA_ "SystemSignalLongSymbol" SG_ 1425 EPAS3S_a160_latentFaultTestTimeo "EPAS3S_a160_latentFaultTestTimeout";
BA_ "Confidence" SG_ 1425 EPAS3S_a161_pcoMinPhaseBCurrent 1;
BA_ "Confidence" SG_ 1425 EPAS3S_a161_pcoMaxPhaseBCurrent 1;
BA_ "Confidence" SG_ 1425 EPAS3S_a161_pcoMinPhaseACurrent 1;
BA_ "Confidence" SG_ 1425 EPAS3S_a161_pcoMaxPhaseACurrent 1;
BA_ "Confidence" SG_ 1425 EPAS3S_a162_vBridgeClosed 1;
BA_ "Confidence" SG_ 1425 EPAS3S_a162_vBridgeOpen 1;
BA_ "Confidence" SG_ 1425 EPAS3S_a163_gateDrvrStatusReg 1;
BA_ "Confidence" SG_ 1425 EPAS3S_a163_gateDrvrDiag2Reg 1;
BA_ "Confidence" SG_ 1425 EPAS3S_a163_gateDrvrDiag1Reg 1;
BA_ "Confidence" SG_ 1425 EPAS3S_a163_gateDrvrDiag0Reg 1;
BA_ "Confidence" SG_ 1425 EPAS3S_a164_dcsRegister0x19 1;
BA_ "Confidence" SG_ 913 EPAS3S_matrixIndex 1;
BA_ "SystemSignalLongSymbol" SG_ 913 EPAS3S_a149_currentSensPathSwitc "EPAS3S_a149_currentSensPathSwitch";
BA_ "SystemSignalLongSymbol" SG_ 913 EPAS3S_a150_currentSensOffsetDet "EPAS3S_a150_currentSensOffsetDetect";
BA_ "SystemSignalLongSymbol" SG_ 913 EPAS3S_a156_angleSensorDivergenc "EPAS3S_a156_angleSensorDivergence";
BA_ "SystemSignalLongSymbol" SG_ 913 EPAS3S_a160_latentFaultTestResul "EPAS3S_a160_latentFaultTestResult";
BA_ "SystemSignalLongSymbol" SG_ 913 EPAS3S_a161_initTestPhaDisconnIn "EPAS3S_a161_initTestPhaDisconnInfo";
BA_ "SystemSignalLongSymbol" SG_ 913 EPAS3S_a168_torsionBarTorqueQfDe "EPAS3S_a168_torsionBarTorqueQfDegraded";
BA_ "Confidence" SG_ 980 EPAS3S_appliedAngleOffset 0;
BA_ "Confidence" SG_ 980 EPAS3S_calculatedAngleOffset 0;
BA_ "Confidence" SG_ 980 EPAS3S_resyncStatus 0;
BA_ "Confidence" SG_ 980 EPAS3S_pullDriftLongTermTrq 0;
BA_ "Confidence" SG_ 980 EPAS3S_pullDriftCompTrq 0;
BA_ "Confidence" SG_ 980 EPAS3S_learnedSCCMOffset 0;
VAL_ 597 DI_lastQualifiedGear 7 "DI_GEAR_SNA" 4 "DI_GEAR_D" 3 "DI_GEAR_N" 2 "DI_GEAR_R" 1 "DI_GEAR_P" 0 "DI_GEAR_INVALID" ;
VAL_ 597 DI_lastDrivingGear 7 "DI_GEAR_SNA" 4 "DI_GEAR_D" 3 "DI_GEAR_N" 2 "DI_GEAR_R" 1 "DI_GEAR_P" 0 "DI_GEAR_INVALID" ;
VAL_ 597 DI_suggestedGearReason 14 "REASON_1ST_SHFT_PAR_PARK_NO_USS" 13 "REASON_AP_NOT_READY" 12 "REASON_EEPROM" 11 "REASON_AP_MIA" 10 "REASON_AP_NOT_CONFIDENT" 9 "REASON_AP" 8 "REASON_SUB_SHFT" 7 "REASON_SUB_SHFT_PAR_PARK" 6 "REASON_SUB_SHFT_RE_BLCK_PAR_PARK" 5 "REASON_SUB_SHFT_RE_BLCK" 4 "REASON_1ST_SHFT_FR_BLCK_PAR_PARK" 3 "REASON_1ST_SHFT_RE_BLCK" 2 "REASON_1ST_SHFT_FR_BLCK" 1 "REASON_1ST_SHFT_PAR_PARK" 0 "REASON_RETRACE" ;
VAL_ 597 DI_smartShiftGear 2 "REVERSE" 1 "DRIVE" 0 "NONE" ;
VAL_ 597 DI_smartShiftUnavailableReason 18 "SMART_SHIFT_UNAVAILABLE_DAS_MIA" 17 "SMART_SHIFT_UNAVAILABLE_DAS_NOT_CONFIDENT" 16 "SMART_SHIFT_UNAVAILABLE_DISPLAY_ERROR" 15 "SMART_SHIFT_UNAVAILABLE_VDC_UNAVAILABLE" 14 "SMART_SHIFT_UNAVAILABLE_VHLD_UNAVAILABLE" 13 "SMART_SHIFT_UNAVAILABLE_OPD_UNAVAILABLE" 12 "SMART_SHIFT_UNAVAILABLE_BLS_UNKNOWN" 11 "SMART_SHIFT_UNAVAILABLE_IBST_MIA" 10 "SMART_SHIFT_SILENT_UNAVAILABLE_AEB_ACTIVE" 9 "SMART_SHIFT_SILENT_UNAVAILABLE_CRUISE_REGULATING" 8 "SMART_SHIFT_SILENT_UNAVAILABLE_GTW_NOT_QUALIFIED" 7 "SMART_SHIFT_SILENT_UNAVAILABLE_SGS_ACTIVE" 6 "SMART_SHIFT_SILENT_UNAVAILABLE_CLOSURE_OPEN" 5 "SMART_SHIFT_SILENT_UNAVAILABLE_CHARGE_CABLE_CONNECTED" 4 "SMART_SHIFT_SILENT_UNAVAILABLE_DRIVER_BUCKLED_QF" 3 "SMART_SHIFT_SILENT_UNAVAILABLE_NON_STANDARD_MODE" 2 "SMART_SHIFT_SILENT_UNAVAILABLE_UI_DISABLE" 1 "SMART_SHIFT_UNAVAILABLE_NONE" 0 "SMART_SHIFT_UNAVAILABLE_SNA" ;
VAL_ 296 DI_vehicleSpeedLimitType 2 "POWERTRAIN" 1 "USER" 0 "NONE" ;
VAL_ 296 DI_vehicleSpeedLimit 511 "SNA" ;
VAL_ 296 DI_vehicleSpeedLimitReason 16 "MANUAL_RECOVERY_MODE" 15 "FACTORY_BRAKE_BURNISHING" 14 "TAS_OFFROAD" 13 "SLIP_START_LIMIT" 12 "LV_DEGRADED" 11 "MAX_TIRE_TYPE" 10 "USER" 9 "FRUNK_OPEN" 8 "DAS_PEDAL_CONTROL" 7 "TAS" 6 "TRAILER_MODE" 5 "MAX_CAR_CONFIG" 4 "SERVICE_MODE" 3 "FACTORY_MODE" 2 "FACTORY_LOW_BRAKE_FLUID" 1 "DRIVE_UNIT_LIMIT" 0 "NONE" ;
VAL_ 296 DI_immobilizerAuthLevel 3 "IMMOBILIZER_AUTH_LEVEL_MANUAL_RECOVERY" 2 "IMMOBILIZER_AUTH_LEVEL_AUTONOMY" 1 "IMMOBILIZER_AUTH_LEVEL_USER_DRIVE" 0 "IMMOBILIZER_AUTH_LEVEL_NONE" ;
VAL_ 296 DI_manualRecoveryDistanceRemaini 127 "SNA" ;
VAL_ 296 DI_restrictedDrivingMode 1 "RESTRICTED_DRIVING_MANUAL_RECOVERY" 0 "RESTRICTED_DRIVING_MODE_NONE" ;
VAL_ 616 DI_sysDrivePowerMax 511 "SNA" ;
VAL_ 616 DI_primaryUnitSiliconType 1 "IGBT" 0 "MOSFET" ;
VAL_ 616 DI_sysRegenPowerMax 255 "SNA" ;
VAL_ 280 DI_secondaryGearControlStatus 1 "ACTIVE" 0 "NOT_ACTIVE" ;
VAL_ 280 DI_immobilizerState 6 "DI_IMM_STATE_FAULT" 5 "DI_IMM_STATE_RESET" 4 "DI_IMM_STATE_IDLE" 3 "DI_IMM_STATE_DISARMED" 2 "DI_IMM_STATE_AUTHENTICATING" 1 "DI_IMM_STATE_REQUEST" 0 "DI_IMM_STATE_INIT_SNA" ;
VAL_ 280 DI_systemState 5 "DI_SYS_ENABLE" 4 "DI_SYS_ABORT" 3 "DI_SYS_FAULT" 2 "DI_SYS_STANDBY" 1 "DI_SYS_IDLE" 0 "DI_SYS_UNAVAILABLE" ;
VAL_ 280 DI_brakePedalState 2 "INVALID" 1 "ON" 0 "OFF" ;
VAL_ 280 DI_gear 7 "DI_GEAR_SNA" 4 "DI_GEAR_D" 3 "DI_GEAR_N" 2 "DI_GEAR_R" 1 "DI_GEAR_P" 0 "DI_GEAR_INVALID" ;
VAL_ 280 DI_driveBlocked 4 "DRIVE_BLOCKED_TRUNK" 3 "DRIVE_BLOCKED_FALCON" 2 "DRIVE_BLOCKED_PROX" 1 "DRIVE_BLOCKED_FRUNK" 0 "DRIVE_BLOCKED_NONE" ;
VAL_ 280 DI_hvilSystemStatus 3 "SNA" 2 "CLOSED" 1 "OPEN" 0 "DISABLED" ;
VAL_ 280 DI_driveModeState 1 "DM_STATE_DRIVE" 0 "DM_STATE_NONDRIVE" ;
VAL_ 280 DI_shiftRequestType 3 "SMART_SHIFT" 2 "CCCM_SHIFT" 1 "GTW_SHIFT" 0 "NONE" ;
VAL_ 280 DI_accelPedalPos 255 "SNA" ;
VAL_ 280 DI_tractionControlMode 7 "TC_SLIPPERY_SURFACE" 6 "TC_OFFROAD_ASSIST" 5 "TC_DYNO_MODE" 4 "TC_ROLLS_MODE" 3 "TC_DEV_MODE_2" 2 "TC_DEV_MODE_1" 1 "TC_SLIP_START" 0 "TC_NORMAL" ;
VAL_ 280 DI_epbRequest 2 "DI_EPBREQUEST_UNPARK" 1 "DI_EPBREQUEST_PARK" 0 "DI_EPBREQUEST_NO_REQUEST" ;
VAL_ 280 DI_brakeSource 1 "DI" 0 "DAS" ;
VAL_ 280 DI_keepDrivePowerStateRequest 1 "KEEP_ALIVE" 0 "NO_REQUEST" ;
VAL_ 280 DI_trackModeState 2 "TRACK_MODE_ON" 1 "TRACK_MODE_AVAILABLE" 0 "TRACK_MODE_UNAVAILABLE" ;
VAL_ 280 DI_vehicleAcceleration -2048 "SNA" ;
VAL_ 2036 DI_vdcCommandTypeFrR 3 "VDC_SLIP_COMMAND" 2 "VDC_TORQUE_COMMAND" 1 "BTC_TORQUE_COMMAND" 0 "NO_TORQUE_COMMAND" ;
VAL_ 2036 DI_vdcCommandTypeReR 3 "VDC_SLIP_COMMAND" 2 "VDC_TORQUE_COMMAND" 1 "BTC_TORQUE_COMMAND" 0 "NO_TORQUE_COMMAND" ;
VAL_ 2036 DI_vdcCommandABSFrR 4 "MODIFY_BY_ABS_NO_GMA_NO_EBD" 3 "MODIFY_BY_ABS_NO_GMA" 2 "MODIFY_BY_ABS_ALL" 1 "FEED_THROUGH" 0 "NO_COMMAND" ;
VAL_ 2036 DI_vdcCommandABSReR 4 "MODIFY_BY_ABS_NO_GMA_NO_EBD" 3 "MODIFY_BY_ABS_NO_GMA" 2 "MODIFY_BY_ABS_ALL" 1 "FEED_THROUGH" 0 "NO_COMMAND" ;
VAL_ 2036 DI_brakeTorqueTarFrR 0 "NO_COMMAND" ;
VAL_ 2036 DI_brakeTorqueTarReR 0 "NO_COMMAND" ;
VAL_ 2036 DI_wheelSlipLimitFrR 0 "NO_COMMAND" ;
VAL_ 2036 DI_wheelSlipLimitReR 0 "NO_COMMAND" ;
VAL_ 615 DI_trailerDetected 1 "TRAILER_DETECTED" 0 "TRAILER_NOT_DETECTED" ;
VAL_ 615 DI_relativeTireTreadDepth -32 "SNA" ;
VAL_ 615 DI_tireFitment 3 "FITMENT_SNA" 1 "FITMENT_STAGGERED" 0 "FITMENT_SQUARE" ;
VAL_ 615 DI_massConfidence 1 "MASS_CONFIDED" 0 "MASS_NOT_CONFIDED" ;
VAL_ 615 DI_massConfidenceRLS 1 "MASS_CONFIDED" 0 "MASS_NOT_CONFIDED" ;
VAL_ 1237 DPB_alertID 337 "a337_EMCMain21Timeout" 336 "a336_EMCMain21DLC" 335 "a335_EMCMain21Counter" 334 "a334_EMCMain21Checksum" 333 "a333_EMCMain11Timeout" 332 "a332_EMCMain11DLC" 331 "a331_EMCMain11Counter" 330 "a330_EMCMain11Checksum" 329 "a329_standaloneEBRActive" 328 "a328_DIlocStatus2Timeout" 327 "a327_DIlocStatus2DLC" 326 "a326_DIlocStatus2Counter" 325 "a325_DIlocStatus2Checksum" 324 "a324_DASredundantBrakingControlChassisTimeout" 323 "a323_DASredundantBrakingControlChassisDLC" 322 "a322_DASredundantBrakingControlChassisCounter" 321 "a321_DASredundantBrakingControlChassisChecksum" 320 "a320_DASredundantBrakingControlPartyTimeout" 319 "a319_DASredundantBrakingControlPartyDLC" 318 "a318_DASredundantBrakingControlPartyCounter" 317 "a317_DASredundantBrakingControlPartyChecksum" 316 "a316_lowBrakeFluidDetectedOnHillSlope" 315 "a315_runningLeakageAndAirMonitoring" 314 "a314_runningCyclicVolumeCheck" 313 "a313_qualifiedBrakeEventDetected" 312 "a312_continuouslyActivatedValvesOff" 311 "a311_postrunDurationTooLong" 310 "a310_DIRAxleTorqueInvalid" 309 "a309_DIFAxleTorqueInvalid" 308 "a308_backupMode" 307 "a307_actuatorDegradedMap" 306 "a306_actuatorFallbackBasicMap" 305 "a305_DIbrakeTorqueCommandAndFlagMismatch" 304 "a304_actuatingDITorqueCmd" 303 "a303_actuatingDIFullTorqueCmd" 302 "a302_PM_locStateTimeout" 301 "a301_PM_locStateDLC" 300 "a300_PM_locStateChecksum" 299 "a299_PM_locStateCounter" 298 "a298_runningPlungerCircuitTest" 297 "a297_undefinedAlertDetected" 296 "a296_StatInvalid_DI_FullSNA" 295 "a295_hbaTrackModeActive" 294 "a294_hbaNormalModeActive" 293 "a293_CBDS_fmeInternalEvent" 292 "a292_CBDS_fillBufferThreshold" 291 "a291_extDBRRequestTooLow" 290 "a290_securityInfo" 289 "a289_evacFillNotComplete" 288 "a288_PlantDegradedSW" 287 "a287_brakeCmdStateInvalid" 286 "a286_ebrCmdStateInvalid" 285 "a285_DIbrakeCommandTimeout" 284 "a284_DIbrakeCommandDLC" 283 "a283_DIbrakeCommandChecksum" 282 "a282_DIbrakeCommandCounter" 281 "a281_brakeFluidOORHigh" 280 "a280_LowBrakeFluid" 279 "a279_VCFRONTsensorsTimeout" 278 "a278_VCFRONTsensorsDLC" 277 "a277_VCFRONTsensorsChecksum" 276 "a276_VCFRONTsensorsCounter" 275 "a275_Ps1Ps2PlausibilityFault" 274 "a274_AswSystemTimeOut" 273 "a273_SMMOneRequestsInit" 272 "a272_runtimeAssertionFault" 271 "a271_RPSWrongCalibData" 270 "a270_RPSVectorRangeLow" 269 "a269_RPSVectorRangeHigh" 268 "a268_RPSVectorOscillating" 267 "a267_RpsAngleImplausible" 266 "a266_RPSNvMReadFault" 265 "a265_WdhTaskMonConCnt" 264 "a264_WdhSwBistConCnt" 263 "a263_WdhAsicWdErrorCntStuck" 262 "a262_WdhAsicWdErrorCntLimit" 261 "a261_WdhAsicWdCmdMissing" 260 "a260_valveRelaySafetySwitchFault" 259 "a259_valveRelayTestUndervoltage" 258 "a258_valveRelayOffContinuous" 257 "a257_valveRelayOnContinuous" 256 "a256_valveRelayActuationFault" 255 "a255_valveRelayShort" 254 "a254_valveMV9Fault" 253 "a253_valveMV82Fault" 252 "a252_valveMV81Fault" 251 "a251_valveMV8Fault" 250 "a250_valveMV7Fault" 249 "a249_valveMV62Fault" 248 "a248_valveMV61Fault" 247 "a247_valveMV6Fault" 246 "a246_valveMV5Fault" 245 "a245_valveMV0Fault" 244 "a244_valvesGenericFault" 243 "a243_microSupplyError" 242 "a242_uCSafetyNotificationGRAM" 241 "a241_uCSafetyNotification" 240 "a240_microSafetyLogicFault" 239 "a239_microSafetyFault" 238 "a238_microRegisterFault" 237 "a237_uCVoltageDividerDrift" 236 "a236_UB6SupplyPathFault" 235 "a235_UB6PlausiMonFault" 234 "a234_systemTaskOverRun" 233 "a233_systemTaskJitter" 232 "a232_systemErrorHook" 231 "a231_stackOverUnderFlow" 230 "a230_OSErrorHook" 229 "a229_IREFOutOfRange" 228 "a228_supplyASICInitFault" 227 "a227_brakeFluidLoss" 226 "a226_U5VTestFault" 225 "a225_U5VOutOfRange" 224 "a224_brakeBoostLost" 223 "a223_RAMFault" 222 "a222_excessiveEcuResetsDetected" 221 "a221_notShutdownRight" 220 "a220_excessiveBoostWakeupsDetected" 219 "a219_pressureSensor2Fault" 218 "a218_pressureSensor2Temp" 217 "a217_pressureSensor2Fault" 216 "a216_pressureSensor2Low" 215 "a215_pressureSensor2High" 214 "a214_pressureSensor2Short" 213 "a213_pressureSensor1Fault" 212 "a212_pressureSensor1Temp" 211 "a211_pressureSensor1Fault" 210 "a210_pressureSensor1Low" 209 "a209_pressureSensor1High" 208 "a208_pressureSensor1Short" 207 "a207_hydraulicOvervoltage" 206 "a206_OSTaskSchemeError" 205 "a205_NvMWriteCycleExceed" 204 "a204_CANUndervoltage" 203 "a203_ABSNotAvailable" 202 "a202_vehicleStandstillQFaulty" 201 "a201_vehicleSpeedQFaulty" 200 "a200_ESPRunoutSupportNotAvailable" 199 "a199_pMC1QFaulty" 198 "a198_CANOvervoltage" 197 "a197_VCRIGHTepbmStatusTimeout" 196 "a196_VCRIGHTepbmStatusDLC" 195 "a195_VCRIGHTepbmStatusChecksum" 194 "a194_VCRIGHTepbmStatusCounter" 193 "a193_VCLEFTepbmStatusTimeout" 192 "a192_VCLEFTepbmStatusDLC" 191 "a191_VCLEFTepbmStatusChecksum" 190 "a190_VCLEFTepbmStatusCounter" 189 "a189_LVPowerStateCounter" 188 "a188_LVPowerStateDLC" 187 "a187_LVPowerStateChecksum" 186 "a186_LVPowerStateTimeout" 185 "a185_RCMInertial2Timeout" 184 "a184_RCMInertial2DLC" 183 "a183_RCMInertial2Checksum" 182 "a182_RCMInertial2Counter" 181 "a181_PMstate2Timeout" 180 "a180_PMstate2DLC" 179 "a179_PMstate2Checksum" 178 "a178_PMstate2Counter" 177 "a177_ESP_modulator3Timeout" 176 "a176_ESP_modulator3DLC" 175 "a175_ESP_modulator3Checksum" 174 "a174_ESP_modulator3Counter" 173 "a173_ESP_modulator2Timeout" 172 "a172_ESP_modulator2DLC" 171 "a171_ESP_modulator2Checksum" 170 "a170_ESP_modulator2Counter" 169 "a169_ESP_chassis3Timeout" 168 "a168_ESP_chassis3DLC" 167 "a167_ESP_chassis3Checksum" 166 "a166_ESP_chassis3Counter" 165 "a165_ESP_modulator1Timeout" 164 "a164_ESP_modulator1DLC" 163 "a163_ESP_modulator1Checksum" 162 "a162_ESP_modulator1Counter" 161 "a161_EPBRstatusTimeout" 160 "a160_EPBRstatusDLC" 159 "a159_EPBRstatusChecksum" 158 "a158_EPBRstatusCounter" 157 "a157_EPBLstatusTimeout" 156 "a156_EPBLstatusDLC" 155 "a155_EPBLstatusChecksum" 154 "a154_EPBLstatusCounter" 153 "a153_DIRtorqueTimeout" 152 "a152_DIRtorqueDLC" 151 "a151_DIRtorqueChecksum" 150 "a150_DIRtorqueCounter" 149 "a149_DIFtorqueTimeout" 148 "a148_DIFtorqueDLC" 147 "a147_DIFtorqueChecksum" 146 "a146_DIFtorqueCounter" 145 "a145_DIsystemStatusTimeout" 144 "a144_DIsystemStatusDLC" 143 "a143_DIsystemStatusChecksum" 142 "a142_DIsystemStatusCounter" 141 "a141_DIchassisControlTimeout" 140 "a140_DIchassisControlDLC" 139 "a139_DIchassisControlChecksum" 138 "a138_DIchassisControlCounter" 137 "a137_ASICOvercurrentOnWRHS" 136 "a136_ASICOvercurrentOnGPIO50_4" 135 "a135_ASICOvercurrentOnGPIO50_3" 134 "a134_ASICOvercurrentOnGPIO50_2" 133 "a133_ASICOvercurrentOnGPIO50_1" 132 "a132_ASICOvercurrentOnGPIO250_2" 131 "a131_ASICOvercurrentOnGPIO250_1" 130 "a130_AsicMalfunctionDetected" 129 "a129_AsicTrimmingNotCompleted" 128 "a128_micSpiTransferError" 127 "a127_hydraulicAsicShortCircuit" 126 "a126_MICB6TransferError" 125 "a125_B6AsicFault" 124 "a124_asicOscillatorError" 123 "a123_micAsicInitTestError" 122 "a122_micAsicClkInError" 121 "a121_LiPSOutOfRangeLow" 120 "a120_LiPSOutOfRangeHigh" 119 "a119_LiPS2PwmTransmission" 118 "a118_LiPS2PwmLineLow" 117 "a117_LiPS2PwmLineHigh" 116 "a116_LiPS1SentTransmission" 115 "a115_LiPS1SentSensor" 114 "a114_LiPS1SentLineLow" 113 "a113_LiPS1SentLineHigh" 112 "a112_hydraulicUndervoltage" 111 "a111_hydraulicHardUndervoltage" 110 "a110_HWBISTError" 109 "a109_GTMTbuMonError" 108 "a108_GTMRefFrequencyError" 107 "a107_vrOnFails" 106 "a106_ecuBistCmdTestFault" 105 "a105_ecuWdSContinuousError" 104 "a104_ecuWdStartuptestFault" 103 "a103_ecuVrViaSpiFails" 102 "a102_ecuVrOnWhileWdTimeout" 101 "a101_ecuFastWdTestFault" 100 "a100_ecuErrpinCounterFault" 99 "a099_ecuEnContinuousError" 98 "a098_ecuEnableHyLowFault" 97 "a097_ecuEnableHyHighFault" 96 "a096_ecuEnableElLowFault" 95 "a095_ecuEnableElHighFault" 94 "a094_ecuClockTestFault" 93 "a093_ecuBistFaultCtrFault" 92 "a092_decoupleBitTestFault" 91 "a091_MRGPathTestFault" 90 "a090_flashFault" 89 "a089_ecuBandgap" 88 "a088_DMATransferError" 87 "a087_diagHydProtectionVlvFault" 86 "a086_diagHydProtectionPressFault" 85 "a085_infoFailureWrongCUBASHandlingDetected" 84 "a084_RBCPUException" 83 "a083_chargePumpUndervoltage" 82 "a082_chargePumpFault" 81 "a081_tempSensImplausVoltage" 80 "a080_tempSens2ShortToGround" 79 "a079_tempSens2ShortToSupply" 78 "a078_tempSens1ShortToGround" 77 "a077_tempSens1ShortToSupply" 76 "a076_rotorSinOutOfRangeLow" 75 "a075_rotorSinOutOfRangeHigh" 74 "a074_rotorCosOutOfRangeLow" 73 "a073_rotorCosOutOfRangeHigh" 72 "a072_OBDCurrent2OORLow" 71 "a071_OBDCurrent2OORHigh" 70 "a070_OBDCurrent1OORLow" 69 "a069_OBDCurrent1OORHigh" 68 "a068_BLMMuxerTimeoutError" 67 "a067_current2OffsetLow" 66 "a066_current2OffsetHigh" 65 "a065_current1OffsetLow" 64 "a064_current1OffsetHigh" 63 "a063_motorConfigMismatch" 62 "a062_loadDumpOnFSLTest" 61 "a061_bridgeSwitchInitError" 60 "a060_motorBridgeDriverFault" 59 "a059_factoryModeActive" 58 "a058_AdcSelftestC5P" 57 "a057_AdcPinTest" 56 "a056_AdcPeripheralFault" 55 "a055_unsupportedSeriesHWDetected" 54 "a054_unsupportedHW" 53 "a053_hydraulicAssemblyModeActive" 52 "a052_PSIDTimeOut" 51 "a051_PSCVoltageImplausible" 50 "a050_supplyUndervoltageLvl3" 49 "a049_supplyUndervoltageLvl2" 48 "a048_supplyUndervoltageLvl1" 47 "a047_pPlungerPlausCheckFailure" 46 "a046_supplyOvervoltageLvl3" 45 "a045_supplyOvervoltageLvl2" 44 "a044_supplyOvervoltageLvl1" 43 "a043_PSCMotorSizeReadFault" 42 "a042_motorLoadPressImplausible" 41 "a041_PSCGearRatioReadFault" 40 "a040_plungerCircuitPressLowGoodCheck" 39 "a039_plungerCircuitPressLow" 38 "a038_plungerCircuitPressHighGoodCheck" 37 "a037_plungerCircuitPressHigh" 36 "a036_lossOfPDUInstanceDetected" 35 "a035_PDURouterinitializationFailed" 34 "a034_lipsMemoryEmpty" 33 "a033_motorDynamicLimited" 32 "a032_HWParamWriteFailed" 31 "a031_HWParamReadFailed" 30 "a030_notShutDownRight" 29 "a029_motorTestFault" 28 "a028_motorTempHighLevel2" 27 "a027_motorTempHighLevel1" 26 "a026_LiPSIDTimeout" 25 "a025_backupCircuitLeakage" 24 "a024_ESPLDMFailure" 23 "a023_initialPlungerCheckFailed" 22 "a022_brakeSystemOverheatLvl2" 21 "a021_brakeSystemOverheatLvl1" 20 "a020_ecuHuMismatch" 19 "a019_DETReportError" 18 "a018_largeLeakageDetectedGoodCheck" 17 "a017_largeLeakageDetected" 16 "a016_CAN2BusOff" 15 "a015_CAN1BusOff" 14 "a014_CANControllerHWFault" 13 "a013_softPedalChar" 12 "a012_PtsNonZeroStage2" 11 "a011_PtsNonZeroStage1" 10 "a010_LiPSPtsConsistency" 9 "a009_LiPSPts2Offset" 8 "a008_LiPSPts1Offset" 7 "a007_PMCLeakageDetected" 6 "a006_hardPedalCharGoodCheck" 5 "a005_hardPedalChar" 4 "a004_assertionFault" 3 "a003_AswEEPROMReadFailure" 2 "a002_pMC2SensorOffsetHigh" 1 "a001_pPlungerSensorOffsetHigh" 0 "ALERT_DO_NOT_USE_ZERO" ;
VAL_ 1237 DPB_alertState 1 "SET" 0 "CLEARED" ;
VAL_ 999 DPB_matrixIndex 5 "AlertMatrix5" 4 "AlertMatrix4" 3 "AlertMatrix3" 2 "AlertMatrix2" 1 "AlertMatrix1" 0 "AlertMatrix0" ;
VAL_ 1426 EPAS3P_alertID 171 "a171_difCsError" 170 "a170_difCntError" 169 "a169_difMia" 168 "a168_torsionBarTorqueQfDegraded" 167 "a167_epbStatusCsError" 166 "a166_epbStatusCntError" 165 "a165_epbStatusMia" 164 "a164_initTestDCSInfo" 163 "a163_initTestGateDrvrInfo" 162 "a162_initTestHSDFetInfo" 161 "a161_initTestPhaDisconnInfo" 160 "a160_latentFaultTestResult" 159 "a159_pmState2CsError" 158 "a158_pmState2CntError" 157 "a157_pmState2Mia" 156 "a156_angleSensorDivergence" 155 "a155_backupEacActive" 154 "a154_assistTorqueDisabled" 153 "a153_dcsInitOffset" 152 "a152_dcsDiagReg" 151 "a151_dcsCboot" 150 "a150_currentSensOffsetDetect" 149 "a149_currentSensPathSwitch" 148 "a148_vMaxAssist" 147 "a147_backupVehSpeed" 146 "a146_diSpdCsError" 145 "a145_diSpdCntError" 144 "a144_diSpdMia" 137 "a137_piCtrlCounter85" 136 "a136_piCtrlCounter50" 135 "a135_piCtrlCounter25" 134 "a134_motFeedFwdCounter85" 133 "a133_motFeedFwdCounter50" 132 "a132_motFeedFwdCounter25" 131 "a131_phaseFeedbackError" 130 "a130_sasOffsetNotCal" 129 "a129_combEcu1StatFail" 128 "a128_apsCsError" 127 "a127_apsCntError" 126 "a126_apsMia" 125 "a125_trqSensTrimOutRange" 124 "a124_tempSensStuckInRange" 123 "a123_combEcu2StatFail" 122 "a122_olpActive" 121 "a121_pvtEcuStatCrcError" 120 "a120_pvtEcuStatCntError" 119 "a119_pvtEcuStatMia" 118 "a118_privateBusOff" 117 "a117_ecuStatCrcError" 116 "a116_ecuStatCntError" 115 "a115_ecuStatMia" 114 "a114_gtwConfigMia" 113 "a113_sasStatusError" 112 "a112_sasCsError" 111 "a111_sasCntError" 110 "a110_sasMia" 109 "a109_uiTuneReqCsError" 108 "a108_uiTuneReqCntError" 107 "a107_uiTuneReqMia" 106 "a106_vcFrontTempMia" 105 "a105_vcFrontCsError" 104 "a104_vcFrontCntError" 103 "a103_vcFrontMia" 102 "a102_diCsError" 101 "a101_diCntError" 100 "a100_diMia" 99 "a099_yawRateStatus" 98 "a098_rcmCsError" 97 "a097_rcmCntError" 96 "a096_rcmMia" 95 "a095_espWsStatus" 94 "a094_espWrCsError" 93 "a093_espWrCntError" 92 "a092_espWrMia" 91 "a091_espWsCsError" 90 "a090_espWsCntError" 89 "a089_espWsMia" 88 "a088_dasCsError" 87 "a087_dasCntError" 86 "a086_dasMia" 85 "a085_canBusOff" 84 "a084_eacCancelled" 83 "a083_crcMismatch" 82 "a082_polarityCalError" 81 "a081_coggCompError" 80 "a080_ecuInitArbError" 79 "a079_backupCurrentPlaus" 78 "a078_phaseDisconnectError" 77 "a077_highSideFetError" 76 "a076_tempSensOutofRange" 75 "a075_fspPwrCut" 74 "a074_overHeatProtect" 73 "a073_motParEstError" 72 "a072_motFeedFwdError" 71 "a071_vehSpdCorrError" 70 "a070_hodCorrError" 69 "a069_eacCorrError" 68 "a068_hystCorrError" 67 "a067_yawDampCorrError" 66 "a066_returnCorrError" 65 "a065_trqTarCorrError" 64 "a064_phaseCompCorrError" 63 "a063_dampCorrError" 62 "a062_assistCorrError" 61 "a061_bridgeUv" 60 "a060_battBridgeDiff" 59 "a059_battOvReduced" 58 "a058_battOv" 57 "a057_battUvReduced" 56 "a056_battUv" 55 "a055_floatPointError" 54 "a054_memoryProtectError" 53 "a053_extWatchdogError" 52 "a052_intWatchdogError" 51 "a051_mcuSupError" 50 "a050_mcuSmuError" 49 "a049_piCtrlError" 48 "a048_motPosCalError" 47 "a047_motPosCorrError" 46 "a046_motPos2tempError" 45 "a045_motPos2LogicError" 44 "a044_motPos2MagnetMia" 43 "a043_motPos2Uv" 42 "a042_motPos2ParityError" 41 "a041_motPos1tempError" 40 "a040_motPos1LogicError" 39 "a039_motPos1MagnetMia" 38 "a038_motPos1Uv" 37 "a037_motPos1ParityError" 36 "a036_vbbSupplyOv" 35 "a035_vbbSupplyUv" 34 "a034_vRegError" 33 "a033_vRegOutputOv" 32 "a032_vRegOutputUv" 31 "a031_abnormalShutdown" 30 "a030_phaseWbootUv" 29 "a029_phaseVbootUv" 28 "a028_phaseUbootUv" 27 "a027_phaseWlowOv" 26 "a026_phaseWhighOv" 25 "a025_phaseVlowOv" 24 "a024_phaseVhighOv" 23 "a023_phaseUlowOv" 22 "a022_phaseUhighOv" 21 "a021_phaseWlowUv" 20 "a020_phaseWhighUv" 19 "a019_phaseVlowUv" 18 "a018_phaseVhighUv" 17 "a017_phaseUlowUv" 16 "a016_phaseUhighUv" 15 "a015_gateDriveEeprom" 14 "a014_gateDriveTxError" 13 "a013_gateDriveError" 12 "a012_currentSensCalError" 11 "a011_currentSensError" 10 "a010_trqSensCalError" 9 "a009_sentDiff" 8 "a008_trqSens2Eeprom" 7 "a007_trqSens2Supply" 6 "a006_sent2Error" 5 "a005_sent2Mia" 4 "a004_trqSens1Eeprom" 3 "a003_trqSens1Supply" 2 "a002_sent1Error" 1 "a001_sent1Mia" 0 "ALERT_DO_NOT_USE_ZERO" ;
VAL_ 1426 EPAS3P_alertState 1 "SET" 0 "CLEARED" ;
VAL_ 1426 EPAS3P_a147_transitionReason 2 "MIA" 1 "WSS_FAILURE" 0 "DATA_INTEGRITY" ;
VAL_ 1426 EPAS3P_a160_currentSensorStatus 2 "STATUS_UNKNOWN" 1 "PROBABLE_FAILURE" 0 "NO_ISSUE" ;
VAL_ 1426 EPAS3P_a160_gateDriverStatus 2 "STATUS_UNKNOWN" 1 "PROBABLE_FAILURE" 0 "NO_ISSUE" ;
VAL_ 1426 EPAS3P_a160_highSideDisconnectFe 2 "STATUS_UNKNOWN" 1 "PROBABLE_FAILURE" 0 "NO_ISSUE" ;
VAL_ 1426 EPAS3P_a160_phaseDisconnectFetSt 2 "STATUS_UNKNOWN" 1 "PROBABLE_FAILURE" 0 "NO_ISSUE" ;
VAL_ 1426 EPAS3P_a160_inverterFetStatus 2 "STATUS_UNKNOWN" 1 "PROBABLE_FAILURE" 0 "NO_ISSUE" ;
VAL_ 1426 EPAS3P_a160_hsdFetFailShortTest 2 "NOT_RAN" 1 "FAIL" 0 "PASS" ;
VAL_ 1426 EPAS3P_a160_phaDisconnFailOpenTe 2 "NOT_RAN" 1 "FAIL" 0 "PASS" ;
VAL_ 1426 EPAS3P_a160_phaDisconnFailShortT 2 "NOT_RAN" 1 "FAIL" 0 "PASS" ;
VAL_ 1426 EPAS3P_a160_invFetInitTest 2 "NOT_RAN" 1 "FAIL" 0 "PASS" ;
VAL_ 1426 EPAS3P_a160_gateDrvrInitTest 2 "NOT_RAN" 1 "FAIL" 0 "PASS" ;
VAL_ 2035 EPAS3P_matrixIndex 2 "AlertMatrix2" 1 "AlertMatrix1" 0 "AlertMatrix0" ;
VAL_ 977 EPAS3P_resyncStatus 1 "RESYNC_COMPLETE" 0 "RESYNC_PENDING" ;
VAL_ 817 EPAS3P_infoIndex 255 "END" 31 "SUBCOMPONENT_GITHASH" 30 "PACKAGE_SN_8_14" 29 "PACKAGE_SN_1_7" 27 "PACKAGE_PN_15_20" 26 "PACKAGE_PN_8_14" 25 "PACKAGE_PN_1_7" 23 "SUBCOMPONENT2" 22 "VARIANTCRC" 20 "UDS_PROTOCOL_BOOTCRC" 19 "VERSION_DEPRECATED" 18 "BOOTLOADER_GITHASH" 17 "APP_GITHASH" 16 "SUBCOMPONENT" 15 "BOOTLOADER_CRC" 14 "BOOTLOADER_SVN" 13 "APP_CRC" 11 "PCBAID_ASSYID_USAGEID" 10 "BUILD_HWID_COMPONENTID" 9 "DEPRECATED_9" 8 "DEPRECATED_8" 7 "DEPRECATED_7" 6 "DEPRECATED_6" 5 "DEPRECATED_5" 4 "DEPRECATED_4" 3 "DEPRECATED_3" 2 "DEPRECATED_2" 1 "DEPRECATED_1" 0 "DEPRECATED_0" ;
VAL_ 817 EPAS3P_infoBuildType 4 "INFO_MFG_BUILD" 3 "INFO_TRACEABLE_CI_BUILD" 2 "INFO_LOCAL_BUILD" 1 "INFO_PLATFORM_BUILD" 0 "INFO_UNKNOWN_BUILD" ;
VAL_ 883 EPAS3P_steeringRackForce 1023 "SNA" 1022 "NOT_IN_SPEC" ;
VAL_ 883 EPAS3P_steeringFault 1 "FAULT" 0 "NO_FAULT" ;
VAL_ 883 EPAS3P_steeringReduced 1 "REDUCED_ASSIST" 0 "NORMAL_ASSIST" ;
VAL_ 883 EPAS3P_internalSASQF 1 "IN_SPEC" 0 "UNDEFINABLE_ACCURACY" ;
VAL_ 883 EPAS3P_currentTuneMode 5 "STEERING_TUNE_RWD_SPORT" 4 "STEERING_TUNE_RWD_STANDARD" 3 "STEERING_TUNE_RWD_COMFORT" 2 "STEERING_TUNE_DM_SPORT" 1 "STEERING_TUNE_DM_STANDARD" 0 "STEERING_TUNE_DM_COMFORT" ;
VAL_ 883 EPAS3P_torsionBarTorque 4095 "SNA" 4094 "UNDEFINABLE_DATA" ;
VAL_ 883 EPAS3P_eacErrorCode 15 "SNA" 14 "EAC_EXTERNAL_MONITOR_INHIBIT" 13 "EAC_ERROR_PINION_VEL_DIFF" 12 "EAC_ERROR_LOW_ASSIST" 11 "EAC_ERROR_HIGH_TORSION_SAFETY" 10 "EAC_ERROR_HIGH_MMOT_SAFETY" 9 "EAC_ERROR_HIGH_ANGLE_RATE_SAFETY" 8 "EAC_ERROR_HIGH_ANGLE_SAFETY" 7 "EAC_ERROR_HIGH_ANGLE_RATE_REQ" 6 "EAC_ERROR_HIGH_ANGLE_REQ" 5 "EAR_ERROR_MAX_STEER_DELTA" 4 "EAC_ERROR_TMP_FAULT" 3 "EAC_ERROR_HANDS_ON" 2 "EAC_ERROR_MAX_SPEED" 1 "EAC_ERROR_MIN_SPEED" 0 "EAC_ERROR_IDLE" ;
VAL_ 883 EPAS3P_handsOnLevel 3 "LEVEL_3" 2 "LEVEL_2" 1 "LEVEL_1" 0 "LEVEL_0" ;
VAL_ 883 EPAS3P_driverlessState 1 "EAC_DRIVERLESS_ACTIVE" 0 "EAC_DRIVERLESS_INACTIVE" ;
VAL_ 883 EPAS3P_eacStatus 7 "EAC_ELK_ACTIVE" 6 "EAC_ELK_AVAILABLE" 5 "EAC_LKA_ACTIVE" 4 "EAC_LKA_ELK_AVAILABLE" 3 "EAC_FAULT" 2 "EAC_ACTIVE" 1 "EAC_AVAILABLE" 0 "EAC_INHIBITED" ;
VAL_ 1425 EPAS3S_alertID 168 "a168_torsionBarTorqueQfDegraded" 167 "a167_epbStatusCsError" 166 "a166_epbStatusCntError" 165 "a165_epbStatusMia" 164 "a164_initTestDCSInfo" 163 "a163_initTestGateDrvrInfo" 162 "a162_initTestHSDFetInfo" 161 "a161_initTestPhaDisconnInfo" 160 "a160_latentFaultTestResult" 159 "a159_pmState2CsError" 158 "a158_pmState2CntError" 157 "a157_pmState2Mia" 156 "a156_angleSensorDivergence" 155 "a155_backupEacActive" 154 "a154_assistTorqueDisabled" 153 "a153_dcsInitOffset" 152 "a152_dcsDiagReg" 151 "a151_dcsCboot" 150 "a150_currentSensOffsetDetect" 149 "a149_currentSensPathSwitch" 148 "a148_vMaxAssist" 147 "a147_backupVehSpeed" 146 "a146_diSpdCsError" 145 "a145_diSpdCntError" 144 "a144_diSpdMia" 137 "a137_piCtrlCounter85" 136 "a136_piCtrlCounter50" 135 "a135_piCtrlCounter25" 134 "a134_motFeedFwdCounter85" 133 "a133_motFeedFwdCounter50" 132 "a132_motFeedFwdCounter25" 131 "a131_phaseFeedbackError" 130 "a130_sasOffsetNotCal" 129 "a129_combEcu1StatFail" 128 "a128_apsCsError" 127 "a127_apsCntError" 126 "a126_apsMia" 125 "a125_trqSensTrimOutRange" 124 "a124_tempSensStuckInRange" 123 "a123_combEcu2StatFail" 122 "a122_olpActive" 121 "a121_pvtEcuStatCrcError" 120 "a120_pvtEcuStatCntError" 119 "a119_pvtEcuStatMia" 118 "a118_privateBusOff" 117 "a117_ecuStatCrcError" 116 "a116_ecuStatCntError" 115 "a115_ecuStatMia" 114 "a114_gtwConfigMia" 113 "a113_sasStatusError" 112 "a112_sasCsError" 111 "a111_sasCntError" 110 "a110_sasMia" 109 "a109_uiTuneReqCsError" 108 "a108_uiTuneReqCntError" 107 "a107_uiTuneReqMia" 106 "a106_vcFrontTempMia" 105 "a105_vcFrontCsError" 104 "a104_vcFrontCntError" 103 "a103_vcFrontMia" 102 "a102_diCsError" 101 "a101_diCntError" 100 "a100_diMia" 99 "a099_yawRateStatus" 98 "a098_rcmCsError" 97 "a097_rcmCntError" 96 "a096_rcmMia" 95 "a095_espWsStatus" 94 "a094_espWrCsError" 93 "a093_espWrCntError" 92 "a092_espWrMia" 91 "a091_espWsCsError" 90 "a090_espWsCntError" 89 "a089_espWsMia" 88 "a088_dasCsError" 87 "a087_dasCntError" 86 "a086_dasMia" 85 "a085_canBusOff" 84 "a084_eacCancelled" 83 "a083_crcMismatch" 82 "a082_polarityCalError" 81 "a081_coggCompError" 80 "a080_ecuInitArbError" 79 "a079_backupCurrentPlaus" 78 "a078_phaseDisconnectError" 77 "a077_highSideFetError" 76 "a076_tempSensOutofRange" 75 "a075_fspPwrCut" 74 "a074_overHeatProtect" 73 "a073_motParEstError" 72 "a072_motFeedFwdError" 71 "a071_vehSpdCorrError" 70 "a070_hodCorrError" 69 "a069_eacCorrError" 68 "a068_hystCorrError" 67 "a067_yawDampCorrError" 66 "a066_returnCorrError" 65 "a065_trqTarCorrError" 64 "a064_phaseCompCorrError" 63 "a063_dampCorrError" 62 "a062_assistCorrError" 61 "a061_bridgeUv" 60 "a060_battBridgeDiff" 59 "a059_battOvReduced" 58 "a058_battOv" 57 "a057_battUvReduced" 56 "a056_battUv" 55 "a055_floatPointError" 54 "a054_memoryProtectError" 53 "a053_extWatchdogError" 52 "a052_intWatchdogError" 51 "a051_mcuSupError" 50 "a050_mcuSmuError" 49 "a049_piCtrlError" 48 "a048_motPosCalError" 47 "a047_motPosCorrError" 46 "a046_motPos2tempError" 45 "a045_motPos2LogicError" 44 "a044_motPos2MagnetMia" 43 "a043_motPos2Uv" 42 "a042_motPos2ParityError" 41 "a041_motPos1tempError" 40 "a040_motPos1LogicError" 39 "a039_motPos1MagnetMia" 38 "a038_motPos1Uv" 37 "a037_motPos1ParityError" 36 "a036_vbbSupplyOv" 35 "a035_vbbSupplyUv" 34 "a034_vRegError" 33 "a033_vRegOutputOv" 32 "a032_vRegOutputUv" 31 "a031_abnormalShutdown" 30 "a030_phaseWbootUv" 29 "a029_phaseVbootUv" 28 "a028_phaseUbootUv" 27 "a027_phaseWlowOv" 26 "a026_phaseWhighOv" 25 "a025_phaseVlowOv" 24 "a024_phaseVhighOv" 23 "a023_phaseUlowOv" 22 "a022_phaseUhighOv" 21 "a021_phaseWlowUv" 20 "a020_phaseWhighUv" 19 "a019_phaseVlowUv" 18 "a018_phaseVhighUv" 17 "a017_phaseUlowUv" 16 "a016_phaseUhighUv" 15 "a015_gateDriveEeprom" 14 "a014_gateDriveTxError" 13 "a013_gateDriveError" 12 "a012_currentSensCalError" 11 "a011_currentSensError" 10 "a010_trqSensCalError" 9 "a009_sentDiff" 8 "a008_trqSens2Eeprom" 7 "a007_trqSens2Supply" 6 "a006_sent2Error" 5 "a005_sent2Mia" 4 "a004_trqSens1Eeprom" 3 "a003_trqSens1Supply" 2 "a002_sent1Error" 1 "a001_sent1Mia" 0 "ALERT_DO_NOT_USE_ZERO" ;
VAL_ 1425 EPAS3S_alertState 1 "SET" 0 "CLEARED" ;
VAL_ 1425 EPAS3S_a147_transitionReason 2 "MIA" 1 "WSS_FAILURE" 0 "DATA_INTEGRITY" ;
VAL_ 1425 EPAS3S_a160_currentSensorStatus 2 "STATUS_UNKNOWN" 1 "PROBABLE_FAILURE" 0 "NO_ISSUE" ;
VAL_ 1425 EPAS3S_a160_gateDriverStatus 2 "STATUS_UNKNOWN" 1 "PROBABLE_FAILURE" 0 "NO_ISSUE" ;
VAL_ 1425 EPAS3S_a160_highSideDisconnectFe 2 "STATUS_UNKNOWN" 1 "PROBABLE_FAILURE" 0 "NO_ISSUE" ;
VAL_ 1425 EPAS3S_a160_phaseDisconnectFetSt 2 "STATUS_UNKNOWN" 1 "PROBABLE_FAILURE" 0 "NO_ISSUE" ;
VAL_ 1425 EPAS3S_a160_inverterFetStatus 2 "STATUS_UNKNOWN" 1 "PROBABLE_FAILURE" 0 "NO_ISSUE" ;
VAL_ 1425 EPAS3S_a160_hsdFetFailShortTest 2 "NOT_RAN" 1 "FAIL" 0 "PASS" ;
VAL_ 1425 EPAS3S_a160_phaDisconnFailOpenTe 2 "NOT_RAN" 1 "FAIL" 0 "PASS" ;
VAL_ 1425 EPAS3S_a160_phaDisconnFailShortT 2 "NOT_RAN" 1 "FAIL" 0 "PASS" ;
VAL_ 1425 EPAS3S_a160_invFetInitTest 2 "NOT_RAN" 1 "FAIL" 0 "PASS" ;
VAL_ 1425 EPAS3S_a160_gateDrvrInitTest 2 "NOT_RAN" 1 "FAIL" 0 "PASS" ;
VAL_ 913 EPAS3S_matrixIndex 2 "AlertMatrix2" 1 "AlertMatrix1" 0 "AlertMatrix0" ;
VAL_ 980 EPAS3S_resyncStatus 1 "RESYNC_COMPLETE" 0 "RESYNC_PENDING" ;
